VERSION "0.2"

NS_ :

BS_:

BU_: IFV_CWMP IFV_VFP External ExternalX
VAL_TABLE_ Status_Vision_Calib_Process_e 8 "DES_BAD_PARAMS_TARGET_HORIZON" 7 "DES_BAD_PARAMS_TARGET_YAW" 6 "DES_TOO_MANY_TARGETS_FOUND" 5 "DES_BAD_PARAMS" 4 "DES_BAD_PARAMS_SQUARE_SIDE_SIZE" 3 "DES_BAD_PARAMS_DISTANCE" 2 "DES_NO_TARGET_FOUND" 1 "DES_SUCCESS" 0 "DES_VISION_CALIB_UNKNOWN" ;
VAL_TABLE_ Vision_Align_State_T 4 "eVISION_APP_MODE" 3 "eWAIT_ALIGN_MSG" 2 "eWAIT_ALIGN_STATE" 1 "eVISION_UNALIGNED" 0 "eALIGNED_IDLE" ;
VAL_TABLE_ Mesp_Return_Status_T 5 "eDES_MESP_STATUS_ILLEGAL_CALL " 4 "eDES_STATUS_SERVICE_INVALID " 3 "eDES_STATUS_INVALID_PARAMETER" 2 "eDES_MESP_BUSY " 1 "eDES_MESP_GENERAL_ERR " 0 "eDES_MESP_STATUS_OK " ;
VAL_TABLE_ Mesp_MainState_T 134 "eMAIN_STATE_RUNNING_DIAGNOSTICS " 132 "eMAIN_STATE_PENDING_SPC " 130 "eMAIN_STATE_PENDING_TAC " 128 "eMAIN_STATE_PENDING_VISION " 34 "eRUNNING_SPC " 32 "eRUNNING_TAC " 3 "eBOOT " 2 "eRUNNING_VISON " 1 "ePENDING " 0 "eUKNOWN" ;

BO_ 3221225472 VECTOR__INDEPENDENT_SIG_MSG: 0 Vector__XXX
 SG_ Version_Info_MessageCounter : 0|2@1+ (1,0) [0|3] "" Vector__XXX
 SG_ CAN_Interface_Major_Version : 0|5@1+ (1,0) [0|255] "" Vector__XXX
 SG_ CAN_Interface_Minor_Version : 0|3@1+ (1,0) [0|255] "" Vector__XXX
 SG_ VIS_LANE_AMBIGUOUS_LANE_RIGHT : 0|1@1+ (1,0) [0|1] "" Vector__XXX
 SG_ VIS_LANE_AMBIGUOUS_LANE_LEFT : 0|1@1+ (1,0) [0|1] "" Vector__XXX
 SG_ VIS_LANE_LANE_CHANGE : 0|2@1+ (1,0) [0|3] "" Vector__XXX
 SG_ VIS_LANE_RIGHT_INDIVID_TJACONF : 0|2@1+ (1,0) [0|2] "" Vector__XXX
 SG_ VIS_LANE_RIGHT_INDIVID_LKACONF : 0|2@1+ (1,0) [0|2] "" Vector__XXX
 SG_ VIS_LANE_RIGHT_INDIVID_DIMONCONF : 0|1@1+ (1,0) [0|1] "" Vector__XXX
 SG_ VIS_LANE_RIGHT_PARALL_TJACONF : 0|2@1+ (1,0) [0|2] "" Vector__XXX
 SG_ VIS_LANE_RIGHT_PARALL_LKACONF : 0|2@1+ (1,0) [0|2] "" Vector__XXX
 SG_ VIS_LANE_RIGHT_PARALL_DIMONCONF : 0|1@1+ (1,0) [0|1] "" Vector__XXX
 SG_ VIS_LANE_LEFT_INDIVID_TJACONF : 0|2@1+ (1,0) [0|2] "" Vector__XXX
 SG_ VIS_LANE_LEFT_INDIVID_LKACONF : 0|2@1+ (1,0) [0|2] "" Vector__XXX
 SG_ VIS_LANE_LEFT_INDIVID_DIMONCONF : 0|1@1+ (1,0) [0|1] "" Vector__XXX
 SG_ VIS_LANE_LEFT_PARALL_TJACONF : 0|2@1+ (1,0) [0|2] "" Vector__XXX
 SG_ VIS_LANE_LEFT_PARALL_LKACONF : 0|2@1+ (1,0) [0|2] "" Vector__XXX
 SG_ VIS_LANE_LEFT_PARALL_DIMONCONF : 0|1@1+ (1,0) [0|1] "" Vector__XXX
 SG_ VIS_LANE_RIGHT_PARALL_TYPE : 0|4@1+ (1,0) [0|8] "" Vector__XXX
 SG_ VIS_LANE_RIGHT_INDIVID_TYPE : 0|4@1+ (1,0) [0|8] "" Vector__XXX
 SG_ VIS_LANE_LEFT_PARALL_TYPE : 0|4@1+ (1,0) [0|8] "" Vector__XXX
 SG_ VIS_LANE_LEFT_INDIVID_TYPE : 0|4@1+ (1,0) [0|8] "" Vector__XXX
 SG_ VIS_AHBC_CLOSEST_OBJECT_DISTANCE : 0|8@1+ (2,0) [0|510] "m" Vector__XXX
 SG_ VIS_AHBC_BOUND_NOGLARE_RIGHT_ST : 0|2@1+ (1,0) [0|3] "" Vector__XXX
 SG_ VIS_AHBC_BOUND_NOGLARE_RIGHT : 0|8@1+ (0.1,-20) [-20|20] "deg" Vector__XXX
 SG_ VIS_AHBC_BOUND_NOGLARE_LEFT_ST : 0|2@1+ (1,0) [0|3] "" Vector__XXX
 SG_ VIS_AHBC_BOUND_NOGLARE_LEFT : 0|12@1+ (0.1,-20) [-20|20] "deg" Vector__XXX
 SG_ VIS_AHBC_BOUND_NOGLARE_BTM_ST : 0|2@1+ (1,0) [0|3] "" Vector__XXX
 SG_ VIS_AHBC_BOUND_NOGLARE_BTM : 0|8@1+ (0.1,-10) [-10|10] "deg" Vector__XXX
 SG_ Latch_Fault_byte19_bit3 : 0|1@1+ (1,0) [0|1] "" Vector__XXX
 SG_ Latch_Fault_byte20_bit0 : 0|1@1+ (1,0) [0|1] "" Vector__XXX
 SG_ Latch_Fault_byte19_bit7 : 0|1@1+ (1,0) [0|0] "" Vector__XXX
 SG_ Latch_Fault_byte19_bit6 : 0|1@1+ (1,0) [0|1] "" Vector__XXX
 SG_ Latch_Fault_byte19_bit5 : 0|1@1+ (1,0) [0|1] "" Vector__XXX
 SG_ Latch_Fault_byte19_bit4 : 0|1@1+ (1,0) [0|1] "" Vector__XXX
 SG_ Latch_Fault_byte19_bit2 : 0|1@1+ (1,0) [0|0] "" Vector__XXX
 SG_ Latch_Fault_byte19_bit1 : 0|1@1+ (1,0) [0|0] "" Vector__XXX
 SG_ Latch_Fault_byte19_bit0 : 0|1@1+ (1,0) [0|0] "" Vector__XXX
 SG_ Latch_Fault_byte18_bit0 : 0|1@1+ (1,0) [0|1] "" Vector__XXX
 SG_ Latch_Fault_byte18_bit1 : 0|1@1+ (1,0) [0|1] "" Vector__XXX
 SG_ Latch_Fault_byte18_bit2 : 0|1@1+ (1,0) [0|1] "" Vector__XXX
 SG_ Latch_Fault_byte18_bit3 : 0|1@1+ (1,0) [0|1] "" Vector__XXX
 SG_ LaActlDeny_B_ActlQfError : 0|1@1+ (1,0) [0|1] "" Vector__XXX
 SG_ Latch_Fault_byte18_bit5 : 0|1@1+ (1,0) [0|1] "" Vector__XXX
 SG_ Latch_Fault_byte18_bit6 : 0|1@1+ (1,0) [0|1] "" Vector__XXX
 SG_ Latch_Fault_byte18_bit7 : 0|1@1+ (1,0) [0|1] "" Vector__XXX
 SG_ Latch_Fault_byte17_bit0 : 0|1@1+ (1,0) [0|1] "" Vector__XXX
 SG_ Latch_Fault_byte17_bit1 : 0|1@1+ (1,0) [0|1] "" Vector__XXX
 SG_ Latch_Fault_byte17_bit2 : 0|1@1+ (1,0) [0|1] "" Vector__XXX
 SG_ Latch_Fault_byte17_bit3 : 0|1@1+ (1,0) [0|1] "" Vector__XXX
 SG_ Latch_Fault_byte17_bit4 : 0|1@1+ (1,0) [0|1] "" Vector__XXX
 SG_ Latch_Fault_byte17_bit5 : 0|1@1+ (1,0) [0|1] "" Vector__XXX
 SG_ Latch_Fault_byte17_bit6 : 0|1@1+ (1,0) [0|1] "" Vector__XXX
 SG_ Latch_Fault_byte17_bit7 : 0|1@1+ (1,0) [0|1] "" Vector__XXX
 SG_ Latch_Fault_byte16_bit0 : 0|1@1+ (1,0) [0|1] "" Vector__XXX
 SG_ Latch_Fault_byte16_bit1 : 0|1@1+ (1,0) [0|1] "" Vector__XXX
 SG_ Latch_Fault_byte16_bit2 : 0|1@1+ (1,0) [0|1] "" Vector__XXX
 SG_ Latch_Fault_byte16_bit3 : 0|1@1+ (1,0) [0|1] "" Vector__XXX
 SG_ Latch_Fault_byte16_bit4 : 0|1@1+ (1,0) [0|1] "" Vector__XXX
 SG_ Latch_Fault_byte16_bit5 : 0|1@1+ (1,0) [0|1] "" Vector__XXX
 SG_ Latch_Fault_byte16_bit6 : 0|1@1+ (1,0) [0|1] "" Vector__XXX
 SG_ Latch_Fault_byte16_bit7 : 0|1@1+ (1,0) [0|1] "" Vector__XXX
 SG_ Latch_Fault_byte15_bit0 : 0|1@1+ (1,0) [0|1] "" Vector__XXX
 SG_ Latch_Fault_byte15_bit1 : 0|1@1+ (1,0) [0|1] "" Vector__XXX
 SG_ Latch_Fault_byte15_bit2 : 0|1@1+ (1,0) [0|1] "" Vector__XXX
 SG_ Latch_Fault_byte15_bit3 : 0|1@1+ (1,0) [0|1] "" Vector__XXX
 SG_ Latch_Fault_byte15_bit4 : 0|1@1+ (1,0) [0|1] "" Vector__XXX
 SG_ Latch_Fault_byte15_bit5 : 0|1@1+ (1,0) [0|1] "" Vector__XXX
 SG_ Latch_Fault_byte15_bit6 : 0|1@1+ (1,0) [0|1] "" Vector__XXX
 SG_ Latch_Fault_byte15_bit7 : 0|1@1+ (1,0) [0|1] "" Vector__XXX
 SG_ Latch_Fault_byte14_bit0 : 0|1@1+ (1,0) [0|1] "" Vector__XXX
 SG_ Latch_Fault_byte14_bit1 : 0|1@1+ (1,0) [0|1] "" Vector__XXX
 SG_ Latch_Fault_byte14_bit1 : 0|1@1+ (1,0) [0|1] "" Vector__XXX
 SG_ Latch_Fault_byte14_bit3 : 0|1@1+ (1,0) [0|1] "" Vector__XXX
 SG_ Latch_Fault_byte14_bit4 : 0|1@1+ (1,0) [0|1] "" Vector__XXX
 SG_ Latch_Fault_byte14_bit5 : 0|1@1+ (1,0) [0|1] "" Vector__XXX
 SG_ Latch_Fault_byte14_bit6 : 0|1@1+ (1,0) [0|1] "" Vector__XXX
 SG_ Latch_Fault_byte14_bit7 : 0|1@1+ (1,0) [0|1] "" Vector__XXX
 SG_ Active_Fault_byte20_bit0 : 0|1@1+ (1,0) [0|1] "" Vector__XXX
 SG_ Active_Fault_byte19_bit7 : 0|1@1+ (1,0) [0|0] "" Vector__XXX
 SG_ Active_Fault_byte19_bit6 : 0|1@1+ (1,0) [0|1] "" Vector__XXX
 SG_ Active_Fault_byte19_bit5 : 0|1@1+ (1,0) [0|1] "" Vector__XXX
 SG_ Active_Fault_byte19_bit4 : 0|1@1+ (1,0) [0|1] "" Vector__XXX
 SG_ Active_Fault_byte19_bit3 : 0|1@1+ (1,0) [0|1] "" Vector__XXX
 SG_ Active_Fault_byte19_bit2 : 0|1@1+ (1,0) [0|0] "" Vector__XXX
 SG_ Active_Fault_byte19_bit1 : 0|1@1+ (1,0) [0|0] "" Vector__XXX
 SG_ Active_Fault_byte19_bit0 : 0|1@1+ (1,0) [0|0] "" Vector__XXX
 SG_ Active_Fault_byte18_bit0 : 0|1@1+ (1,0) [0|1] "" Vector__XXX
 SG_ Active_Fault_byte18_bit1 : 0|1@1+ (1,0) [0|1] "" Vector__XXX
 SG_ Active_Fault_byte18_bit2 : 0|1@1+ (1,0) [0|1] "" Vector__XXX
 SG_ Active_Fault_byte18_bit3 : 0|1@1+ (1,0) [0|1] "" Vector__XXX
 SG_ Active_Fault_byte18_bit4 : 0|1@1+ (1,0) [0|1] "" Vector__XXX
 SG_ Active_Fault_byte18_bit5 : 0|1@1+ (1,0) [0|1] "" Vector__XXX
 SG_ Active_Fault_byte18_bit6 : 0|1@1+ (1,0) [0|1] "" Vector__XXX
 SG_ Active_Fault_byte18_bit7 : 0|1@1+ (1,0) [0|1] "" Vector__XXX
 SG_ Active_Fault_byte17_bit0 : 0|1@1+ (1,0) [0|1] "" Vector__XXX
 SG_ Active_Fault_byte17_bit1 : 0|1@1+ (1,0) [0|1] "" Vector__XXX
 SG_ Active_Fault_byte17_bit2 : 0|1@1+ (1,0) [0|1] "" Vector__XXX
 SG_ Active_Fault_byte17_bit3 : 0|1@1+ (1,0) [0|1] "" Vector__XXX
 SG_ Active_Fault_byte17_bit4 : 0|1@1+ (1,0) [0|1] "" Vector__XXX
 SG_ Active_Fault_byte17_bit5 : 0|1@1+ (1,0) [0|1] "" Vector__XXX
 SG_ Active_Fault_byte17_bit6 : 0|1@1+ (1,0) [0|1] "" Vector__XXX
 SG_ Active_Fault_byte17_bit7 : 0|1@1+ (1,0) [0|1] "" Vector__XXX
 SG_ Active_Fault_byte16_bit0 : 0|1@1+ (1,0) [0|1] "" Vector__XXX
 SG_ Active_Fault_byte16_bit1 : 0|1@1+ (1,0) [0|1] "" Vector__XXX
 SG_ Active_Fault_byte16_bit2 : 0|1@1+ (1,0) [0|1] "" Vector__XXX
 SG_ Active_Fault_byte16_bit3 : 0|1@1+ (1,0) [0|1] "" Vector__XXX
 SG_ Active_Fault_byte16_bit4 : 0|1@1+ (1,0) [0|1] "" Vector__XXX
 SG_ Active_Fault_byte16_bit5 : 0|1@1+ (1,0) [0|1] "" Vector__XXX
 SG_ Active_Fault_byte16_bit6 : 0|1@1+ (1,0) [0|1] "" Vector__XXX
 SG_ Active_Fault_byte16_bit7 : 0|1@1+ (1,0) [0|1] "" Vector__XXX
 SG_ Active_Fault_byte15_bit0 : 0|1@1+ (1,0) [0|1] "" Vector__XXX
 SG_ Active_Fault_byte15_bit1 : 0|1@1+ (1,0) [0|1] "" Vector__XXX
 SG_ Active_Fault_byte15_bit2 : 0|1@1+ (1,0) [0|1] "" Vector__XXX
 SG_ Active_Fault_byte15_bit3 : 0|1@1+ (1,0) [0|1] "" Vector__XXX
 SG_ Active_Fault_byte15_bit4 : 0|1@1+ (1,0) [0|1] "" Vector__XXX
 SG_ Active_Fault_byte15_bit5 : 0|1@1+ (1,0) [0|1] "" Vector__XXX
 SG_ Active_Fault_byte15_bit6 : 0|1@1+ (1,0) [0|1] "" Vector__XXX
 SG_ Active_Fault_byte15_bit7 : 0|1@1+ (1,0) [0|1] "" Vector__XXX
 SG_ Active_Fault_byte14_bit0 : 0|1@1+ (1,0) [0|1] "" Vector__XXX
 SG_ Active_Fault_byte14_bit1 : 0|1@1+ (1,0) [0|1] "" Vector__XXX
 SG_ Active_Fault_byte14_bit2 : 0|1@1+ (1,0) [0|1] "" Vector__XXX
 SG_ Active_Fault_byte14_bit3 : 0|1@1+ (1,0) [0|1] "" Vector__XXX
 SG_ Active_Fault_byte14_bit4 : 0|1@1+ (1,0) [0|1] "" Vector__XXX
 SG_ Active_Fault_byte14_bit5 : 0|1@1+ (1,0) [0|1] "" Vector__XXX
 SG_ Active_Fault_byte14_bit6 : 0|1@1+ (1,0) [0|1] "" Vector__XXX
 SG_ Active_Fault_byte14_bit7 : 0|1@1+ (1,0) [0|1] "" Vector__XXX
 SG_ LKA_Handcode_diag : 0|1@1- (1,0) [0|1] "" Vector__XXX
 SG_ VBattState_VR_HTR : 0|4@1+ (1,0) [0|15] "" Vector__XXX
 SG_ RawHeatrFltA2D : 0|12@1+ (1,0) [0|4095] "" Vector__XXX
 SG_ RawHeaterOutA2D : 0|12@1+ (1,0) [0|4095] "" Vector__XXX
 SG_ HtrDrv : 0|1@1+ (1,0) [0|1] "" Vector__XXX
 SG_ HeaterSTGOpenFailure_HP : 0|1@1+ (1,0) [0|1] "" Vector__XXX
 SG_ HeaterOutputShortCircuit_HP : 0|1@1+ (1,0) [0|1] "" Vector__XXX
 SG_ HeaterOutpurOpenCircuit_HP : 0|1@1+ (1,0) [0|1] "" Vector__XXX
 SG_ heavy_rain_failsafe : 0|1@1+ (1,0) [0|1] "" Vector__XXX
 SG_ heavy_rain_failsafe_A : 0|1@1+ (1,0) [0|1] "" Vector__XXX
 SG_ History_Fault_bD_0 : 0|1@1+ (1,0) [0|1] "" Vector__XXX
 SG_ Active_Fault_byteD_bit0 : 0|1@1+ (1,0) [0|1] "" Vector__XXX
 SG_ Active_Fault_A_b21_5 : 0|1@1+ (1,0) [0|1] "" Vector__XXX
 SG_ Active_Fault_A_b21_6 : 0|1@1+ (1,0) [0|1] "" Vector__XXX
 SG_ Active_Fault_A_b21_7 : 0|1@1+ (1,0) [0|1] "" Vector__XXX
 SG_ History_Fault_H_b21_5 : 0|1@1+ (1,0) [0|1] "" Vector__XXX
 SG_ History_Fault_H_b21_6 : 0|1@1+ (1,0) [0|1] "" Vector__XXX
 SG_ History_Fault_H_b21_7 : 0|1@1+ (1,0) [0|1] "" Vector__XXX
 SG_ History_Fault_b1E_7 : 0|1@1+ (1,0) [0|1] "" Vector__XXX
 SG_ History_Fault_b1D_3 : 0|1@1+ (1,0) [0|1] "" Vector__XXX
 SG_ History_Fault_b1D_4 : 0|1@1+ (1,0) [0|1] "" Vector__XXX
 SG_ History_Fault_b1D_5 : 0|1@1+ (1,0) [0|1] "" Vector__XXX
 SG_ History_Fault_b1D_6 : 0|1@1+ (1,0) [0|1] "" Vector__XXX
 SG_ History_Fault_b1D_7 : 0|1@1+ (1,0) [0|1] "" Vector__XXX
 SG_ History_Fault_b1C_7 : 0|1@1+ (1,0) [0|1] "" Vector__XXX
 SG_ History_Fault_b1A_3 : 0|1@1+ (1,0) [0|1] "" Vector__XXX
 SG_ History_Fault_H_b18_3 : 0|1@1+ (1,0) [0|1] "" Vector__XXX
 SG_ History_Fault_H_b16_2 : 0|1@1+ (1,0) [0|1] "" Vector__XXX
 SG_ History_Fault_H_b14_1 : 0|1@1+ (1,0) [0|1] "" Vector__XXX
 SG_ History_Fault_H_b14_2 : 0|1@1+ (1,0) [0|1] "" Vector__XXX
 SG_ History_Fault_H_b14_3 : 0|1@1+ (1,0) [0|1] "" Vector__XXX
 SG_ History_Fault_H_b10_0 : 0|1@1+ (1,0) [0|1] "" Vector__XXX
 SG_ History_Fault_H_b10_4 : 0|1@1+ (1,0) [0|1] "" Vector__XXX
 SG_ History_Fault_H_b10_6 : 0|1@1+ (1,0) [0|1] "" Vector__XXX
 SG_ History_Fault_H_b10_7 : 0|1@1+ (1,0) [0|1] "" Vector__XXX
 SG_ History_Fault_b6_2 : 0|1@1+ (1,0) [0|1] "" Vector__XXX
 SG_ History_Fault_b6_4 : 0|1@1+ (1,0) [0|1] "" Vector__XXX
 SG_ History_Fault_b1_7 : 0|1@1+ (1,0) [0|1] "" Vector__XXX
 SG_ History_Fault_b0_0 : 0|1@1+ (1,0) [0|1] "" Vector__XXX
 SG_ Active_Fault_b1E_7 : 0|1@1+ (1,0) [0|1] "" Vector__XXX
 SG_ Active_Fault_b1D_3 : 0|1@1+ (1,0) [0|1] "" Vector__XXX
 SG_ Active_Fault_b1D_4 : 0|1@1+ (1,0) [0|1] "" Vector__XXX
 SG_ Active_Fault_b1D_5 : 0|1@1+ (1,0) [0|1] "" Vector__XXX
 SG_ Active_Fault_b1D_6 : 0|1@1+ (1,0) [0|1] "" Vector__XXX
 SG_ Active_Fault_b1D_7 : 0|1@1+ (1,0) [0|1] "" Vector__XXX
 SG_ Active_Fault_b1C_7 : 0|1@1+ (1,0) [0|1] "" Vector__XXX
 SG_ Active_Fault_b1A_3 : 0|1@1+ (1,0) [0|1] "" Vector__XXX
 SG_ Active_Fault_A_b18_3 : 0|1@1+ (1,0) [0|1] "" Vector__XXX
 SG_ Active_Fault_A_b16_2 : 0|1@1+ (1,0) [0|1] "" Vector__XXX
 SG_ Active_Fault_A_b14_1 : 0|1@1+ (1,0) [0|1] "" Vector__XXX
 SG_ Active_Fault_A_b14_2 : 0|1@1+ (1,0) [0|1] "" Vector__XXX
 SG_ Active_Fault_A_b14_3 : 0|1@1+ (1,0) [0|1] "" Vector__XXX
 SG_ Active_Fault_A_b10_0 : 0|1@1+ (1,0) [0|1] "" Vector__XXX
 SG_ Active_Fault_A_b10_4 : 0|1@1+ (1,0) [0|1] "" Vector__XXX
 SG_ Active_Fault_A_b10_6 : 0|1@1+ (1,0) [0|1] "" Vector__XXX
 SG_ Active_Fault_A_b10_7 : 0|1@1+ (1,0) [0|1] "" Vector__XXX
 SG_ Active_Fault_b6_2 : 0|1@1+ (1,0) [0|1] "" Vector__XXX
 SG_ Active_Fault_b6_4 : 0|1@1+ (1,0) [0|1] "" Vector__XXX
 SG_ Active_Fault_byte1_bit7 : 0|1@1+ (1,0) [0|1] "" Vector__XXX
 SG_ Active_Fault_byte0_bit0 : 0|1@1+ (1,0) [0|1] "" Vector__XXX
 SG_ History_Fault_H_bF_4 : 0|1@1+ (1,0) [0|1] "" Vector__XXX
 SG_ History_Fault_H_bF_5 : 0|1@1+ (1,0) [0|1] "" Vector__XXX
 SG_ History_Fault_H_bF_6 : 0|1@1+ (1,0) [0|1] "" Vector__XXX
 SG_ History_Fault_H_bF_7 : 0|1@1+ (1,0) [0|1] "" Vector__XXX
 SG_ History_Fault_H_bE_7 : 0|1@1+ (1,0) [0|1] "" Vector__XXX
 SG_ History_Fault_bD_1 : 0|1@1+ (1,0) [0|1] "" Vector__XXX
 SG_ History_Fault_bD_2 : 0|1@1+ (1,0) [0|1] "" Vector__XXX
 SG_ History_Fault_bC_0 : 0|1@1+ (1,0) [0|1] "" Vector__XXX
 SG_ History_Fault_H_bC_1 : 0|1@1+ (1,0) [0|1] "" Vector__XXX
 SG_ History_Fault_bC_4 : 0|1@1+ (1,0) [0|1] "" Vector__XXX
 SG_ History_Fault_bC_7 : 0|1@1+ (1,0) [0|1] "" Vector__XXX
 SG_ History_Fault_bB_7 : 0|1@1+ (1,0) [0|1] "" Vector__XXX
 SG_ History_Fault_b9_4 : 0|1@1+ (1,0) [0|1] "" Vector__XXX
 SG_ History_Fault_b9_6 : 0|1@1+ (1,0) [0|1] "" Vector__XXX
 SG_ History_Fault_b8_0 : 0|1@1+ (1,0) [0|1] "" Vector__XXX
 SG_ History_Fault_b8_1 : 0|1@1+ (1,0) [0|1] "" Vector__XXX
 SG_ History_Fault_b8_2 : 0|1@1+ (1,0) [0|1] "" Vector__XXX
 SG_ Active_Fault_A_bF_4 : 0|1@1+ (1,0) [0|1] "" Vector__XXX
 SG_ Active_Fault_A_bF_5 : 0|1@1+ (1,0) [0|1] "" Vector__XXX
 SG_ Active_Fault_A_bF_6 : 0|1@1+ (1,0) [0|1] "" Vector__XXX
 SG_ Active_Fault_A_bF_7 : 0|1@1+ (1,0) [0|1] "" Vector__XXX
 SG_ Active_Fault_A_bE_7 : 0|1@1+ (1,0) [0|1] "" Vector__XXX
 SG_ Active_Fault_byteD_bit1 : 0|1@1+ (1,0) [0|1] "" Vector__XXX
 SG_ Active_Fault_byteD_bit2 : 0|1@1+ (1,0) [0|1] "" Vector__XXX
 SG_ Active_Fault_bC_0 : 0|1@1+ (1,0) [0|1] "" Vector__XXX
 SG_ Active_Fault_A_bC_1 : 0|1@1+ (1,0) [0|1] "" Vector__XXX
 SG_ Active_Fault_byteC_bit4 : 0|1@1+ (1,0) [0|1] "" Vector__XXX
 SG_ Active_Fault_byteC_bit7 : 0|1@1+ (1,0) [0|1] "" Vector__XXX
 SG_ Active_Fault_bB_7 : 0|1@1+ (1,0) [0|1] "" Vector__XXX
 SG_ Active_Fault_b9_4 : 0|1@1+ (1,0) [0|1] "" Vector__XXX
 SG_ Active_Fault_b9_6 : 0|1@1+ (1,0) [0|1] "" Vector__XXX
 SG_ Active_Fault_byte8_bit0 : 0|1@1+ (1,0) [0|1] "" Vector__XXX
 SG_ Active_Fault_byte8_bit1 : 0|1@1+ (1,0) [0|1] "" Vector__XXX
 SG_ Active_Fault_byte8_bit2 : 0|1@1+ (1,0) [0|1] "" Vector__XXX
 SG_ PB_185_VehStbMiss_H_b15_1 : 0|1@1+ (1,0) [0|1] "" Vector__XXX
 SG_ PB_185_VehStbMiss_A_b15_1 : 0|1@1+ (1,0) [0|1] "" Vector__XXX

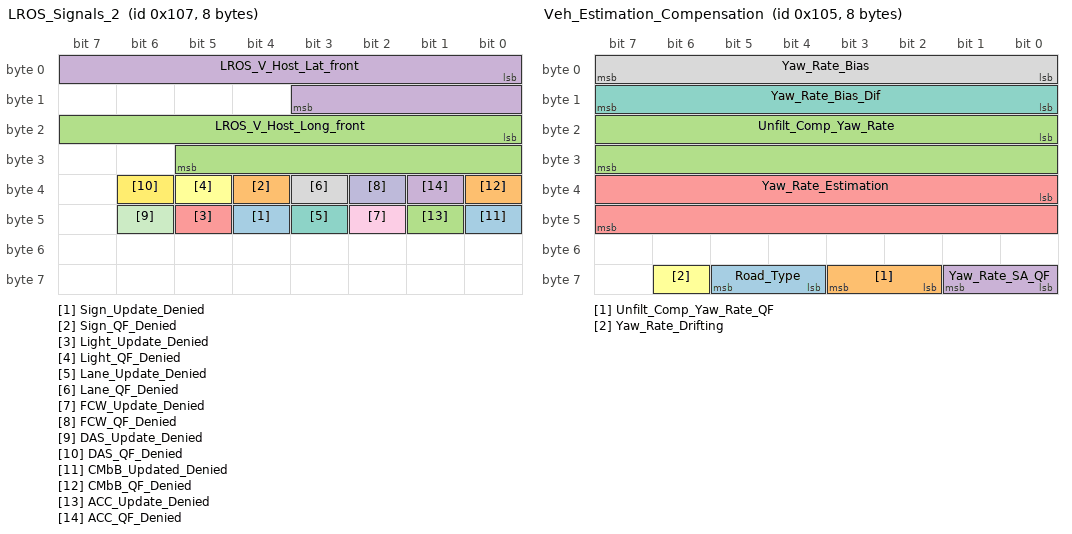
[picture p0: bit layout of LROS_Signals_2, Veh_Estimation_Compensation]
BO_ 263 LROS_Signals_2: 8 IFV_CWMP
 SG_ Sign_Update_Denied : 44|1@1+ (1,0) [0|1] ""  External
 SG_ Sign_QF_Denied : 36|1@1+ (1,0) [0|1] ""  External
 SG_ LROS_V_Host_Long_front : 16|14@1- (0.01,0) [-20|100] "m/s"  External
 SG_ LROS_V_Host_Lat_front : 0|12@1- (0.01,0) [-20|20] "m/s"  External
 SG_ Light_Update_Denied : 45|1@1+ (1,0) [0|1] ""  External
 SG_ Light_QF_Denied : 37|1@1+ (1,0) [0|1] ""  External
 SG_ Lane_Update_Denied : 43|1@1+ (1,0) [0|1] ""  External
 SG_ Lane_QF_Denied : 35|1@1+ (1,0) [0|1] ""  External
 SG_ FCW_Update_Denied : 42|1@1+ (1,0) [0|1] ""  External
 SG_ FCW_QF_Denied : 34|1@1+ (1,0) [0|1] ""  External
 SG_ DAS_Update_Denied : 46|1@1+ (1,0) [0|1] ""  External
 SG_ DAS_QF_Denied : 38|1@1+ (1,0) [0|1] ""  External
 SG_ CMbB_Updated_Denied : 40|1@1+ (1,0) [0|1] ""  External
 SG_ CMbB_QF_Denied : 32|1@1+ (1,0) [0|1] ""  External
 SG_ ACC_Update_Denied : 41|1@1+ (1,0) [0|1] ""  External
 SG_ ACC_QF_Denied : 33|1@1+ (1,0) [0|1] ""  External

BO_ 262 LROS_Signals_1: 8 IFV_CWMP
 SG_ LROSStatus_bit2 : 50|1@1+ (1,0) [0|1] ""  External
 SG_ LROSStatus_bit10 : 58|1@1+ (1,0) [0|1] ""  External
 SG_ VisionAlignmentOutOfRange : 52|1@1+ (1,0) [0|1] ""  External
 SG_ VisionSystemNotOperational : 49|1@1+ (1,0) [0|1] ""  External
 SG_ VisionExternalConditionsNotOK : 59|1@1+ (1,0) [0|1] ""  External
 SG_ VisionBlockageDetected : 54|1@1+ (1,0) [0|1] ""  External
 SG_ VisionAlignmentNotStarted : 63|1@1+ (1,0) [0|1] ""  External
 SG_ VisionAlignmentIncomplete : 62|1@1+ (1,0) [0|1] ""  External
 SG_ SensorDataUpdating : 55|1@1+ (1,0) [0|1] ""  External
 SG_ RadarExternalConditionsNotOK : 57|1@1+ (1,0) [0|1] ""  External
 SG_ RadarBlockageDetected : 53|1@1+ (1,0) [0|1] ""  External
 SG_ RadarAlignmentOutOfRange : 51|1@1+ (1,0) [0|1] ""  External
 SG_ RadarAlignmentNotStarted : 61|1@1+ (1,0) [0|1] ""  External
 SG_ RadarAlignmentIncomplete : 60|1@1+ (1,0) [0|1] ""  External
 SG_ CommunicationError : 56|1@1+ (1,0) [0|1] ""  External
 SG_ RadarSystemNotOperational : 48|1@1+ (1,0) [0|1] ""  External
 SG_ LROS_YawRate_Est : 32|15@1- (0.000174533,0) [-2|2] "rad/s"  External
 SG_ LROS_YawRate : 16|15@1- (0.000174533,0) [-2|2] "rad/s"  External
 SG_ LROS_FiltVehicleSpeedOverGround : 0|14@1+ (0.01,0) [0|100] "m/s"  External

BO_ 261 Veh_Estimation_Compensation: 8 IFV_CWMP
 SG_ Road_Type : 60|2@1+ (1,0) [0|3] ""  External
 SG_ Unfilt_Comp_Yaw_Rate_QF : 58|2@1+ (1,0) [0|3] ""  External
 SG_ Unfilt_Comp_Yaw_Rate : 16|16@1- (0.00306,0) [-100|100.26702] "deg/s"  External
 SG_ Yaw_Rate_SA_QF : 56|2@1+ (1,0) [0|3] ""  External
 SG_ Yaw_Rate_Estimation : 32|16@1- (0.00306,0) [-100.27008|100.26702] "deg/s"  External
 SG_ Yaw_Rate_Drifting : 62|1@1+ (1,0) [0|1] ""  External
 SG_ Yaw_Rate_Bias_Dif : 8|8@1- (0.015625,0) [-2|1.984375] "deg/s"  External
 SG_ Yaw_Rate_Bias : 0|8@1- (0.0273,0) [-3.4944|3.4671] "deg/s"  External

BO_ 1796 DASP_Counters: 8 IFV_VFP
 SG_ VfpSpiMsgRxBadSeqCtr : 40|8@1+ (1,0) [0|255] ""  External
 SG_ VfpSpiMsgRxBadHdrCtr : 32|8@1+ (1,0) [0|255] ""  External
 SG_ VfpSpiMsg11RxCtr : 16|16@1+ (1,0) [0|65535] ""  External
 SG_ VfpSpiMsg10RxCtr : 0|16@1+ (1,0) [0|65535] ""  External

BO_ 526 Host_CAN_Output_Timestamp: 8 IFV_CWMP
 SG_ CAN_LROS_TRIGGER_TIMESTAMP_LSB : 0|28@1+ (1,0) [0|268435455] ""  External
 SG_ CAN_LROS_T_TRACKER_INDEX_LSB : 40|12@1+ (1,0) [0|4095] ""  External
 SG_ CAN_LROS_T_LOOK_INDEX_LSB : 52|12@1+ (1,0) [0|4095] ""  External
 SG_ CAN_LROS_T_FRAME_INDEX_LSB : 28|12@1+ (1,0) [0|4095] ""  External

BO_ 525 Host_LROS_Trigger_Timestamp: 8 IFV_CWMP
 SG_ CAN_LROS_OUTPUT_TIMESTAMP_LSB : 0|28@1+ (1,0) [0|268435455] ""  External
 SG_ CAN_LROS_O_TRACKER_INDEX_LSB : 40|12@1+ (1,0) [0|4095] ""  External
 SG_ CAN_LROS_O_LOOK_INDEX_LSB : 52|12@1+ (1,0) [0|4095] ""  External
 SG_ CAN_LROS_O_FRAME_INDEX_LSB : 28|12@1+ (1,0) [0|4095] ""  External

BO_ 570 IPC_Vis_Function_Msg_Host_TS: 8 IFV_VFP
 SG_ CAN_IPC_TIMESTAMP_VIS_H : 32|32@1+ (1,0) [0|4294967295] "ms"  External
 SG_ CAN_IPC_REF_INDEX_VIS_H : 16|16@1+ (1,0) [0|65535] ""  External
 SG_ CAN_IPC_REF_INDEX_2_VIS_H : 0|16@1+ (1,0) [0|65535] ""  External

BO_ 568 IPC_Tsel_Msg_Host_TS: 8 IFV_VFP
 SG_ CAN_IPC_TIMESTAMP_TSEL_H : 32|32@1+ (1,0) [0|4294967295] "ms"  External
 SG_ CAN_IPC_REF_INDEX_TSEL_H : 16|16@1+ (1,0) [0|65535] ""  External
 SG_ CAN_IPC_REF_INDEX_2_TSEL_H : 0|16@1+ (1,0) [0|65535] ""  External

BO_ 567 IPC_TrafficSigns_Msg_Host_TS: 8 IFV_VFP
 SG_ CAN_IPC_TIMESTAMP_TRAFF_H : 32|32@1+ (1,0) [0|4294967295] "ms"  External
 SG_ CAN_IPC_REF_INDEX_TRAFF_H : 16|16@1+ (1,0) [0|65535] ""  External
 SG_ CAN_IPC_REF_INDEX_2_TRAFF_H : 0|16@1+ (1,0) [0|65535] ""  External

BO_ 566 IPC_RoadData_msg_Host_TS: 8 IFV_VFP
 SG_ CAN_IPC_TIMESTAMP_ROAD_H : 32|32@1+ (1,0) [0|4294967295] "ms"  External
 SG_ CAN_IPC_REF_INDEX_ROAD_H : 16|16@1+ (1,0) [0|65535] ""  External

BO_ 565 IPC_Objects_Msg_Host_TS: 8 IFV_VFP
 SG_ CAN_IPC_TIMESTAMP_OBJ_H : 32|32@1+ (1,0) [0|4294967295] "ms"  External
 SG_ CAN_IPC_REF_INDEX_OBJ_H : 16|16@1+ (1,0) [0|65535] ""  External

BO_ 564 IPC_LightSenData_Msg_Host_TS: 8 IFV_VFP
 SG_ CAN_IPC_TIMESTAMP_LIGHT_H : 32|32@1+ (1,0) [0|4294967295] "ms"  External
 SG_ CAN_IPC_REF_INDEX_LIGHT_H : 16|16@1+ (1,0) [0|65535] ""  External

BO_ 563 IPC_FusedPedObj_Msg_Host_TS: 8 IFV_VFP
 SG_ CAN_IPC_TIMESTAMP_FUS_H : 32|32@1+ (1,0) [0|4294967295] "ms"  External
 SG_ CAN_IPC_REF_INDEX_FUS_H : 16|16@1+ (1,0) [0|65535] ""  External
 SG_ CAN_IPC_REF_INDEX_2_FUS_H : 0|16@1+ (1,0) [0|65535] ""  External

BO_ 755 XCP_CWMP_SLAVE_DAQ: 8 IFV_CWMP
 SG_ xcp_cwmp_slave_daq_byte_7 : 63|8@0+ (1,0) [0|255] ""  External
 SG_ xcp_cwmp_slave_daq_byte_6 : 55|8@0+ (1,0) [0|255] ""  External
 SG_ xcp_cwmp_slave_daq_byte_5 : 47|8@0+ (1,0) [0|255] ""  External
 SG_ xcp_cwmp_slave_daq_byte_4 : 39|8@0+ (1,0) [0|255] ""  External
 SG_ xcp_cwmp_slave_daq_byte_3 : 31|8@0+ (1,0) [0|255] ""  External
 SG_ xcp_cwmp_slave_daq_byte_2 : 23|8@0+ (1,0) [0|255] ""  External
 SG_ xcp_cwmp_slave_daq_byte_1 : 15|8@0+ (1,0) [0|255] ""  External
 SG_ xcp_cwmp_slave_daq_byte_0 : 7|8@0+ (1,0) [0|255] ""  External

BO_ 256 SWP3_Version_Number: 8 IFV_CWMP
 SG_ SWP3_PART_NUMBER_SUFFIX : 0|40@1+ (1,0) [0|1099511627775] ""  External
 SG_ SWP3_CAL_MINOR_REVISION : 48|8@1+ (1,0) [0|255] ""  External
 SG_ SWP3_CAL_MAJOR_REVISION : 40|8@1+ (1,0) [0|255] ""  External
 SG_ SWP3_CAL_FIELD_REVISION : 56|8@1+ (1,0) [0|255] ""  External

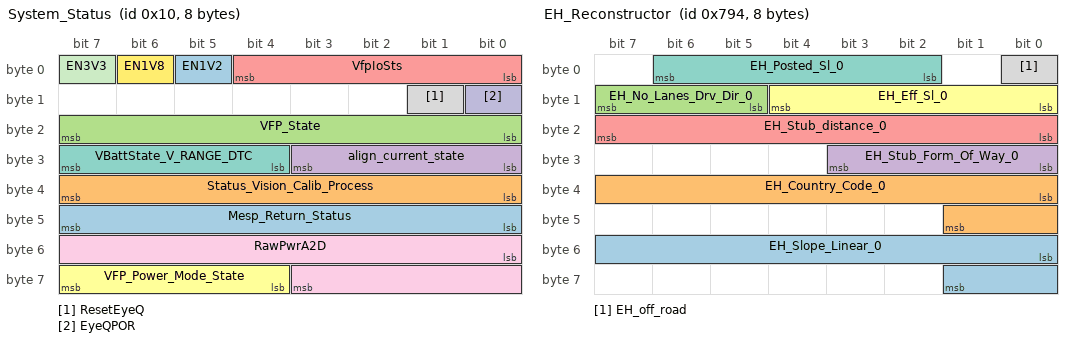
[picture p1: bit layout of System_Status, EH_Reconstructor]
BO_ 16 System_Status: 8 IFV_CWMP
 SG_ Mesp_Return_Status : 47|8@0+ (1,0) [0|0] "" Vector__XXX
 SG_ Status_Vision_Calib_Process : 39|8@0+ (1,0) [0|0] "" Vector__XXX
 SG_ VFP_State : 23|8@0+ (1,0) [0|0] "" Vector__XXX
 SG_ align_current_state : 27|4@0+ (1,0) [0|0] "" Vector__XXX
 SG_ VfpIoSts : 0|5@1+ (1,0) [0|31] ""  External
 SG_ VFP_Power_Mode_State : 60|4@1+ (1,0) [0|15] ""  External
 SG_ VBattState_V_RANGE_DTC : 28|4@1+ (1,0) [0|15] ""  External
 SG_ ResetEyeQ : 9|1@1+ (1,0) [0|1] ""  External
 SG_ RawPwrA2D : 48|12@1+ (1,0) [0|4095] ""  External
 SG_ EyeQPOR : 8|1@1+ (1,0) [0|1] ""  External
 SG_ EN3V3 : 7|1@1+ (1,0) [0|1] ""  External
 SG_ EN1V8 : 6|1@1+ (1,0) [0|1] ""  External
 SG_ EN1V2 : 5|1@1+ (1,0) [0|1] ""  External

BO_ 1031 Radar_VSYNC_CWMP_Timestamp: 8 IFV_VFP
 SG_ CAN_RADAR_LOOK_TIMESTAMP_CWMP : 32|32@1+ (1,0) [0|4294967295] "ms"  External
 SG_ CAN_RADAR_LOOK_INDEX_VSYNC_CWMP : 0|16@1+ (1,0) [0|65535] ""  External

BO_ 1030 Radar_VSYNC_Timestamp: 8 IFV_VFP
 SG_ CAN_RADAR_LOOK_TIMESTAMP_VFP : 32|32@1+ (1,0) [0|4294967295] "ms"  External
 SG_ CAN_RADAR_LOOK_INDEX_VSYNC : 0|16@1+ (1,0) [0|65535] ""  External

BO_ 264 VFP_Fault_Message_0: 8 IFV_VFP
 SG_ ETSEL_TRACK_OOR_0_A_b7_0 : 56|1@1+ (1,0) [0|1] ""  External
 SG_ ETSEL_TRACK_OOR_1_A_b7_1 : 57|1@1+ (1,0) [0|1] ""  External
 SG_ ETSEL_TRACK_OOR_2_A_b7_2 : 58|1@1+ (1,0) [0|1] ""  External
 SG_ ETSEL_TRACK_OOR_3_A_b7_3 : 59|1@1+ (1,0) [0|1] ""  External
 SG_ ETSEL_TRACK_OOR_4_A_b7_4 : 60|1@1+ (1,0) [0|1] ""  External
 SG_ ETSEL_TRACK_OOR_5_A_b7_5 : 61|1@1+ (1,0) [0|1] ""  External
 SG_ VISION_BRAKING_FLAG_OOR_0_A_b6_0 : 48|1@1+ (1,0) [0|1] ""  External
 SG_ VISION_BRAKING_FLAG_OOR_1_A_b6_1 : 49|1@1+ (1,0) [0|1] ""  External
 SG_ VISION_BRAKING_FLAG_OOR_2_A_b6_2 : 50|1@1+ (1,0) [0|1] ""  External
 SG_ VISION_BRAKING_FLAG_OOR_3_A_b6_3 : 51|1@1+ (1,0) [0|1] ""  External
 SG_ VISION_BRAKING_FLAG_OOR_4_A_b6_4 : 52|1@1+ (1,0) [0|1] ""  External
 SG_ SUBSYSTEMCOMMUNICATIONFAULT_A_b5 : 45|1@1+ (1,0) [0|1] ""  External
 SG_ PARAMETERSINVALID_A_b5_6 : 46|1@1+ (1,0) [0|1] ""  External
 SG_ BLURIMAGEFAILSAFE_A_b3_0 : 24|1@1+ (1,0) [0|1] ""  External
 SG_ FLRMISALIGNMENT_A_b3_1 : 25|1@1+ (1,0) [0|1] ""  External
 SG_ HEAVYRAINFAILSAFE_A_b : 26|1@1+ (1,0) [0|1] ""  External
 SG_ INVALIDSPDYAWDETECTED_A_b3_3 : 27|1@1+ (1,0) [0|1] ""  External
 SG_ VISION_PARTIAL_BLOCKAGE_A_b3_4 : 28|1@1+ (1,0) [0|1] ""  External
 SG_ RADARVISCORRELATIONFAILSAFE_A_b3 : 29|1@1+ (1,0) [0|1] ""  External
 SG_ ROLLANGLEFAILSAFE_A_b3_6 : 30|1@1+ (1,0) [0|1] ""  External
 SG_ IMMAGERPATTERN_A_b3_7 : 31|1@1+ (1,0) [0|1] ""  External
 SG_ SWP5_INVALID_A_b2_0 : 16|1@1+ (1,0) [0|1] ""  External
 SG_ SWP3_INVALID_A_b2_1 : 17|1@1+ (1,0) [0|1] ""  External
 SG_ INITGENERALFAILURE_A_b1_0 : 8|1@1+ (1,0) [0|1] ""  External
 SG_ INITVDIFAILURE_A_b1_1 : 9|1@1+ (1,0) [0|1] ""  External
 SG_ INITI2CFAILURE_A_b1_2 : 10|1@1+ (1,0) [0|1] ""  External
 SG_ GRABRELEASEFAILURE_A_b1_7 : 15|1@1+ (1,0) [0|1] ""  External
 SG_ PCAN_IF_INCOMPATIBILITY_A_b0_0 : 0|1@1+ (1,0) [0|1] ""  External
 SG_ PCAN_MISSING_MSG_A_b0_1 : 1|1@1+ (1,0) [0|1] ""  External
 SG_ PCAN_RANGE_CHECK_FAILURE_A_b0_2 : 2|1@1+ (1,0) [0|1] ""  External
 SG_ PCAN_INVALID_DATA_MSG_A_b0_3 : 3|1@1+ (1,0) [0|1] ""  External
 SG_ PCAN_DETECTION_INVALID_A_b0_4 : 4|1@1+ (1,0) [0|1] ""  External

BO_ 1940 EH_Reconstructor: 8 IFV_CWMP
 SG_ EH_Slope_Linear_0 : 48|10@1+ (1,0) [0|1023] ""  External
 SG_ EH_Country_Code_0 : 32|10@1+ (1,0) [0|1023] ""  External
 SG_ EH_No_Lanes_Drv_Dir_0 : 13|3@1+ (1,0) [0|7] ""  External
 SG_ EH_Stub_Form_Of_Way_0 : 24|4@1+ (1,0) [0|14] ""  External
 SG_ EH_Stub_distance_0 : 16|8@1+ (1,0) [0|255] "m"  External
 SG_ EH_Eff_Sl_0 : 8|5@1+ (1,0) [0|31] ""  External
 SG_ EH_Posted_Sl_0 : 2|5@1+ (1,0) [0|31] ""  External
 SG_ EH_off_road : 0|1@1+ (1,0) [0|1] ""  External

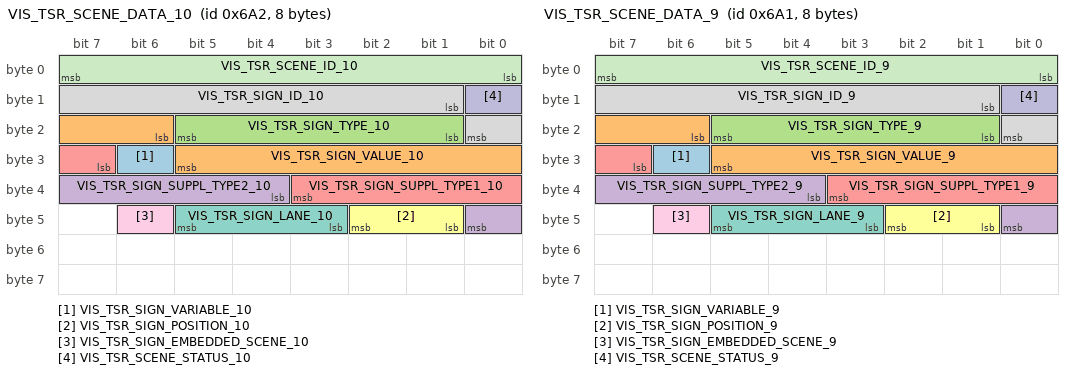
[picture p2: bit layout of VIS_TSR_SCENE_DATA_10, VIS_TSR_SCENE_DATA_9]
BO_ 1698 VIS_TSR_SCENE_DATA_10: 8 IFV_CWMP
 SG_ VIS_TSR_SIGN_VARIABLE_10 : 30|1@1+ (1,0) [0|1] ""  External
 SG_ VIS_TSR_SIGN_VALUE_10 : 22|8@1+ (1,0) [0|255] ""  External
 SG_ VIS_TSR_SIGN_TYPE_10 : 17|5@1+ (1,0) [0|27] ""  External
 SG_ VIS_TSR_SIGN_SUPPL_TYPE2_10 : 36|5@1+ (1,0) [0|24] ""  External
 SG_ VIS_TSR_SIGN_SUPPL_TYPE1_10 : 31|5@1+ (1,0) [0|24] ""  External
 SG_ VIS_TSR_SIGN_POSITION_10 : 41|2@1+ (1,0) [0|2] ""  External
 SG_ VIS_TSR_SIGN_LANE_10 : 43|3@1+ (1,0) [0|6] ""  External
 SG_ VIS_TSR_SIGN_ID_10 : 9|8@1+ (1,0) [0|255] ""  External
 SG_ VIS_TSR_SIGN_EMBEDDED_SCENE_10 : 46|1@1+ (1,0) [0|1] ""  External
 SG_ VIS_TSR_SCENE_STATUS_10 : 8|1@1+ (1,0) [0|1] ""  External
 SG_ VIS_TSR_SCENE_ID_10 : 0|8@1+ (1,0) [0|255] ""  External

BO_ 1697 VIS_TSR_SCENE_DATA_9: 8 IFV_CWMP
 SG_ VIS_TSR_SIGN_VARIABLE_9 : 30|1@1+ (1,0) [0|1] ""  External
 SG_ VIS_TSR_SIGN_VALUE_9 : 22|8@1+ (1,0) [0|255] ""  External
 SG_ VIS_TSR_SIGN_TYPE_9 : 17|5@1+ (1,0) [0|27] ""  External
 SG_ VIS_TSR_SIGN_SUPPL_TYPE2_9 : 36|5@1+ (1,0) [0|24] ""  External
 SG_ VIS_TSR_SIGN_SUPPL_TYPE1_9 : 31|5@1+ (1,0) [0|24] ""  External
 SG_ VIS_TSR_SIGN_POSITION_9 : 41|2@1+ (1,0) [0|2] ""  External
 SG_ VIS_TSR_SIGN_LANE_9 : 43|3@1+ (1,0) [0|6] ""  External
 SG_ VIS_TSR_SIGN_ID_9 : 9|8@1+ (1,0) [0|255] ""  External
 SG_ VIS_TSR_SIGN_EMBEDDED_SCENE_9 : 46|1@1+ (1,0) [0|1] ""  External
 SG_ VIS_TSR_SCENE_STATUS_9 : 8|1@1+ (1,0) [0|1] ""  External
 SG_ VIS_TSR_SCENE_ID_9 : 0|8@1+ (1,0) [0|255] ""  External

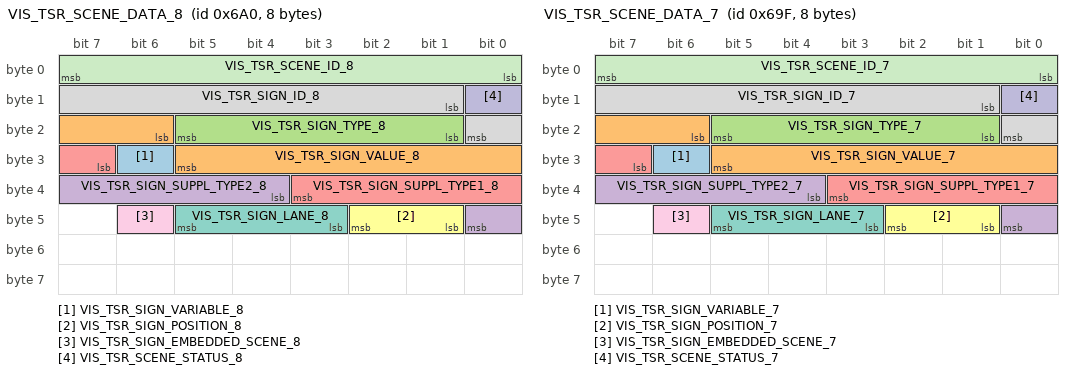
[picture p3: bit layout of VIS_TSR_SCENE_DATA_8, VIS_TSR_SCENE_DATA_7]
BO_ 1696 VIS_TSR_SCENE_DATA_8: 8 IFV_CWMP
 SG_ VIS_TSR_SIGN_VARIABLE_8 : 30|1@1+ (1,0) [0|1] ""  External
 SG_ VIS_TSR_SIGN_VALUE_8 : 22|8@1+ (1,0) [0|255] ""  External
 SG_ VIS_TSR_SIGN_TYPE_8 : 17|5@1+ (1,0) [0|27] ""  External
 SG_ VIS_TSR_SIGN_SUPPL_TYPE2_8 : 36|5@1+ (1,0) [0|24] ""  External
 SG_ VIS_TSR_SIGN_SUPPL_TYPE1_8 : 31|5@1+ (1,0) [0|24] ""  External
 SG_ VIS_TSR_SIGN_POSITION_8 : 41|2@1+ (1,0) [0|2] ""  External
 SG_ VIS_TSR_SIGN_LANE_8 : 43|3@1+ (1,0) [0|6] ""  External
 SG_ VIS_TSR_SIGN_ID_8 : 9|8@1+ (1,0) [0|255] ""  External
 SG_ VIS_TSR_SIGN_EMBEDDED_SCENE_8 : 46|1@1+ (1,0) [0|1] ""  External
 SG_ VIS_TSR_SCENE_STATUS_8 : 8|1@1+ (1,0) [0|1] ""  External
 SG_ VIS_TSR_SCENE_ID_8 : 0|8@1+ (1,0) [0|255] ""  External

BO_ 1695 VIS_TSR_SCENE_DATA_7: 8 IFV_CWMP
 SG_ VIS_TSR_SIGN_VARIABLE_7 : 30|1@1+ (1,0) [0|1] ""  External
 SG_ VIS_TSR_SIGN_VALUE_7 : 22|8@1+ (1,0) [0|255] ""  External
 SG_ VIS_TSR_SIGN_TYPE_7 : 17|5@1+ (1,0) [0|27] ""  External
 SG_ VIS_TSR_SIGN_SUPPL_TYPE2_7 : 36|5@1+ (1,0) [0|24] ""  External
 SG_ VIS_TSR_SIGN_SUPPL_TYPE1_7 : 31|5@1+ (1,0) [0|24] ""  External
 SG_ VIS_TSR_SIGN_POSITION_7 : 41|2@1+ (1,0) [0|2] ""  External
 SG_ VIS_TSR_SIGN_LANE_7 : 43|3@1+ (1,0) [0|6] ""  External
 SG_ VIS_TSR_SIGN_ID_7 : 9|8@1+ (1,0) [0|255] ""  External
 SG_ VIS_TSR_SIGN_EMBEDDED_SCENE_7 : 46|1@1+ (1,0) [0|1] ""  External
 SG_ VIS_TSR_SCENE_STATUS_7 : 8|1@1+ (1,0) [0|1] ""  External
 SG_ VIS_TSR_SCENE_ID_7 : 0|8@1+ (1,0) [0|255] ""  External

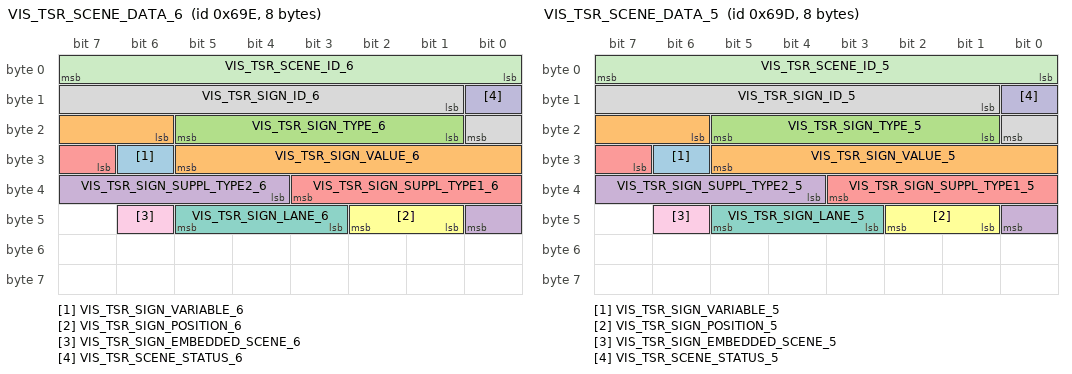
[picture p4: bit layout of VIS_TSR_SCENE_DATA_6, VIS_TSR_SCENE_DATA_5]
BO_ 1694 VIS_TSR_SCENE_DATA_6: 8 IFV_CWMP
 SG_ VIS_TSR_SIGN_VARIABLE_6 : 30|1@1+ (1,0) [0|1] ""  External
 SG_ VIS_TSR_SIGN_VALUE_6 : 22|8@1+ (1,0) [0|255] ""  External
 SG_ VIS_TSR_SIGN_TYPE_6 : 17|5@1+ (1,0) [0|27] ""  External
 SG_ VIS_TSR_SIGN_SUPPL_TYPE2_6 : 36|5@1+ (1,0) [0|24] ""  External
 SG_ VIS_TSR_SIGN_SUPPL_TYPE1_6 : 31|5@1+ (1,0) [0|24] ""  External
 SG_ VIS_TSR_SIGN_POSITION_6 : 41|2@1+ (1,0) [0|2] ""  External
 SG_ VIS_TSR_SIGN_LANE_6 : 43|3@1+ (1,0) [0|6] ""  External
 SG_ VIS_TSR_SIGN_ID_6 : 9|8@1+ (1,0) [0|255] ""  External
 SG_ VIS_TSR_SIGN_EMBEDDED_SCENE_6 : 46|1@1+ (1,0) [0|1] ""  External
 SG_ VIS_TSR_SCENE_STATUS_6 : 8|1@1+ (1,0) [0|1] ""  External
 SG_ VIS_TSR_SCENE_ID_6 : 0|8@1+ (1,0) [0|255] ""  External

BO_ 1693 VIS_TSR_SCENE_DATA_5: 8 IFV_CWMP
 SG_ VIS_TSR_SIGN_VARIABLE_5 : 30|1@1+ (1,0) [0|1] ""  External
 SG_ VIS_TSR_SIGN_VALUE_5 : 22|8@1+ (1,0) [0|255] ""  External
 SG_ VIS_TSR_SIGN_TYPE_5 : 17|5@1+ (1,0) [0|27] ""  External
 SG_ VIS_TSR_SIGN_SUPPL_TYPE2_5 : 36|5@1+ (1,0) [0|24] ""  External
 SG_ VIS_TSR_SIGN_SUPPL_TYPE1_5 : 31|5@1+ (1,0) [0|24] ""  External
 SG_ VIS_TSR_SIGN_POSITION_5 : 41|2@1+ (1,0) [0|2] ""  External
 SG_ VIS_TSR_SIGN_LANE_5 : 43|3@1+ (1,0) [0|6] ""  External
 SG_ VIS_TSR_SIGN_ID_5 : 9|8@1+ (1,0) [0|255] ""  External
 SG_ VIS_TSR_SIGN_EMBEDDED_SCENE_5 : 46|1@1+ (1,0) [0|1] ""  External
 SG_ VIS_TSR_SCENE_STATUS_5 : 8|1@1+ (1,0) [0|1] ""  External
 SG_ VIS_TSR_SCENE_ID_5 : 0|8@1+ (1,0) [0|255] ""  External

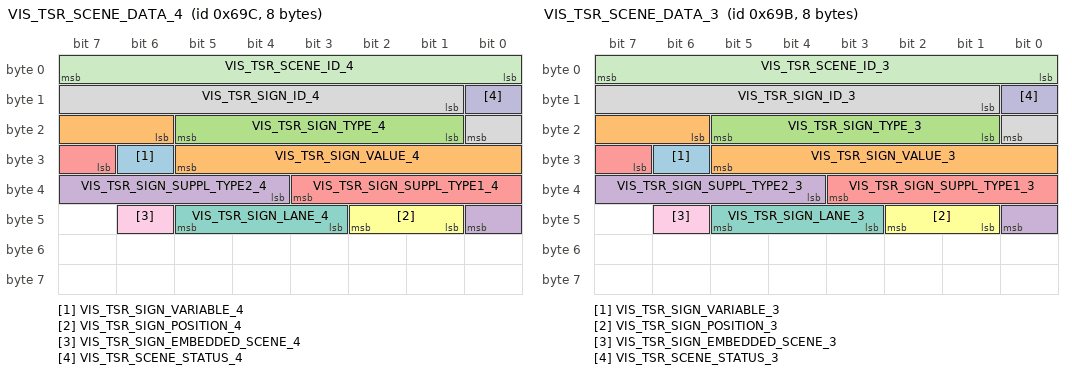
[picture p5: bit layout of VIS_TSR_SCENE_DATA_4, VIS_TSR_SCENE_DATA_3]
BO_ 1692 VIS_TSR_SCENE_DATA_4: 8 IFV_CWMP
 SG_ VIS_TSR_SIGN_VARIABLE_4 : 30|1@1+ (1,0) [0|1] ""  External
 SG_ VIS_TSR_SIGN_VALUE_4 : 22|8@1+ (1,0) [0|255] ""  External
 SG_ VIS_TSR_SIGN_TYPE_4 : 17|5@1+ (1,0) [0|27] ""  External
 SG_ VIS_TSR_SIGN_SUPPL_TYPE2_4 : 36|5@1+ (1,0) [0|24] ""  External
 SG_ VIS_TSR_SIGN_SUPPL_TYPE1_4 : 31|5@1+ (1,0) [0|24] ""  External
 SG_ VIS_TSR_SIGN_POSITION_4 : 41|2@1+ (1,0) [0|2] ""  External
 SG_ VIS_TSR_SIGN_LANE_4 : 43|3@1+ (1,0) [0|6] ""  External
 SG_ VIS_TSR_SIGN_ID_4 : 9|8@1+ (1,0) [0|255] ""  External
 SG_ VIS_TSR_SIGN_EMBEDDED_SCENE_4 : 46|1@1+ (1,0) [0|1] ""  External
 SG_ VIS_TSR_SCENE_STATUS_4 : 8|1@1+ (1,0) [0|1] ""  External
 SG_ VIS_TSR_SCENE_ID_4 : 0|8@1+ (1,0) [0|255] ""  External

BO_ 1691 VIS_TSR_SCENE_DATA_3: 8 IFV_CWMP
 SG_ VIS_TSR_SIGN_VARIABLE_3 : 30|1@1+ (1,0) [0|1] ""  External
 SG_ VIS_TSR_SIGN_VALUE_3 : 22|8@1+ (1,0) [0|255] ""  External
 SG_ VIS_TSR_SIGN_TYPE_3 : 17|5@1+ (1,0) [0|27] ""  External
 SG_ VIS_TSR_SIGN_SUPPL_TYPE2_3 : 36|5@1+ (1,0) [0|24] ""  External
 SG_ VIS_TSR_SIGN_SUPPL_TYPE1_3 : 31|5@1+ (1,0) [0|24] ""  External
 SG_ VIS_TSR_SIGN_POSITION_3 : 41|2@1+ (1,0) [0|2] ""  External
 SG_ VIS_TSR_SIGN_LANE_3 : 43|3@1+ (1,0) [0|6] ""  External
 SG_ VIS_TSR_SIGN_ID_3 : 9|8@1+ (1,0) [0|255] ""  External
 SG_ VIS_TSR_SIGN_EMBEDDED_SCENE_3 : 46|1@1+ (1,0) [0|1] ""  External
 SG_ VIS_TSR_SCENE_STATUS_3 : 8|1@1+ (1,0) [0|1] ""  External
 SG_ VIS_TSR_SCENE_ID_3 : 0|8@1+ (1,0) [0|255] ""  External

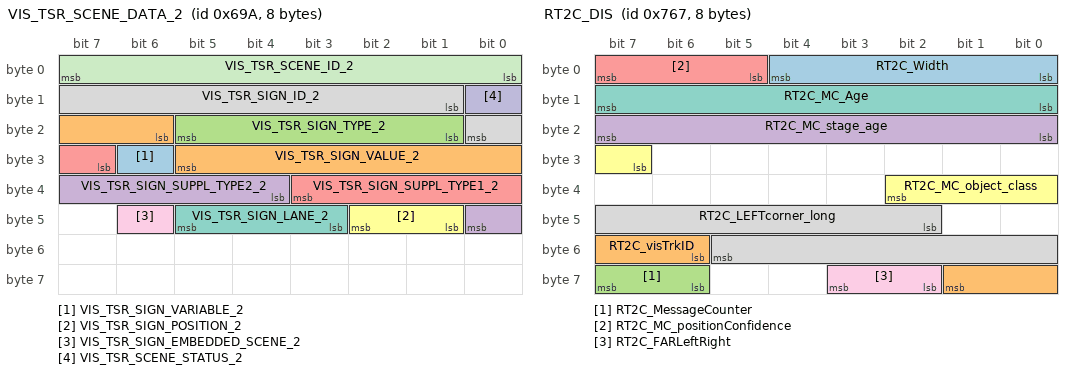
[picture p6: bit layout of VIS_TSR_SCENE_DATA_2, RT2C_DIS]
BO_ 1690 VIS_TSR_SCENE_DATA_2: 8 IFV_CWMP
 SG_ VIS_TSR_SIGN_VARIABLE_2 : 30|1@1+ (1,0) [0|1] ""  External
 SG_ VIS_TSR_SIGN_VALUE_2 : 22|8@1+ (1,0) [0|255] ""  External
 SG_ VIS_TSR_SIGN_TYPE_2 : 17|5@1+ (1,0) [0|27] ""  External
 SG_ VIS_TSR_SIGN_SUPPL_TYPE2_2 : 36|5@1+ (1,0) [0|24] ""  External
 SG_ VIS_TSR_SIGN_SUPPL_TYPE1_2 : 31|5@1+ (1,0) [0|24] ""  External
 SG_ VIS_TSR_SIGN_POSITION_2 : 41|2@1+ (1,0) [0|2] ""  External
 SG_ VIS_TSR_SIGN_LANE_2 : 43|3@1+ (1,0) [0|6] ""  External
 SG_ VIS_TSR_SIGN_ID_2 : 9|8@1+ (1,0) [0|255] ""  External
 SG_ VIS_TSR_SIGN_EMBEDDED_SCENE_2 : 46|1@1+ (1,0) [0|1] ""  External
 SG_ VIS_TSR_SCENE_STATUS_2 : 8|1@1+ (1,0) [0|1] ""  External
 SG_ VIS_TSR_SCENE_ID_2 : 0|8@1+ (1,0) [0|255] ""  External

BO_ 1895 RT2C_DIS: 8 IFV_CWMP
 SG_ RT2C_Width : 0|5@1+ (0.1,0) [0|3] "m"  External
 SG_ RT2C_visTrkID : 54|4@1+ (1,0) [0|15] ""  External
 SG_ RT2C_MessageCounter : 62|2@1+ (1,0) [0|3] ""  External
 SG_ RT2C_MC_stage_age : 16|8@1+ (1,0) [0|255] ""  External
 SG_ RT2C_MC_positionConfidence : 5|3@1+ (1,0) [0|2] ""  External
 SG_ RT2C_MC_object_class : 31|4@1+ (1,0) [0|10] ""  External
 SG_ RT2C_MC_Age : 8|8@1+ (1,0) [0|255] ""  External
 SG_ RT2C_LEFTcorner_long : 42|12@1+ (0.1,-50) [-50|160] "m"  External
 SG_ RT2C_FARLeftRight : 58|2@1+ (1,0) [0|2] ""  External

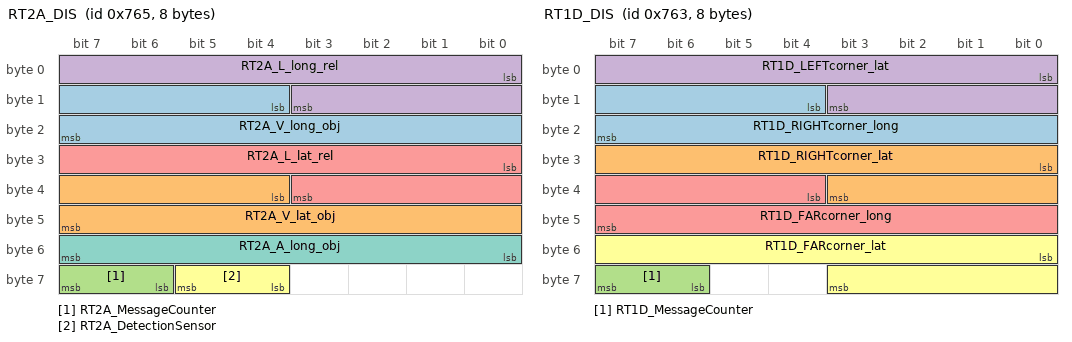
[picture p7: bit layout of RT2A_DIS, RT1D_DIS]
BO_ 1893 RT2A_DIS: 8 IFV_CWMP
 SG_ RT2A_V_long_obj : 12|12@1+ (0.05,-100) [-100|100] "m/s"  External
 SG_ RT2A_V_lat_obj : 36|12@1+ (0.025,-20) [-20|20] "m/s"  External
 SG_ RT2A_MessageCounter : 62|2@1+ (1,0) [0|3] ""  External
 SG_ RT2A_L_long_rel : 0|12@1+ (0.1,0) [0|180] "m"  External
 SG_ RT2A_L_lat_rel : 24|12@1+ (0.1,-50) [-50|50] "m"  External
 SG_ RT2A_DetectionSensor : 60|2@1+ (1,0) [0|3] ""  External
 SG_ RT2A_A_long_obj : 48|8@1+ (0.1,-12.5) [-12.5|12.5] "m/s^2"  External

BO_ 1891 RT1D_DIS: 8 IFV_CWMP
 SG_ RT1D_RIGHTcorner_long : 12|12@1+ (0.1,-50) [-50|160] "m"  External
 SG_ RT1D_RIGHTcorner_lat : 24|12@1+ (0.1,-50) [-50|50] "m"  External
 SG_ RT1D_MessageCounter : 62|2@1+ (1,0) [0|3] ""  External
 SG_ RT1D_LEFTcorner_lat : 0|12@1+ (0.1,-50) [-50|50] "m"  External
 SG_ RT1D_FARcorner_long : 36|12@1+ (0.1,-50) [-50|160] "m"  External
 SG_ RT1D_FARcorner_lat : 48|12@1+ (0.1,-50) [-50|50] "m"  External

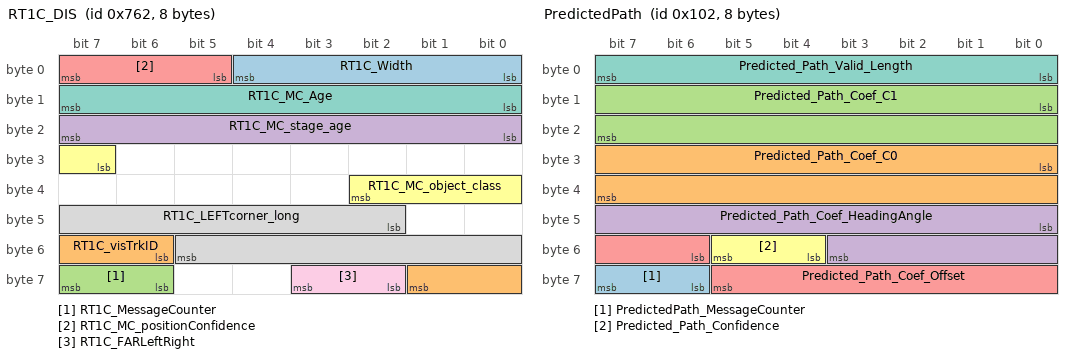
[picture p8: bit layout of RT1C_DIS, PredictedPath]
BO_ 1890 RT1C_DIS: 8 IFV_CWMP
 SG_ RT1C_Width : 0|5@1+ (0.1,0) [0|3] "m"  External
 SG_ RT1C_visTrkID : 54|4@1+ (1,0) [0|15] ""  External
 SG_ RT1C_MessageCounter : 62|2@1+ (1,0) [0|3] ""  External
 SG_ RT1C_MC_stage_age : 16|8@1+ (1,0) [0|255] ""  External
 SG_ RT1C_MC_positionConfidence : 5|3@1+ (1,0) [0|2] ""  External
 SG_ RT1C_MC_object_class : 31|4@1+ (1,0) [0|10] ""  External
 SG_ RT1C_MC_Age : 8|8@1+ (1,0) [0|255] ""  External
 SG_ RT1C_LEFTcorner_long : 42|12@1+ (0.1,-50) [-50|160] "m"  External
 SG_ RT1C_FARLeftRight : 58|2@1+ (1,0) [0|2] ""  External

BO_ 1027 Pedestrian_1C: 8 IFV_CWMP
 SG_ P1C_visTrkID : 20|4@1+ (1,0) [0|15] ""  External
 SG_ P1C_Stage_age : 1|8@1+ (1,0) [0|255] ""  External
 SG_ P1C_Object_class : 16|4@1+ (1,0) [0|10] ""  External

BO_ 1025 Pedestrian_1A: 8 IFV_CWMP
 SG_ P1A_V_long_obj : 20|12@1+ (0.05,-100) [-100|100] "m/s"  External
 SG_ P1A_TrackID : 1|7@1+ (1,0) [0|64] ""  External
 SG_ P1A_L_long_rel : 8|12@1+ (0.05,0) [0|180] "m"  External
 SG_ P1A_L_lat_rel : 44|14@1+ (0.01,-50) [-50|50] "m"  External
 SG_ P1A_A_long_obj : 32|12@1+ (0.01,-20) [-20|20] "m/s^2"  External

BO_ 258 PredictedPath: 8 IFV_CWMP
 SG_ PredictedPath_MessageCounter : 62|2@1+ (1,0) [0|3] ""  External
 SG_ Predicted_Path_Coef_C0 : 24|16@1+ (1E-005,-0.2) [-0.2|0.2] ""  External
 SG_ Predicted_Path_Coef_C1 : 8|16@1+ (1E-006,-0.002) [-0.002|0.002] ""  External
 SG_ Predicted_Path_Coef_HeadingAngle : 40|12@1+ (0.0005,-1.004) [-1.004|1.004] ""  External
 SG_ Predicted_Path_Coef_Offset : 54|8@1+ (0.025,-3) [-3|3.375] "m"  External
 SG_ Predicted_Path_Confidence : 52|2@1+ (1,0) [0|3] ""  External
 SG_ Predicted_Path_Valid_Length : 0|8@1+ (1,0) [0|200] "m"  External

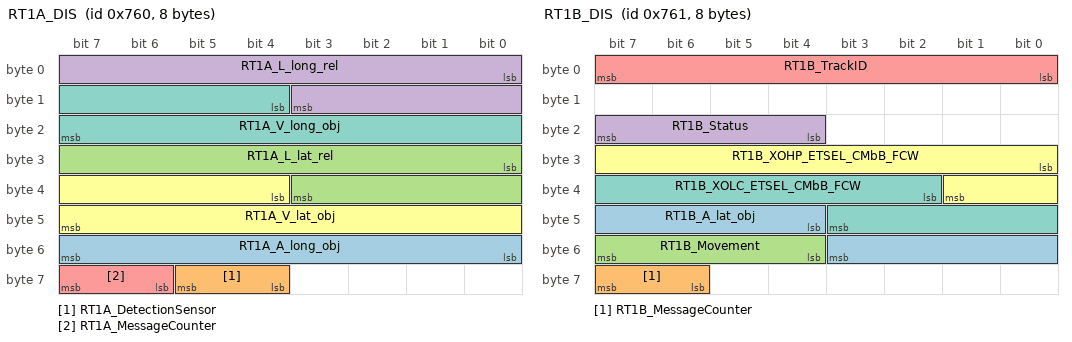
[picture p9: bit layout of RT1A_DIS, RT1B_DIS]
BO_ 1888 RT1A_DIS: 8 IFV_CWMP
 SG_ RT1A_A_long_obj : 48|8@1+ (0.1,-12.5) [-12.5|12.5] "m/s^2"  External
 SG_ RT1A_DetectionSensor : 60|2@1+ (1,0) [0|3] ""  External
 SG_ RT1A_L_lat_rel : 24|12@1+ (0.1,-50) [-50|50] "m"  External
 SG_ RT1A_L_long_rel : 0|12@1+ (0.1,0) [0|180] "m"  External
 SG_ RT1A_MessageCounter : 62|2@1+ (1,0) [0|3] ""  External
 SG_ RT1A_V_lat_obj : 36|12@1+ (0.025,-20) [-20|20] "m/s"  External
 SG_ RT1A_V_long_obj : 12|12@1+ (0.05,-100) [-100|100] "m/s"  External

BO_ 1889 RT1B_DIS: 8 IFV_CWMP
 SG_ RT1B_A_lat_obj : 44|8@1+ (0.1,-10) [-10|10] "m/s^2"  External
 SG_ RT1B_MessageCounter : 62|2@1+ (1,0) [0|3] ""  External
 SG_ RT1B_Movement : 52|4@1+ (1,0) [0|15] ""  External
 SG_ RT1B_Status : 20|4@1+ (1,0) [0|7] ""  External
 SG_ RT1B_TrackID : 0|8@1+ (1,0) [0|64] ""  External
 SG_ RT1B_XOHP_ETSEL_CMbB_FCW : 24|10@1+ (0.1,-50) [-50|50] "m"  External
 SG_ RT1B_XOLC_ETSEL_CMbB_FCW : 34|10@1+ (0.1,-50) [-50|50] "m"  External

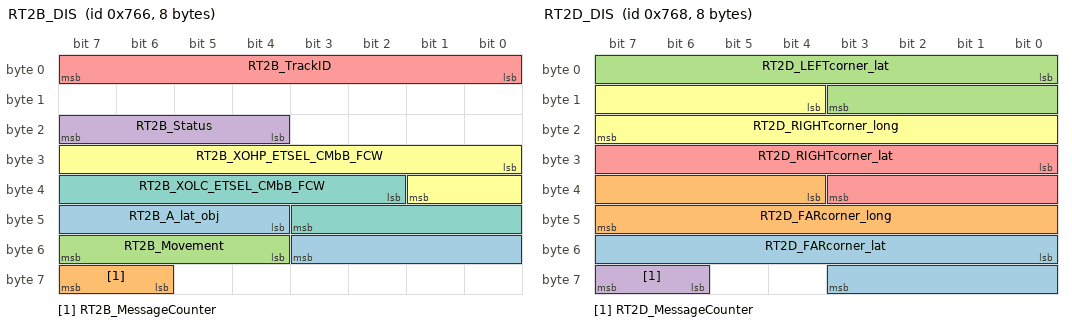
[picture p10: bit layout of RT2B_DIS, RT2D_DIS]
BO_ 1894 RT2B_DIS: 8 IFV_CWMP
 SG_ RT2B_A_lat_obj : 44|8@1+ (0.1,-10) [-10|10] "m/s^2"  External
 SG_ RT2B_MessageCounter : 62|2@1+ (1,0) [0|3] ""  External
 SG_ RT2B_Movement : 52|4@1+ (1,0) [0|15] ""  External
 SG_ RT2B_Status : 20|4@1+ (1,0) [0|7] ""  External
 SG_ RT2B_TrackID : 0|8@1+ (1,0) [0|64] ""  External
 SG_ RT2B_XOHP_ETSEL_CMbB_FCW : 24|10@1+ (0.1,-50) [-50|50] "m"  External
 SG_ RT2B_XOLC_ETSEL_CMbB_FCW : 34|10@1+ (0.1,-50) [-50|50] "m"  External

BO_ 1896 RT2D_DIS: 8 IFV_CWMP
 SG_ RT2D_FARcorner_lat : 48|12@1+ (0.1,-50) [-50|50] "m"  External
 SG_ RT2D_FARcorner_long : 36|12@1+ (0.1,-50) [-50|160] "m"  External
 SG_ RT2D_LEFTcorner_lat : 0|12@1+ (0.1,-50) [-50|50] "m"  External
 SG_ RT2D_MessageCounter : 62|2@1+ (1,0) [0|3] ""  External
 SG_ RT2D_RIGHTcorner_lat : 24|12@1+ (0.1,-50) [-50|50] "m"  External
 SG_ RT2D_RIGHTcorner_long : 12|12@1+ (0.1,-50) [-50|160] "m"  External

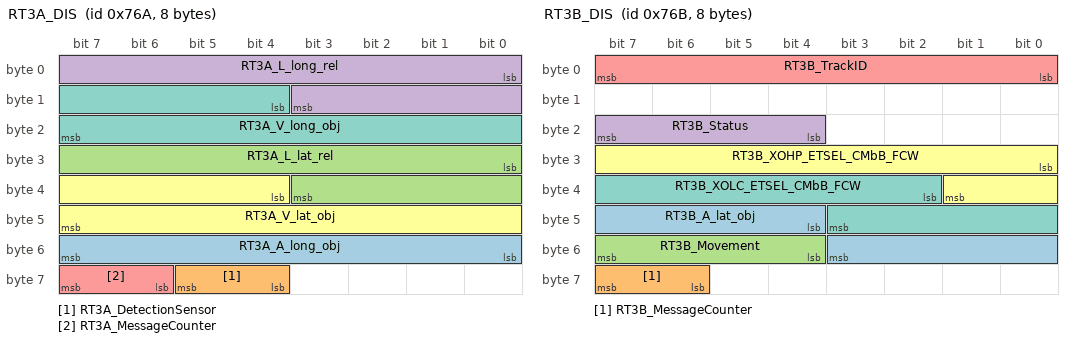
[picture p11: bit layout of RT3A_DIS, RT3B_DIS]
BO_ 1898 RT3A_DIS: 8 IFV_CWMP
 SG_ RT3A_A_long_obj : 48|8@1+ (0.1,-12.5) [-12.5|12.5] "m/s^2"  External
 SG_ RT3A_DetectionSensor : 60|2@1+ (1,0) [0|3] ""  External
 SG_ RT3A_L_lat_rel : 24|12@1+ (0.1,-50) [-50|50] "m"  External
 SG_ RT3A_L_long_rel : 0|12@1+ (0.1,0) [0|180] "m"  External
 SG_ RT3A_MessageCounter : 62|2@1+ (1,0) [0|3] ""  External
 SG_ RT3A_V_lat_obj : 36|12@1+ (0.025,-20) [-20|20] "m/s"  External
 SG_ RT3A_V_long_obj : 12|12@1+ (0.05,-100) [-100|100] "m/s"  External

BO_ 1899 RT3B_DIS: 8 IFV_CWMP
 SG_ RT3B_A_lat_obj : 44|8@1+ (0.1,-10) [-10|10] "m/s^2"  External
 SG_ RT3B_MessageCounter : 62|2@1+ (1,0) [0|3] ""  External
 SG_ RT3B_Movement : 52|4@1+ (1,0) [0|15] ""  External
 SG_ RT3B_Status : 20|4@1+ (1,0) [0|7] ""  External
 SG_ RT3B_TrackID : 0|8@1+ (1,0) [0|64] ""  External
 SG_ RT3B_XOHP_ETSEL_CMbB_FCW : 24|10@1+ (0.1,-50) [-50|50] "m"  External
 SG_ RT3B_XOLC_ETSEL_CMbB_FCW : 34|10@1+ (0.1,-50) [-50|50] "m"  External

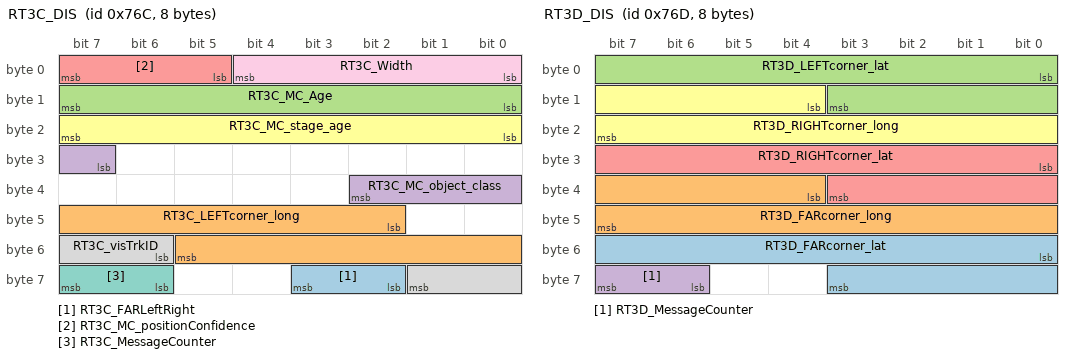
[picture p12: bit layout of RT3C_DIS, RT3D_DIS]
BO_ 1900 RT3C_DIS: 8 IFV_CWMP
 SG_ RT3C_FARLeftRight : 58|2@1+ (1,0) [0|2] ""  External
 SG_ RT3C_LEFTcorner_long : 42|12@1+ (0.1,-50) [-50|160] "m"  External
 SG_ RT3C_MC_Age : 8|8@1+ (1,0) [0|255] ""  External
 SG_ RT3C_MC_object_class : 31|4@1+ (1,0) [0|10] ""  External
 SG_ RT3C_MC_positionConfidence : 5|3@1+ (1,0) [0|2] ""  External
 SG_ RT3C_MC_stage_age : 16|8@1+ (1,0) [0|255] ""  External
 SG_ RT3C_MessageCounter : 62|2@1+ (1,0) [0|3] ""  External
 SG_ RT3C_visTrkID : 54|4@1+ (1,0) [0|15] ""  External
 SG_ RT3C_Width : 0|5@1+ (0.1,0) [0|3] "m"  External

BO_ 1901 RT3D_DIS: 8 IFV_CWMP
 SG_ RT3D_FARcorner_lat : 48|12@1+ (0.1,-50) [-50|50] "m"  External
 SG_ RT3D_FARcorner_long : 36|12@1+ (0.1,-50) [-50|160] "m"  External
 SG_ RT3D_LEFTcorner_lat : 0|12@1+ (0.1,-50) [-50|50] "m"  External
 SG_ RT3D_MessageCounter : 62|2@1+ (1,0) [0|3] ""  External
 SG_ RT3D_RIGHTcorner_lat : 24|12@1+ (0.1,-50) [-50|50] "m"  External
 SG_ RT3D_RIGHTcorner_long : 12|12@1+ (0.1,-50) [-50|160] "m"  External

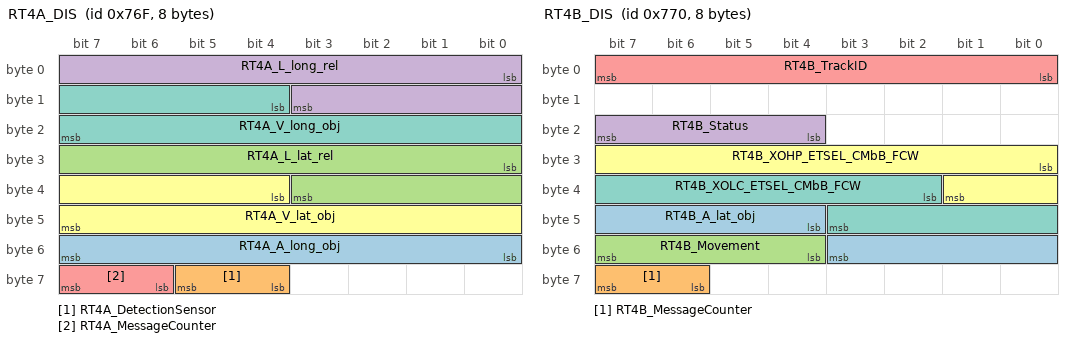
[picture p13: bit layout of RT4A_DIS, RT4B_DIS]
BO_ 1903 RT4A_DIS: 8 IFV_CWMP
 SG_ RT4A_A_long_obj : 48|8@1+ (0.1,-12.5) [-12.5|12.5] "m/s^2"  External
 SG_ RT4A_DetectionSensor : 60|2@1+ (1,0) [0|3] ""  External
 SG_ RT4A_L_lat_rel : 24|12@1+ (0.1,-50) [-50|50] "m"  External
 SG_ RT4A_L_long_rel : 0|12@1+ (0.1,0) [0|180] "m"  External
 SG_ RT4A_MessageCounter : 62|2@1+ (1,0) [0|3] ""  External
 SG_ RT4A_V_lat_obj : 36|12@1+ (0.025,-20) [-20|20] "m/s"  External
 SG_ RT4A_V_long_obj : 12|12@1+ (0.05,-100) [-100|100] "m/s"  External

BO_ 1904 RT4B_DIS: 8 IFV_CWMP
 SG_ RT4B_A_lat_obj : 44|8@1+ (0.1,-10) [-10|10] "m/s^2"  External
 SG_ RT4B_MessageCounter : 62|2@1+ (1,0) [0|3] ""  External
 SG_ RT4B_Movement : 52|4@1+ (1,0) [0|15] ""  External
 SG_ RT4B_Status : 20|4@1+ (1,0) [0|7] ""  External
 SG_ RT4B_TrackID : 0|8@1+ (1,0) [0|64] ""  External
 SG_ RT4B_XOHP_ETSEL_CMbB_FCW : 24|10@1+ (0.1,-50) [-50|50] "m"  External
 SG_ RT4B_XOLC_ETSEL_CMbB_FCW : 34|10@1+ (0.1,-50) [-50|50] "m"  External

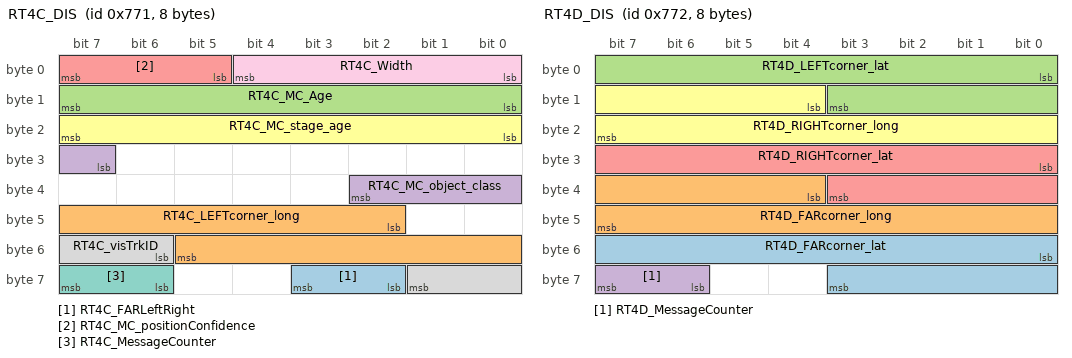
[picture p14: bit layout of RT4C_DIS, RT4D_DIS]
BO_ 1905 RT4C_DIS: 8 IFV_CWMP
 SG_ RT4C_FARLeftRight : 58|2@1+ (1,0) [0|2] ""  External
 SG_ RT4C_LEFTcorner_long : 42|12@1+ (0.1,-50) [-50|160] "m"  External
 SG_ RT4C_MC_Age : 8|8@1+ (1,0) [0|255] ""  External
 SG_ RT4C_MC_object_class : 31|4@1+ (1,0) [0|10] ""  External
 SG_ RT4C_MC_positionConfidence : 5|3@1+ (1,0) [0|2] ""  External
 SG_ RT4C_MC_stage_age : 16|8@1+ (1,0) [0|255] ""  External
 SG_ RT4C_MessageCounter : 62|2@1+ (1,0) [0|3] ""  External
 SG_ RT4C_visTrkID : 54|4@1+ (1,0) [0|15] ""  External
 SG_ RT4C_Width : 0|5@1+ (0.1,0) [0|3] "m"  External

BO_ 1906 RT4D_DIS: 8 IFV_CWMP
 SG_ RT4D_FARcorner_lat : 48|12@1+ (0.1,-50) [-50|50] "m"  External
 SG_ RT4D_FARcorner_long : 36|12@1+ (0.1,-50) [-50|160] "m"  External
 SG_ RT4D_LEFTcorner_lat : 0|12@1+ (0.1,-50) [-50|50] "m"  External
 SG_ RT4D_MessageCounter : 62|2@1+ (1,0) [0|3] ""  External
 SG_ RT4D_RIGHTcorner_lat : 24|12@1+ (0.1,-50) [-50|50] "m"  External
 SG_ RT4D_RIGHTcorner_long : 12|12@1+ (0.1,-50) [-50|160] "m"  External

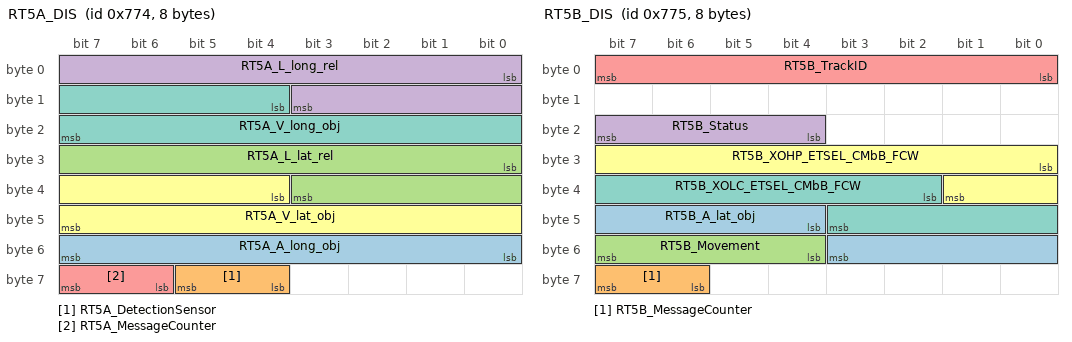
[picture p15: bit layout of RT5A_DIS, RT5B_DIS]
BO_ 1908 RT5A_DIS: 8 IFV_CWMP
 SG_ RT5A_A_long_obj : 48|8@1+ (0.1,-12.5) [-12.5|12.5] "m/s^2"  External
 SG_ RT5A_DetectionSensor : 60|2@1+ (1,0) [0|3] ""  External
 SG_ RT5A_L_lat_rel : 24|12@1+ (0.1,-50) [-50|50] "m"  External
 SG_ RT5A_L_long_rel : 0|12@1+ (0.1,0) [0|180] "m"  External
 SG_ RT5A_MessageCounter : 62|2@1+ (1,0) [0|3] ""  External
 SG_ RT5A_V_lat_obj : 36|12@1+ (0.025,-20) [-20|20] "m/s"  External
 SG_ RT5A_V_long_obj : 12|12@1+ (0.05,-100) [-100|100] "m/s"  External

BO_ 1909 RT5B_DIS: 8 IFV_CWMP
 SG_ RT5B_A_lat_obj : 44|8@1+ (0.1,-10) [-10|10] "m/s^2"  External
 SG_ RT5B_MessageCounter : 62|2@1+ (1,0) [0|3] ""  External
 SG_ RT5B_Movement : 52|4@1+ (1,0) [0|15] ""  External
 SG_ RT5B_Status : 20|4@1+ (1,0) [0|7] ""  External
 SG_ RT5B_TrackID : 0|8@1+ (1,0) [0|64] ""  External
 SG_ RT5B_XOHP_ETSEL_CMbB_FCW : 24|10@1+ (0.1,-50) [-50|50] "m"  External
 SG_ RT5B_XOLC_ETSEL_CMbB_FCW : 34|10@1+ (0.1,-50) [-50|50] "m"  External

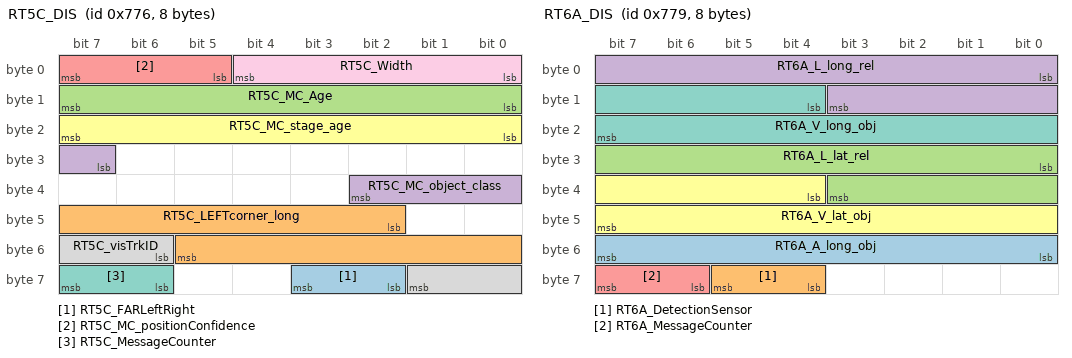
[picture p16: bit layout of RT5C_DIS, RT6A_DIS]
BO_ 1910 RT5C_DIS: 8 IFV_CWMP
 SG_ RT5C_FARLeftRight : 58|2@1+ (1,0) [0|2] ""  External
 SG_ RT5C_LEFTcorner_long : 42|12@1+ (0.1,-50) [-50|160] "m"  External
 SG_ RT5C_MC_Age : 8|8@1+ (1,0) [0|255] ""  External
 SG_ RT5C_MC_object_class : 31|4@1+ (1,0) [0|10] ""  External
 SG_ RT5C_MC_positionConfidence : 5|3@1+ (1,0) [0|2] ""  External
 SG_ RT5C_MC_stage_age : 16|8@1+ (1,0) [0|255] ""  External
 SG_ RT5C_MessageCounter : 62|2@1+ (1,0) [0|3] ""  External
 SG_ RT5C_visTrkID : 54|4@1+ (1,0) [0|15] ""  External
 SG_ RT5C_Width : 0|5@1+ (0.1,0) [0|3] "m"  External

BO_ 1911 RT5D_DIS: 8 IFV_CWMP
 SG_ RT5D_FARcorner_lat : 48|12@1+ (0.1,-50) [-50|50] "m"  External
 SG_ RT5D_FARcorner_long : 36|12@1+ (0.1,-50) [-50|160] "m"  External
 SG_ RT5D_LEFTcorner_lat : 0|12@1+ (0.1,-50) [-50|50] "m"  External
 SG_ RT5D_MessageCounter : 62|2@1+ (1,0) [0|3] ""  External
 SG_ RT5D_RIGHTcorner_lat : 24|12@1+ (0.1,-50) [-50|50] "m"  External
 SG_ RT5D_RIGHTcorner_long : 12|12@1+ (0.1,-50) [-50|160] "m"  External

BO_ 1913 RT6A_DIS: 8 IFV_CWMP
 SG_ RT6A_A_long_obj : 48|8@1+ (0.1,-12.5) [-12.5|12.5] "m/s^2"  External
 SG_ RT6A_DetectionSensor : 60|2@1+ (1,0) [0|3] ""  External
 SG_ RT6A_L_lat_rel : 24|12@1+ (0.1,-50) [-50|50] "m"  External
 SG_ RT6A_L_long_rel : 0|12@1+ (0.1,0) [0|180] "m"  External
 SG_ RT6A_MessageCounter : 62|2@1+ (1,0) [0|3] ""  External
 SG_ RT6A_V_lat_obj : 36|12@1+ (0.025,-20) [-20|20] "m/s"  External
 SG_ RT6A_V_long_obj : 12|12@1+ (0.05,-100) [-100|100] "m/s"  External

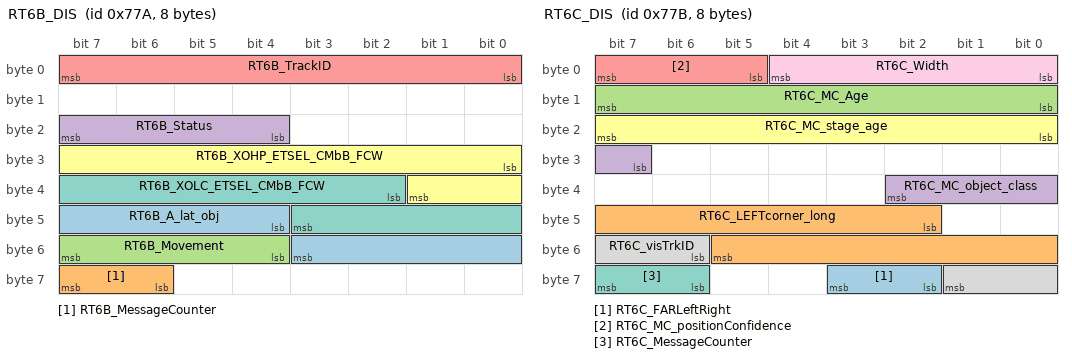
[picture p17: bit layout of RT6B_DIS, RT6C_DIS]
BO_ 1914 RT6B_DIS: 8 IFV_CWMP
 SG_ RT6B_A_lat_obj : 44|8@1+ (0.1,-10) [-10|10] "m/s^2"  External
 SG_ RT6B_MessageCounter : 62|2@1+ (1,0) [0|3] ""  External
 SG_ RT6B_Movement : 52|4@1+ (1,0) [0|15] ""  External
 SG_ RT6B_Status : 20|4@1+ (1,0) [0|7] ""  External
 SG_ RT6B_TrackID : 0|8@1+ (1,0) [0|64] ""  External
 SG_ RT6B_XOHP_ETSEL_CMbB_FCW : 24|10@1+ (0.1,-50) [-50|50] "m"  External
 SG_ RT6B_XOLC_ETSEL_CMbB_FCW : 34|10@1+ (0.1,-50) [-50|50] "m"  External

BO_ 1915 RT6C_DIS: 8 IFV_CWMP
 SG_ RT6C_FARLeftRight : 58|2@1+ (1,0) [0|2] ""  External
 SG_ RT6C_LEFTcorner_long : 42|12@1+ (0.1,-50) [-50|160] "m"  External
 SG_ RT6C_MC_Age : 8|8@1+ (1,0) [0|255] ""  External
 SG_ RT6C_MC_object_class : 31|4@1+ (1,0) [0|10] ""  External
 SG_ RT6C_MC_positionConfidence : 5|3@1+ (1,0) [0|2] ""  External
 SG_ RT6C_MC_stage_age : 16|8@1+ (1,0) [0|255] ""  External
 SG_ RT6C_MessageCounter : 62|2@1+ (1,0) [0|3] ""  External
 SG_ RT6C_visTrkID : 54|4@1+ (1,0) [0|15] ""  External
 SG_ RT6C_Width : 0|5@1+ (0.1,0) [0|3] "m"  External

BO_ 1916 RT6D_DIS: 8 IFV_CWMP
 SG_ RT6D_FARcorner_lat : 48|12@1+ (0.1,-50) [-50|50] "m"  External
 SG_ RT6D_FARcorner_long : 36|12@1+ (0.1,-50) [-50|160] "m"  External
 SG_ RT6D_LEFTcorner_lat : 0|12@1+ (0.1,-50) [-50|50] "m"  External
 SG_ RT6D_MessageCounter : 62|2@1+ (1,0) [0|3] ""  External
 SG_ RT6D_RIGHTcorner_lat : 24|12@1+ (0.1,-50) [-50|50] "m"  External
 SG_ RT6D_RIGHTcorner_long : 12|12@1+ (0.1,-50) [-50|160] "m"  External

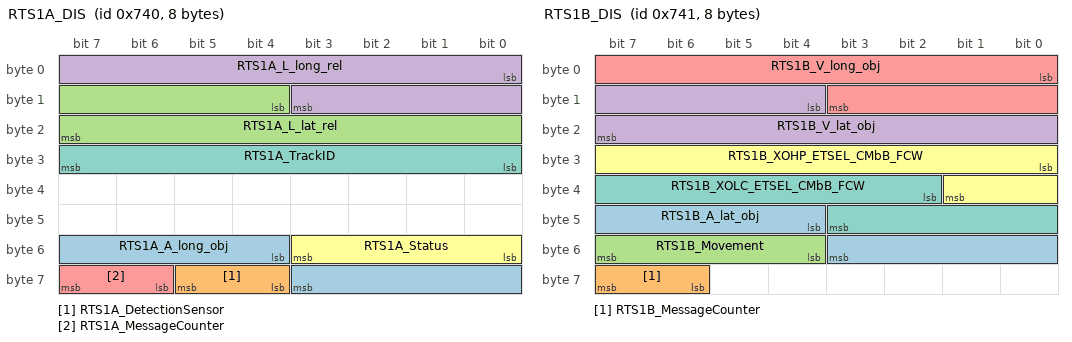
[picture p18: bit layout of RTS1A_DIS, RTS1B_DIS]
BO_ 1856 RTS1A_DIS: 8 IFV_CWMP
 SG_ RTS1A_A_long_obj : 52|8@1+ (0.1,-12.5) [-12.5|12.5] "m/s^2"  External
 SG_ RTS1A_DetectionSensor : 60|2@1+ (1,0) [0|3] ""  External
 SG_ RTS1A_L_lat_rel : 12|12@1+ (0.1,-50) [-50|50] "m"  External
 SG_ RTS1A_L_long_rel : 0|12@1+ (0.1,0) [0|180] "m"  External
 SG_ RTS1A_MessageCounter : 62|2@1+ (1,0) [0|3] ""  External
 SG_ RTS1A_Status : 48|4@1+ (1,0) [0|7] ""  External
 SG_ RTS1A_TrackID : 24|8@1+ (1,0) [0|64] ""  External

BO_ 1857 RTS1B_DIS: 8 IFV_CWMP
 SG_ RTS1B_A_lat_obj : 44|8@1+ (0.1,-10) [-10|10] "m/s^2"  External
 SG_ RTS1B_MessageCounter : 62|2@1+ (1,0) [0|3] ""  External
 SG_ RTS1B_Movement : 52|4@1+ (1,0) [0|15] ""  External
 SG_ RTS1B_V_lat_obj : 12|12@1+ (0.025,-20) [-20|20] "m/s"  External
 SG_ RTS1B_V_long_obj : 0|12@1+ (0.05,-100) [-100|100] "m/s"  External
 SG_ RTS1B_XOHP_ETSEL_CMbB_FCW : 24|10@1+ (0.1,-50) [-50|50] "m"  External
 SG_ RTS1B_XOLC_ETSEL_CMbB_FCW : 34|10@1+ (0.1,-50) [-50|50] "m"  External

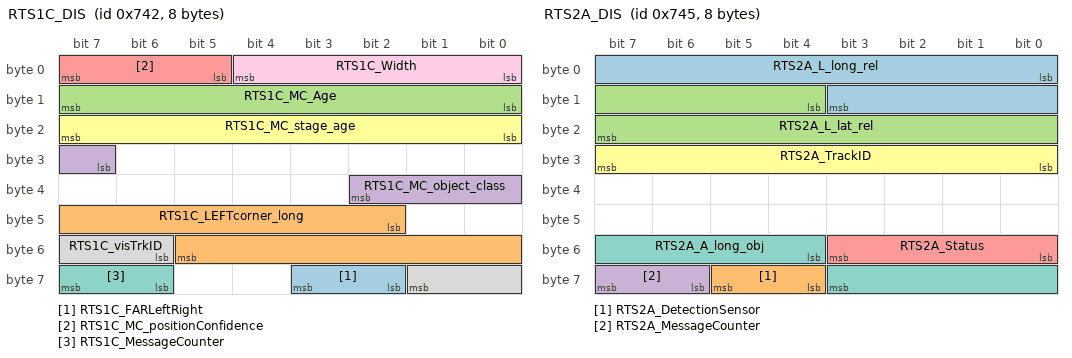
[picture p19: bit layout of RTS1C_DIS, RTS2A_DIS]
BO_ 1858 RTS1C_DIS: 8 IFV_CWMP
 SG_ RTS1C_FARLeftRight : 58|2@1+ (1,0) [0|2] ""  External
 SG_ RTS1C_LEFTcorner_long : 42|12@1+ (0.1,-50) [-50|160] "m"  External
 SG_ RTS1C_MC_Age : 8|8@1+ (1,0) [0|255] ""  External
 SG_ RTS1C_MC_object_class : 31|4@1+ (1,0) [0|10] ""  External
 SG_ RTS1C_MC_positionConfidence : 5|3@1+ (1,0) [0|2] ""  External
 SG_ RTS1C_MC_stage_age : 16|8@1+ (1,0) [0|255] ""  External
 SG_ RTS1C_MessageCounter : 62|2@1+ (1,0) [0|3] ""  External
 SG_ RTS1C_visTrkID : 54|4@1+ (1,0) [0|15] ""  External
 SG_ RTS1C_Width : 0|5@1+ (0.1,0) [0|3] "m"  External

BO_ 1859 RTS1D_DIS: 8 IFV_CWMP
 SG_ RTS1D_FARcorner_lat : 48|12@1+ (0.1,-50) [-50|50] "m"  External
 SG_ RTS1D_FARcorner_long : 36|12@1+ (0.1,-50) [-50|160] "m"  External
 SG_ RTS1D_LEFTcorner_lat : 0|12@1+ (0.1,-50) [-50|50] "m"  External
 SG_ RTS1D_MessageCounter : 62|2@1+ (1,0) [0|3] ""  External
 SG_ RTS1D_RIGHTcorner_lat : 24|12@1+ (0.1,-50) [-50|50] "m"  External
 SG_ RTS1D_RIGHTcorner_long : 12|12@1+ (0.1,-50) [-50|160] "m"  External

BO_ 1861 RTS2A_DIS: 8 IFV_CWMP
 SG_ RTS2A_L_long_rel : 0|12@1+ (0.1,0) [0|180] "m"  External
 SG_ RTS2A_DetectionSensor : 60|2@1+ (1,0) [0|3] ""  External
 SG_ RTS2A_L_lat_rel : 12|12@1+ (0.1,-50) [-50|50] "m"  External
 SG_ RTS2A_MessageCounter : 62|2@1+ (1,0) [0|3] ""  External
 SG_ RTS2A_Status : 48|4@1+ (1,0) [0|7] ""  External
 SG_ RTS2A_TrackID : 24|8@1+ (1,0) [0|64] ""  External
 SG_ RTS2A_A_long_obj : 52|8@1+ (0.1,-12.5) [-12.5|12.5] "m/s^2"  External

CM_ BO_ 3221225472 "This is a message for not used signals, created by Vector CANdb++ DBC OLE DB Provider.";
BA_DEF_  "GenDescription" STRING ;
BA_DEF_  "GenCompany" STRING ;
BA_DEF_  "GenAuthor" STRING ;
BA_DEF_  "GenRevisionDate" STRING ;
BA_DEF_  "GenRevision" STRING ;
BA_DEF_  "GenNetworkName" STRING ;
BA_DEF_  "GenNetworkBaudrate" STRING ;
BA_DEF_ SG_  "GenSigVtName" STRING ;
BA_DEF_ SG_  "GenSigVtIndex" STRING ;
BA_DEF_ SG_  "GenSigVtEn" STRING ;
BA_DEF_ SG_  "GenSigCmt" STRING ;
BA_DEF_ SG_  "GenSigStartValue" INT 0 1000000000;
BA_DEF_ SG_  "UsedOnPgmDBC" ENUM  "No","Yes";
BA_DEF_ SG_  "GenSigMissingSourceValue" INT 0 1000000000;
BA_DEF_ SG_  "GenSigInactiveValue" INT 0 100000;
BA_DEF_ SG_  "GenSigSendType" ENUM  "Cyclic","OnWrite","vector_leerstring","OnChange","vector_leerstring","IfActive","vector_leerstring","NoSigSendType";
BA_DEF_ BO_  "FrameGatewayMS1" HEX 0 1407;
BA_DEF_ BO_  "NetworkInitialization" ENUM  "No","Yes";
BA_DEF_ BO_  "EventRateOfChange" INT 10 10000;
BA_DEF_ BO_  "GenMsgStartDelayTime" INT 0 10000;
BA_DEF_ BO_  "GenMsgNrOfRepetition" INT 0 100;
BA_DEF_ BO_  "GenMsgDelayTime" INT 0 1000;
BA_DEF_ BO_  "GenMsgCycleTimeFast" INT 0 100000;
BA_DEF_ BO_  "GenMsgCycleTime" INT 0 100000;
BA_DEF_ BO_  "GenMsgSendType" ENUM  "FixedPeriodic","Event","EnabledPeriodic","NotUsed","NotUsed","EventPeriodic","NotUsed","NotUsed","NoMsgSendType";
BA_DEF_ BO_  "GenMsgILSupport" ENUM  "No","Yes";
BA_DEF_ BU_  "NodeWakeUpTime" INT 0 10000;
BA_DEF_ BU_  "NodeStartUpTime" INT 0 10000;
BA_DEF_ BU_  "NmAsrNodeIdentifier" HEX 128 255;
BA_DEF_ BU_  "PowerType" ENUM  "Switched","Latched","Sleep","vector_leerstring","vector_leerstring";
BA_DEF_ BU_  "DiagNode" ENUM  "GGDS","GDS","NONE";
BA_DEF_ BU_  "EOL_SB_Flash" ENUM  "GGDS","GDS","NONE","vector_leerstring";
BA_DEF_ BU_  "NmStationAddress" INT 0 255;
BA_DEF_ BU_  "ILUsed" ENUM  "No","Yes";
BA_DEF_ BU_  "NosPackage" ENUM  "None","I3_1","I3_2","1.0.1","RP","EuCD","Volcano";
BA_DEF_ BU_  "PackageID" STRING ;
BA_DEF_  "VersionNumber_B" STRING ;
BA_DEF_  "StarNetworkGwType" ENUM  "0=NotDefined","1=HS1","2=HS2","3=HS3","4=HS4","5=HS5","6=MS1";
BA_DEF_  "CMDB_Version" STRING ;
BA_DEF_  "NmType" STRING ;
BA_DEF_  "NetworkSpeed" ENUM  "500kBits/s","125kBit/s";
BA_DEF_  "NmAsrMessageCount" INT 128 128;
BA_DEF_  "NmAsrBaseAddress" HEX 1408 1408;
BA_DEF_  "DBName" STRING ;
BA_DEF_  "VersionDay" INT 1 31;
BA_DEF_  "Manufacturer" STRING ;
BA_DEF_  "VersionMonth" INT 1 12;
BA_DEF_  "VersionYear" INT 2000 3000;
BA_DEF_  "NmBaseAddress" HEX 1280 1280;
BA_DEF_  "NmMessageCount" INT 0 128;
BA_DEF_  "BusType" STRING ;
BA_DEF_ SG_  "SystemSignalLongSymbol" STRING ;
BA_DEF_DEF_  "GenDescription" "";
BA_DEF_DEF_  "GenCompany" "";
BA_DEF_DEF_  "GenAuthor" "";
BA_DEF_DEF_  "GenRevisionDate" "";
BA_DEF_DEF_  "GenRevision" "";
BA_DEF_DEF_  "GenNetworkName" "";
BA_DEF_DEF_  "GenNetworkBaudrate" "";
BA_DEF_DEF_  "GenSigVtName" "";
BA_DEF_DEF_  "GenSigVtIndex" "";
BA_DEF_DEF_  "GenSigVtEn" "";
BA_DEF_DEF_  "GenSigCmt" "";
BA_DEF_DEF_  "GenSigStartValue" 0;
BA_DEF_DEF_  "UsedOnPgmDBC" "Yes";
BA_DEF_DEF_  "GenSigMissingSourceValue" 0;
BA_DEF_DEF_  "GenSigInactiveValue" 0;
BA_DEF_DEF_  "GenSigSendType" "NoSigSendType";
BA_DEF_DEF_  "FrameGatewayMS1" 0;
BA_DEF_DEF_  "NetworkInitialization" "Yes";
BA_DEF_DEF_  "EventRateOfChange" 10000;
BA_DEF_DEF_  "GenMsgStartDelayTime" 0;
BA_DEF_DEF_  "GenMsgNrOfRepetition" 0;
BA_DEF_DEF_  "GenMsgDelayTime" 0;
BA_DEF_DEF_  "GenMsgCycleTimeFast" 0;
BA_DEF_DEF_  "GenMsgCycleTime" 0;
BA_DEF_DEF_  "GenMsgSendType" "NoMsgSendType";
BA_DEF_DEF_  "GenMsgILSupport" "Yes";
BA_DEF_DEF_  "NodeWakeUpTime" 10;
BA_DEF_DEF_  "NodeStartUpTime" 250;
BA_DEF_DEF_  "NmAsrNodeIdentifier" 128;
BA_DEF_DEF_  "PowerType" "Switched";
BA_DEF_DEF_  "DiagNode" "GGDS";
BA_DEF_DEF_  "EOL_SB_Flash" "GGDS";
BA_DEF_DEF_  "NmStationAddress" 0;
BA_DEF_DEF_  "ILUsed" "Yes";
BA_DEF_DEF_  "NosPackage" "I3_1";
BA_DEF_DEF_  "PackageID" "08.05.00.00.71.xx.xx.rr.00.00";
BA_DEF_DEF_  "VersionNumber_B" "B_1";
BA_DEF_DEF_  "StarNetworkGwType" "0=NotDefined";
BA_DEF_DEF_  "CMDB_Version" "v11.01";
BA_DEF_DEF_  "NmType" "Ford-OSEK";
BA_DEF_DEF_  "NetworkSpeed" "500kBits/s";
BA_DEF_DEF_  "NmAsrMessageCount" 128;
BA_DEF_DEF_  "NmAsrBaseAddress" 1408;
BA_DEF_DEF_  "DBName" "";
BA_DEF_DEF_  "VersionDay" 1;
BA_DEF_DEF_  "Manufacturer" "Ford";
BA_DEF_DEF_  "VersionMonth" 1;
BA_DEF_DEF_  "VersionYear" 2011;
BA_DEF_DEF_  "NmBaseAddress" 1280;
BA_DEF_DEF_  "NmMessageCount" 128;
BA_DEF_DEF_  "BusType" "CAN";
BA_DEF_DEF_  "SystemSignalLongSymbol" "";
BA_ "GenDescription" "Instrumented CAN";
BA_ "GenRevision" "v04.05d";
BA_ "GenRevisionDate" "May 04, 2016";
BA_ "GenAuthor" "W.Sean";
BA_ "GenCompany" "Delphi";
BA_ "GenNetworkName" "IFV INSTCAN";
BA_ "GenNetworkBaudrate" "500000";
BA_ "VersionNumber_B" "";
BA_ "CMDB_Version" "v04.00";
BA_ "VersionYear" 2015;
BA_ "Manufacturer" "SGM";
BA_ "NmType" "SGM-GMLAN";
BA_ "DBName" "INSTCAN";
BA_ "NmStationAddress" BU_ IFV_VFP 2;
BA_ "NmStationAddress" BU_ External 1;
BA_ "GenMsgCycleTime" BO_ 263 25;
BA_ "GenMsgSendType" BO_ 263 0;
BA_ "GenMsgCycleTime" BO_ 262 25;
BA_ "GenMsgSendType" BO_ 262 0;
BA_ "GenMsgSendType" BO_ 261 1;
BA_ "GenMsgSendType" BO_ 1796 1;
BA_ "GenMsgSendType" BO_ 526 1;
BA_ "GenMsgSendType" BO_ 525 1;
BA_ "GenMsgSendType" BO_ 570 1;
BA_ "GenMsgSendType" BO_ 568 1;
BA_ "GenMsgSendType" BO_ 567 1;
BA_ "GenMsgSendType" BO_ 566 1;
BA_ "GenMsgSendType" BO_ 565 1;
BA_ "GenMsgSendType" BO_ 564 1;
BA_ "GenMsgSendType" BO_ 563 1;
BA_ "GenMsgSendType" BO_ 755 1;
BA_ "GenMsgSendType" BO_ 256 0;
BA_ "GenMsgCycleTime" BO_ 256 1000;
BA_ "GenMsgCycleTime" BO_ 16 5;
BA_ "GenMsgSendType" BO_ 16 0;
BA_ "NetworkInitialization" BO_ 1031 0;
BA_ "GenMsgSendType" BO_ 1031 1;
BA_ "NetworkInitialization" BO_ 1030 0;
BA_ "GenMsgSendType" BO_ 1030 1;
BA_ "GenMsgCycleTime" BO_ 264 25;
BA_ "GenMsgSendType" BO_ 264 0;
BA_ "NetworkInitialization" BO_ 1940 0;
BA_ "GenMsgSendType" BO_ 1940 1;
BA_ "NetworkInitialization" BO_ 1698 0;
BA_ "GenMsgSendType" BO_ 1698 1;
BA_ "NetworkInitialization" BO_ 1697 0;
BA_ "GenMsgSendType" BO_ 1697 1;
BA_ "NetworkInitialization" BO_ 1696 0;
BA_ "GenMsgSendType" BO_ 1696 1;
BA_ "NetworkInitialization" BO_ 1695 0;
BA_ "GenMsgSendType" BO_ 1695 1;
BA_ "NetworkInitialization" BO_ 1694 0;
BA_ "GenMsgSendType" BO_ 1694 1;
BA_ "NetworkInitialization" BO_ 1693 0;
BA_ "GenMsgSendType" BO_ 1693 1;
BA_ "NetworkInitialization" BO_ 1692 0;
BA_ "GenMsgSendType" BO_ 1692 1;
BA_ "NetworkInitialization" BO_ 1691 0;
BA_ "GenMsgSendType" BO_ 1691 1;
BA_ "NetworkInitialization" BO_ 1690 0;
BA_ "GenMsgSendType" BO_ 1690 1;
BA_ "NetworkInitialization" BO_ 1895 0;
BA_ "GenMsgSendType" BO_ 1895 1;
BA_ "NetworkInitialization" BO_ 1893 0;
BA_ "GenMsgSendType" BO_ 1893 1;
BA_ "NetworkInitialization" BO_ 1891 0;
BA_ "GenMsgSendType" BO_ 1891 1;
BA_ "NetworkInitialization" BO_ 1890 0;
BA_ "GenMsgSendType" BO_ 1890 1;
BA_ "NetworkInitialization" BO_ 1027 0;
BA_ "GenMsgSendType" BO_ 1027 1;
BA_ "NetworkInitialization" BO_ 1025 0;
BA_ "GenMsgSendType" BO_ 1025 1;
BA_ "NetworkInitialization" BO_ 258 0;
BA_ "GenMsgSendType" BO_ 258 1;
BA_ "NetworkInitialization" BO_ 1888 0;
BA_ "GenMsgSendType" BO_ 1888 1;
BA_ "NetworkInitialization" BO_ 1889 0;
BA_ "GenMsgSendType" BO_ 1889 1;
BA_ "NetworkInitialization" BO_ 1894 0;
BA_ "GenMsgSendType" BO_ 1894 1;
BA_ "NetworkInitialization" BO_ 1896 0;
BA_ "GenMsgSendType" BO_ 1896 1;
BA_ "NetworkInitialization" BO_ 1898 0;
BA_ "GenMsgSendType" BO_ 1898 1;
BA_ "NetworkInitialization" BO_ 1899 0;
BA_ "GenMsgSendType" BO_ 1899 1;
BA_ "NetworkInitialization" BO_ 1900 0;
BA_ "GenMsgSendType" BO_ 1900 1;
BA_ "NetworkInitialization" BO_ 1901 0;
BA_ "GenMsgSendType" BO_ 1901 1;
BA_ "NetworkInitialization" BO_ 1903 0;
BA_ "GenMsgSendType" BO_ 1903 1;
BA_ "NetworkInitialization" BO_ 1904 0;
BA_ "GenMsgSendType" BO_ 1904 1;
BA_ "NetworkInitialization" BO_ 1905 0;
BA_ "GenMsgSendType" BO_ 1905 1;
BA_ "NetworkInitialization" BO_ 1906 0;
BA_ "GenMsgSendType" BO_ 1906 1;
BA_ "NetworkInitialization" BO_ 1908 0;
BA_ "GenMsgSendType" BO_ 1908 1;
BA_ "NetworkInitialization" BO_ 1909 0;
BA_ "GenMsgSendType" BO_ 1909 1;
BA_ "NetworkInitialization" BO_ 1910 0;
BA_ "GenMsgSendType" BO_ 1910 1;
BA_ "NetworkInitialization" BO_ 1911 0;
BA_ "GenMsgSendType" BO_ 1911 1;
BA_ "NetworkInitialization" BO_ 1913 0;
BA_ "GenMsgSendType" BO_ 1913 1;
BA_ "NetworkInitialization" BO_ 1914 0;
BA_ "GenMsgSendType" BO_ 1914 1;
BA_ "NetworkInitialization" BO_ 1915 0;
BA_ "GenMsgSendType" BO_ 1915 1;
BA_ "NetworkInitialization" BO_ 1916 0;
BA_ "GenMsgSendType" BO_ 1916 1;
BA_ "NetworkInitialization" BO_ 1856 0;
BA_ "GenMsgSendType" BO_ 1856 1;
BA_ "NetworkInitialization" BO_ 1857 0;
BA_ "GenMsgSendType" BO_ 1857 1;
BA_ "NetworkInitialization" BO_ 1858 0;
BA_ "GenMsgSendType" BO_ 1858 1;
BA_ "NetworkInitialization" BO_ 1859 0;
BA_ "GenMsgSendType" BO_ 1859 1;
BA_ "NetworkInitialization" BO_ 1861 0;
BA_ "GenMsgSendType" BO_ 1861 1;
BA_ "GenSigSendType" SG_ 3221225472 Version_Info_MessageCounter 1;
BA_ "GenSigSendType" SG_ 3221225472 CAN_Interface_Major_Version 1;
BA_ "GenSigSendType" SG_ 3221225472 CAN_Interface_Minor_Version 1;
BA_ "GenSigVtEn" SG_ 3221225472 VIS_LANE_AMBIGUOUS_LANE_RIGHT "TRUE";
BA_ "GenSigVtName" SG_ 3221225472 VIS_LANE_AMBIGUOUS_LANE_RIGHT "VtSig_VIS_LANE_AMBIGUOS_LANE_RIGHT";
BA_ "GenSigSendType" SG_ 3221225472 VIS_LANE_AMBIGUOUS_LANE_RIGHT 1;
BA_ "GenSigVtEn" SG_ 3221225472 VIS_LANE_AMBIGUOUS_LANE_LEFT "TRUE";
BA_ "GenSigVtName" SG_ 3221225472 VIS_LANE_AMBIGUOUS_LANE_LEFT "VtSig_VIS_LANE_AMBIGUOS_LANE_LEFT";
BA_ "GenSigSendType" SG_ 3221225472 VIS_LANE_AMBIGUOUS_LANE_LEFT 1;
BA_ "GenSigVtEn" SG_ 3221225472 VIS_LANE_LANE_CHANGE "TRUE";
BA_ "GenSigVtName" SG_ 3221225472 VIS_LANE_LANE_CHANGE "VtSig_VIS_LANE_CHANGE";
BA_ "GenSigSendType" SG_ 3221225472 VIS_LANE_LANE_CHANGE 1;
BA_ "GenSigSendType" SG_ 3221225472 VIS_LANE_RIGHT_INDIVID_TJACONF 1;
BA_ "GenSigVtEn" SG_ 3221225472 VIS_LANE_RIGHT_INDIVID_LKACONF "TRUE";
BA_ "GenSigVtName" SG_ 3221225472 VIS_LANE_RIGHT_INDIVID_LKACONF "VtSig_VIS_LANE_RIGHT_INDIVID_LKACONF";
BA_ "GenSigSendType" SG_ 3221225472 VIS_LANE_RIGHT_INDIVID_LKACONF 1;
BA_ "GenSigSendType" SG_ 3221225472 VIS_LANE_RIGHT_INDIVID_DIMONCONF 1;
BA_ "GenSigSendType" SG_ 3221225472 VIS_LANE_RIGHT_PARALL_TJACONF 1;
BA_ "GenSigVtEn" SG_ 3221225472 VIS_LANE_RIGHT_PARALL_LKACONF "TRUE";
BA_ "GenSigVtName" SG_ 3221225472 VIS_LANE_RIGHT_PARALL_LKACONF "VtSig_VIS_LANE_RIGHT_PARALL_LKACONF";
BA_ "GenSigSendType" SG_ 3221225472 VIS_LANE_RIGHT_PARALL_LKACONF 1;
BA_ "GenSigSendType" SG_ 3221225472 VIS_LANE_RIGHT_PARALL_DIMONCONF 1;
BA_ "GenSigSendType" SG_ 3221225472 VIS_LANE_LEFT_INDIVID_TJACONF 1;
BA_ "GenSigVtEn" SG_ 3221225472 VIS_LANE_LEFT_INDIVID_LKACONF "TRUE";
BA_ "GenSigVtName" SG_ 3221225472 VIS_LANE_LEFT_INDIVID_LKACONF "VtSig_VIS_LANE_LEFT_INDIVID_LKACONF";
BA_ "GenSigSendType" SG_ 3221225472 VIS_LANE_LEFT_INDIVID_LKACONF 1;
BA_ "GenSigSendType" SG_ 3221225472 VIS_LANE_LEFT_INDIVID_DIMONCONF 1;
BA_ "GenSigSendType" SG_ 3221225472 VIS_LANE_LEFT_PARALL_TJACONF 1;
BA_ "GenSigVtEn" SG_ 3221225472 VIS_LANE_LEFT_PARALL_LKACONF "TRUE";
BA_ "GenSigVtName" SG_ 3221225472 VIS_LANE_LEFT_PARALL_LKACONF "VtSig_VIS_LANE_LEFT_PARALL_LKACONF";
BA_ "GenSigSendType" SG_ 3221225472 VIS_LANE_LEFT_PARALL_LKACONF 1;
BA_ "GenSigSendType" SG_ 3221225472 VIS_LANE_LEFT_PARALL_DIMONCONF 1;
BA_ "GenSigVtEn" SG_ 3221225472 VIS_LANE_RIGHT_PARALL_TYPE "TRUE";
BA_ "GenSigVtName" SG_ 3221225472 VIS_LANE_RIGHT_PARALL_TYPE "VtSig_VIS_LANE_RIGHT_PARALL_TYPE";
BA_ "GenSigSendType" SG_ 3221225472 VIS_LANE_RIGHT_PARALL_TYPE 1;
BA_ "GenSigVtEn" SG_ 3221225472 VIS_LANE_RIGHT_INDIVID_TYPE "TRUE";
BA_ "GenSigVtName" SG_ 3221225472 VIS_LANE_RIGHT_INDIVID_TYPE "VtSig_VIS_LANE_RIGHT_INDIVID_TYPE";
BA_ "GenSigSendType" SG_ 3221225472 VIS_LANE_RIGHT_INDIVID_TYPE 1;
BA_ "GenSigVtEn" SG_ 3221225472 VIS_LANE_LEFT_PARALL_TYPE "TRUE";
BA_ "GenSigVtName" SG_ 3221225472 VIS_LANE_LEFT_PARALL_TYPE "VtSig_VIS_LANE_LEFT_PARALL_TYPE";
BA_ "GenSigSendType" SG_ 3221225472 VIS_LANE_LEFT_PARALL_TYPE 1;
BA_ "GenSigVtEn" SG_ 3221225472 VIS_LANE_LEFT_INDIVID_TYPE "TRUE";
BA_ "GenSigVtName" SG_ 3221225472 VIS_LANE_LEFT_INDIVID_TYPE "VtSig_VIS_LANE_LEFT_INDIVID_TYPE";
BA_ "GenSigSendType" SG_ 3221225472 VIS_LANE_LEFT_INDIVID_TYPE 1;
BA_ "GenSigSendType" SG_ 3221225472 VIS_AHBC_CLOSEST_OBJECT_DISTANCE 1;
BA_ "GenSigSendType" SG_ 3221225472 VIS_AHBC_BOUND_NOGLARE_RIGHT_ST 1;
BA_ "GenSigSendType" SG_ 3221225472 VIS_AHBC_BOUND_NOGLARE_RIGHT 1;
BA_ "GenSigSendType" SG_ 3221225472 VIS_AHBC_BOUND_NOGLARE_LEFT_ST 1;
BA_ "GenSigSendType" SG_ 3221225472 VIS_AHBC_BOUND_NOGLARE_LEFT 1;
BA_ "GenSigSendType" SG_ 3221225472 VIS_AHBC_BOUND_NOGLARE_BTM_ST 1;
BA_ "GenSigSendType" SG_ 3221225472 VIS_AHBC_BOUND_NOGLARE_BTM 1;
BA_ "GenSigVtEn" SG_ 3221225472 Latch_Fault_byte19_bit3 "TRUE";
BA_ "GenSigVtName" SG_ 3221225472 Latch_Fault_byte19_bit3 "VtSig_Latch_Fault_byte19_bit3";
BA_ "GenSigCmt" SG_ 3221225472 Latch_Fault_byte19_bit3 "ABS_8 Missing Msg (SteWhlCompAnEst_D_Qf)";
BA_ "GenSigVtEn" SG_ 3221225472 Latch_Fault_byte20_bit0 "TRUE";
BA_ "GenSigVtName" SG_ 3221225472 Latch_Fault_byte20_bit0 "VtSig_Latch_Fault_byte20_bit0";
BA_ "GenSigVtEn" SG_ 3221225472 Latch_Fault_byte19_bit7 "TRUE";
BA_ "GenSigVtName" SG_ 3221225472 Latch_Fault_byte19_bit7 "VtSig_Latch_Fault_byte19_bit7";
BA_ "GenSigVtEn" SG_ 3221225472 Latch_Fault_byte19_bit6 "TRUE";
BA_ "GenSigVtName" SG_ 3221225472 Latch_Fault_byte19_bit6 "VtSig_Latch_Fault_byte19_bit6";
BA_ "GenSigVtEn" SG_ 3221225472 Latch_Fault_byte19_bit5 "TRUE";
BA_ "GenSigVtName" SG_ 3221225472 Latch_Fault_byte19_bit5 "VtSig_Latch_Fault_byte19_bit5";
BA_ "GenSigVtEn" SG_ 3221225472 Latch_Fault_byte19_bit4 "TRUE";
BA_ "GenSigVtName" SG_ 3221225472 Latch_Fault_byte19_bit4 "VtSig_Latch_Fault_byte19_bit4";
BA_ "GenSigVtEn" SG_ 3221225472 Latch_Fault_byte19_bit2 "TRUE";
BA_ "GenSigVtName" SG_ 3221225472 Latch_Fault_byte19_bit2 "VtSig_Latch_Fault_byte19_bit2";
BA_ "GenSigCmt" SG_ 3221225472 Latch_Fault_byte19_bit2 "Latch_Fault_byte19_bit2";
BA_ "GenSigVtEn" SG_ 3221225472 Latch_Fault_byte19_bit1 "TRUE";
BA_ "GenSigVtName" SG_ 3221225472 Latch_Fault_byte19_bit1 "VtSig_Latch_Fault_byte19_bit1";
BA_ "GenSigCmt" SG_ 3221225472 Latch_Fault_byte19_bit1 "Latch_Fault_byte19_bit1";
BA_ "GenSigVtEn" SG_ 3221225472 Latch_Fault_byte19_bit0 "TRUE";
BA_ "GenSigVtName" SG_ 3221225472 Latch_Fault_byte19_bit0 "VtSig_Latch_Fault_byte19_bit0";
BA_ "GenSigCmt" SG_ 3221225472 Latch_Fault_byte19_bit0 "Latch_Fault_byte19_bit0";
BA_ "GenSigVtEn" SG_ 3221225472 Latch_Fault_byte18_bit0 "TRUE";
BA_ "GenSigVtName" SG_ 3221225472 Latch_Fault_byte18_bit0 "VtSig_Latch_Fault_byte18_bit0";
BA_ "GenSigCmt" SG_ 3221225472 Latch_Fault_byte18_bit0 "CCM_PCAN_Invalid_Data";
BA_ "GenSigVtEn" SG_ 3221225472 Latch_Fault_byte18_bit1 "TRUE";
BA_ "GenSigVtName" SG_ 3221225472 Latch_Fault_byte18_bit1 "VtSig_Latch_Fault_byte18_bit1";
BA_ "GenSigCmt" SG_ 3221225472 Latch_Fault_byte18_bit1 "Reserved";
BA_ "GenSigVtEn" SG_ 3221225472 Latch_Fault_byte18_bit2 "TRUE";
BA_ "GenSigVtName" SG_ 3221225472 Latch_Fault_byte18_bit2 "VtSig_Latch_Fault_byte18_bit2";
BA_ "GenSigCmt" SG_ 3221225472 Latch_Fault_byte18_bit2 "Reserved";
BA_ "GenSigVtEn" SG_ 3221225472 Latch_Fault_byte18_bit3 "TRUE";
BA_ "GenSigVtName" SG_ 3221225472 Latch_Fault_byte18_bit3 "VtSig_Latch_Fault_byte18_bit3";
BA_ "GenSigCmt" SG_ 3221225472 Latch_Fault_byte18_bit3 "Reserved";
BA_ "GenSigVtEn" SG_ 3221225472 LaActlDeny_B_ActlQfError "TRUE";
BA_ "GenSigVtName" SG_ 3221225472 LaActlDeny_B_ActlQfError "VtSig_LaActlDeny_B_ActlQfError";
BA_ "GenSigCmt" SG_ 3221225472 LaActlDeny_B_ActlQfError "LaActDeny_B_Actl QF Error (RCM)";
BA_ "GenSigVtEn" SG_ 3221225472 Latch_Fault_byte18_bit5 "TRUE";
BA_ "GenSigVtName" SG_ 3221225472 Latch_Fault_byte18_bit5 "VtSig_Latch_Fault_byte18_bit5";
BA_ "GenSigCmt" SG_ 3221225472 Latch_Fault_byte18_bit5 "Latch_Fault_byte18_bit5";
BA_ "GenSigVtEn" SG_ 3221225472 Latch_Fault_byte18_bit6 "TRUE";
BA_ "GenSigVtName" SG_ 3221225472 Latch_Fault_byte18_bit6 "VtSig_Latch_Fault_byte18_bit6";
BA_ "GenSigCmt" SG_ 3221225472 Latch_Fault_byte18_bit6 "Reserved";
BA_ "GenSigVtEn" SG_ 3221225472 Latch_Fault_byte18_bit7 "TRUE";
BA_ "GenSigVtName" SG_ 3221225472 Latch_Fault_byte18_bit7 "VtSig_Latch_Fault_byte18_bit7";
BA_ "GenSigCmt" SG_ 3221225472 Latch_Fault_byte18_bit7 "LaSwtchPos_D_Stat QF Error Direct";
BA_ "GenSigVtEn" SG_ 3221225472 Latch_Fault_byte17_bit0 "TRUE";
BA_ "GenSigVtName" SG_ 3221225472 Latch_Fault_byte17_bit0 "VtSig_Latch_Fault_byte17_bit0";
BA_ "GenSigCmt" SG_ 3221225472 Latch_Fault_byte17_bit0 "Latch_Fault_byte17_bit0";
BA_ "GenSigVtEn" SG_ 3221225472 Latch_Fault_byte17_bit1 "TRUE";
BA_ "GenSigVtName" SG_ 3221225472 Latch_Fault_byte17_bit1 "VtSig_CarCfgImplausibleError_Param_23";
BA_ "GenSigCmt" SG_ 3221225472 Latch_Fault_byte17_bit1 "CarCfgImplausibleError_Param_23";
BA_ "GenSigVtEn" SG_ 3221225472 Latch_Fault_byte17_bit2 "TRUE";
BA_ "GenSigVtName" SG_ 3221225472 Latch_Fault_byte17_bit2 "VtSig_CarCfgImplausibleError_Param_96";
BA_ "GenSigCmt" SG_ 3221225472 Latch_Fault_byte17_bit2 "CarCfgImplausibleError_Param_96";
BA_ "GenSigVtEn" SG_ 3221225472 Latch_Fault_byte17_bit3 "TRUE";
BA_ "GenSigVtName" SG_ 3221225472 Latch_Fault_byte17_bit3 "VtSig_Latch_Fault_byte17_bit3";
BA_ "GenSigCmt" SG_ 3221225472 Latch_Fault_byte17_bit3 "Latch_Fault_byte17_bit3";
BA_ "GenSigVtEn" SG_ 3221225472 Latch_Fault_byte17_bit4 "TRUE";
BA_ "GenSigVtName" SG_ 3221225472 Latch_Fault_byte17_bit4 "VtSig_Latch_Fault_byte17_bit4";
BA_ "GenSigCmt" SG_ 3221225472 Latch_Fault_byte17_bit4 "Latch_Fault_byte17_bit4";
BA_ "GenSigCmt" SG_ 3221225472 Latch_Fault_byte17_bit5 "Reserved";
BA_ "GenSigVtEn" SG_ 3221225472 Latch_Fault_byte17_bit6 "TRUE";
BA_ "GenSigVtName" SG_ 3221225472 Latch_Fault_byte17_bit6 "VtSig_CCM_PCAN_Missing_Msg";
BA_ "GenSigCmt" SG_ 3221225472 Latch_Fault_byte17_bit6 "CCM_PCAN_Missing_Msg";
BA_ "GenSigVtEn" SG_ 3221225472 Latch_Fault_byte17_bit7 "TRUE";
BA_ "GenSigVtName" SG_ 3221225472 Latch_Fault_byte17_bit7 "VtSig_CCM_PCAN_RangeCheck";
BA_ "GenSigCmt" SG_ 3221225472 Latch_Fault_byte17_bit7 "CCM_PCAN_RangeCheck";
BA_ "GenSigVtEn" SG_ 3221225472 Latch_Fault_byte16_bit0 "TRUE";
BA_ "GenSigVtName" SG_ 3221225472 Latch_Fault_byte16_bit0 "VtSig_Latch_Fault_byte16_bit0";
BA_ "GenSigCmt" SG_ 3221225472 Latch_Fault_byte16_bit0 "Latch_Fault_byte16_bit0 (ABS)";
BA_ "GenSigVtEn" SG_ 3221225472 Latch_Fault_byte16_bit1 "TRUE";
BA_ "GenSigVtName" SG_ 3221225472 Latch_Fault_byte16_bit1 "VtSig_SetDTCAccCancelFailure";
BA_ "GenSigCmt" SG_ 3221225472 Latch_Fault_byte16_bit1 "Latch_Fault_byte16_bit1 (ECM)";
BA_ "GenSigVtEn" SG_ 3221225472 Latch_Fault_byte16_bit2 "TRUE";
BA_ "GenSigVtName" SG_ 3221225472 Latch_Fault_byte16_bit2 "VtSig_SetDTC_ACCDeniedByBCM";
BA_ "GenSigCmt" SG_ 3221225472 Latch_Fault_byte16_bit2 "SetDTC_ACCDeniedByBCM (ABS)";
BA_ "GenSigVtEn" SG_ 3221225472 Latch_Fault_byte16_bit3 "TRUE";
BA_ "GenSigVtName" SG_ 3221225472 Latch_Fault_byte16_bit3 "VtSig_Latch_Fault_byte16_bit3";
BA_ "GenSigCmt" SG_ 3221225472 Latch_Fault_byte16_bit3 "Latch_Fault_byte16_bit3 (IPC)";
BA_ "GenSigVtEn" SG_ 3221225472 Latch_Fault_byte16_bit4 "TRUE";
BA_ "GenSigVtName" SG_ 3221225472 Latch_Fault_byte16_bit4 "VtSig_Latch_Fault_byte16_bit4";
BA_ "GenSigCmt" SG_ 3221225472 Latch_Fault_byte16_bit4 "Latch_Fault_byte16_bit4";
BA_ "GenSigCmt" SG_ 3221225472 Latch_Fault_byte16_bit5 "Reserved";
BA_ "GenSigCmt" SG_ 3221225472 Latch_Fault_byte16_bit6 "Reserved";
BA_ "GenSigCmt" SG_ 3221225472 Latch_Fault_byte16_bit7 "Reserved";
BA_ "GenSigVtEn" SG_ 3221225472 Latch_Fault_byte15_bit0 "TRUE";
BA_ "GenSigVtName" SG_ 3221225472 Latch_Fault_byte15_bit0 "VtSig_Latch_Fault_byte15_bit0";
BA_ "GenSigCmt" SG_ 3221225472 Latch_Fault_byte15_bit0 "Latch_Fault_byte15_bit0 (ABS)";
BA_ "GenSigVtEn" SG_ 3221225472 Latch_Fault_byte15_bit1 "TRUE";
BA_ "GenSigVtName" SG_ 3221225472 Latch_Fault_byte15_bit1 "VtSig_DTCCMbBDeniedByECM";
BA_ "GenSigCmt" SG_ 3221225472 Latch_Fault_byte15_bit1 "DTCCMbBDeniedByECM (ECM)";
BA_ "GenSigVtEn" SG_ 3221225472 Latch_Fault_byte15_bit2 "TRUE";
BA_ "GenSigVtName" SG_ 3221225472 Latch_Fault_byte15_bit2 "VtSig_DTCImplausCMbBByBCM";
BA_ "GenSigCmt" SG_ 3221225472 Latch_Fault_byte15_bit2 "DTCImplausCMbBByBCM (ABS)";
BA_ "GenSigVtEn" SG_ 3221225472 Latch_Fault_byte15_bit3 "TRUE";
BA_ "GenSigVtName" SG_ 3221225472 Latch_Fault_byte15_bit3 "VtSig_DTCImplausCMbBByECM";
BA_ "GenSigCmt" SG_ 3221225472 Latch_Fault_byte15_bit3 "DTCImplausCMbBByECM (ECM)";
BA_ "GenSigVtEn" SG_ 3221225472 Latch_Fault_byte15_bit4 "TRUE";
BA_ "GenSigVtName" SG_ 3221225472 Latch_Fault_byte15_bit4 "VtSig_DTCImplausCMbBByFSM";
BA_ "GenSigCmt" SG_ 3221225472 Latch_Fault_byte15_bit4 "DTCImplausCMbBByFSM (CCM)";
BA_ "GenSigCmt" SG_ 3221225472 Latch_Fault_byte15_bit5 "Reserved";
BA_ "GenSigVtEn" SG_ 3221225472 Latch_Fault_byte15_bit6 "TRUE";
BA_ "GenSigVtName" SG_ 3221225472 Latch_Fault_byte15_bit6 "VtSig_Latch_Fault_byte15_bit6";
BA_ "GenSigCmt" SG_ 3221225472 Latch_Fault_byte15_bit6 "Latch_Fault_byte15_bit6 (ABS)";
BA_ "GenSigVtEn" SG_ 3221225472 Latch_Fault_byte15_bit7 "TRUE";
BA_ "GenSigVtName" SG_ 3221225472 Latch_Fault_byte15_bit7 "VtSig_Latch_Fault_byte15_bit7";
BA_ "GenSigCmt" SG_ 3221225472 Latch_Fault_byte15_bit7 "Latch_Fault_byte15_bit7 (ECM)";
BA_ "GenSigVtEn" SG_ 3221225472 Latch_Fault_byte14_bit0 "TRUE";
BA_ "GenSigVtName" SG_ 3221225472 Latch_Fault_byte14_bit0 "VtSig_Latch_Fault_byte14_bit0";
BA_ "GenSigCmt" SG_ 3221225472 Latch_Fault_byte14_bit0 "VehLong2_A_Actl QF Error (RCM)";
BA_ "GenSigVtEn" SG_ 3221225472 Latch_Fault_byte14_bit1 "TRUE";
BA_ "GenSigVtName" SG_ 3221225472 Latch_Fault_byte14_bit1 "VtSig_AccDeny_B_RqIpc_UB_QF_Er";
BA_ "GenSigCmt" SG_ 3221225472 Latch_Fault_byte14_bit1 "AccDeny_B_RqIpc_UB QF Error  (IPC)";
BA_ "GenSigVtEn" SG_ 3221225472 Latch_Fault_byte14_bit3 "TRUE";
BA_ "GenSigVtName" SG_ 3221225472 Latch_Fault_byte14_bit3 "VtSig_Latch_Fault_byte14_bit3";
BA_ "GenSigCmt" SG_ 3221225472 Latch_Fault_byte14_bit3 "LaActDeny_B_Actl QF Error (SCCM)";
BA_ "GenSigVtEn" SG_ 3221225472 Latch_Fault_byte14_bit4 "TRUE";
BA_ "GenSigVtName" SG_ 3221225472 Latch_Fault_byte14_bit4 "VtSig_DrQltyDrv_D_StatGsm_QF_Er";
BA_ "GenSigCmt" SG_ 3221225472 Latch_Fault_byte14_bit4 "DrQltyDrv_D_StatGsm QF Error (GSM)";
BA_ "GenSigVtEn" SG_ 3221225472 Latch_Fault_byte14_bit5 "TRUE";
BA_ "GenSigVtName" SG_ 3221225472 Latch_Fault_byte14_bit5 "VtSig_LROS_LKASwitchStatus_QF_E";
BA_ "GenSigCmt" SG_ 3221225472 Latch_Fault_byte14_bit5 "LROS_LKASwitchStatus QF Error (LKASwitch)";
BA_ "GenSigVtEn" SG_ 3221225472 Latch_Fault_byte14_bit6 "TRUE";
BA_ "GenSigVtName" SG_ 3221225472 Latch_Fault_byte14_bit6 "VtSig_Latch_Fault_byte14_bit6";
BA_ "GenSigCmt" SG_ 3221225472 Latch_Fault_byte14_bit6 "MatchConf_Validity Error (IPMA)";
BA_ "GenSigCmt" SG_ 3221225472 Latch_Fault_byte14_bit7 "Reserved";
BA_ "GenSigVtEn" SG_ 3221225472 Active_Fault_byte20_bit0 "TRUE";
BA_ "GenSigVtName" SG_ 3221225472 Active_Fault_byte20_bit0 "VtSig_Active_Fault_byte20_bit0";
BA_ "GenSigVtEn" SG_ 3221225472 Active_Fault_byte19_bit7 "TRUE";
BA_ "GenSigVtName" SG_ 3221225472 Active_Fault_byte19_bit7 "VtSig_Active_Fault_byte19_bit7";
BA_ "GenSigVtEn" SG_ 3221225472 Active_Fault_byte19_bit6 "TRUE";
BA_ "GenSigVtName" SG_ 3221225472 Active_Fault_byte19_bit6 "VtSig_Active_Fault_byte19_bit6";
BA_ "GenSigVtEn" SG_ 3221225472 Active_Fault_byte19_bit5 "TRUE";
BA_ "GenSigVtName" SG_ 3221225472 Active_Fault_byte19_bit5 "VtSig_Active_Fault_byte19_bit5";
BA_ "GenSigVtEn" SG_ 3221225472 Active_Fault_byte19_bit4 "TRUE";
BA_ "GenSigVtName" SG_ 3221225472 Active_Fault_byte19_bit4 "VtSig_Active_Fault_byte19_bit4";
BA_ "GenSigVtEn" SG_ 3221225472 Active_Fault_byte19_bit3 "TRUE";
BA_ "GenSigVtName" SG_ 3221225472 Active_Fault_byte19_bit3 "VtSig_Active_Fault_byte19_bit3";
BA_ "GenSigCmt" SG_ 3221225472 Active_Fault_byte19_bit3 "ABS_8 Missing Msg (SteWhlCompAnEst_D_Qf)";
BA_ "GenSigVtEn" SG_ 3221225472 Active_Fault_byte19_bit2 "TRUE";
BA_ "GenSigVtName" SG_ 3221225472 Active_Fault_byte19_bit2 "VtSig_Active_Fault_byte19_bit2";
BA_ "GenSigCmt" SG_ 3221225472 Active_Fault_byte19_bit2 "Latch_Fault_byte19_bit2";
BA_ "GenSigVtEn" SG_ 3221225472 Active_Fault_byte19_bit1 "TRUE";
BA_ "GenSigVtName" SG_ 3221225472 Active_Fault_byte19_bit1 "VtSig_Active_Fault_byte19_bit1";
BA_ "GenSigCmt" SG_ 3221225472 Active_Fault_byte19_bit1 "Latch_Fault_byte19_bit1";
BA_ "GenSigVtEn" SG_ 3221225472 Active_Fault_byte19_bit0 "TRUE";
BA_ "GenSigVtName" SG_ 3221225472 Active_Fault_byte19_bit0 "VtSig_Active_Fault_byte19_bit0";
BA_ "GenSigCmt" SG_ 3221225472 Active_Fault_byte19_bit0 "Latch_Fault_byte19_bit0";
BA_ "GenSigVtEn" SG_ 3221225472 Active_Fault_byte18_bit0 "TRUE";
BA_ "GenSigVtName" SG_ 3221225472 Active_Fault_byte18_bit0 "VtSig_CCM_PCAN_Invalid_Data_A";
BA_ "GenSigCmt" SG_ 3221225472 Active_Fault_byte18_bit0 "Latch_Fault_byte18_bit0";
BA_ "GenSigVtEn" SG_ 3221225472 Active_Fault_byte18_bit1 "TRUE";
BA_ "GenSigVtName" SG_ 3221225472 Active_Fault_byte18_bit1 "VtSig_Active_Fault_byte18_bit1";
BA_ "GenSigCmt" SG_ 3221225472 Active_Fault_byte18_bit1 "Latch_Fault_byte18_bit1";
BA_ "GenSigVtEn" SG_ 3221225472 Active_Fault_byte18_bit2 "TRUE";
BA_ "GenSigVtName" SG_ 3221225472 Active_Fault_byte18_bit2 "VtSig_Active_Fault_byte18_bit2";
BA_ "GenSigCmt" SG_ 3221225472 Active_Fault_byte18_bit2 "Latch_Fault_byte18_bit2";
BA_ "GenSigVtEn" SG_ 3221225472 Active_Fault_byte18_bit3 "TRUE";
BA_ "GenSigVtName" SG_ 3221225472 Active_Fault_byte18_bit3 "VtSig_Active_Fault_byte18_bit3";
BA_ "GenSigCmt" SG_ 3221225472 Active_Fault_byte18_bit3 "Latch_Fault_byte18_bit3";
BA_ "GenSigVtEn" SG_ 3221225472 Active_Fault_byte18_bit4 "TRUE";
BA_ "GenSigVtName" SG_ 3221225472 Active_Fault_byte18_bit4 "VtSig_Active_Fault_byte18_bit4";
BA_ "GenSigCmt" SG_ 3221225472 Active_Fault_byte18_bit4 "LaActDeny_B_Actl QF Error (RCM)";
BA_ "GenSigVtEn" SG_ 3221225472 Active_Fault_byte18_bit5 "TRUE";
BA_ "GenSigVtName" SG_ 3221225472 Active_Fault_byte18_bit5 "VtSig_Active_Fault_byte18_bit5";
BA_ "GenSigCmt" SG_ 3221225472 Active_Fault_byte18_bit5 "Active_Fault_byte18_bit5";
BA_ "GenSigVtEn" SG_ 3221225472 Active_Fault_byte18_bit6 "TRUE";
BA_ "GenSigVtName" SG_ 3221225472 Active_Fault_byte18_bit6 "VtSig_Active_Fault_byte18_bit6";
BA_ "GenSigCmt" SG_ 3221225472 Active_Fault_byte18_bit6 "Reserved";
BA_ "GenSigVtEn" SG_ 3221225472 Active_Fault_byte18_bit7 "TRUE";
BA_ "GenSigVtName" SG_ 3221225472 Active_Fault_byte18_bit7 "VtSig_Active_Fault_byte18_bit7";
BA_ "GenSigCmt" SG_ 3221225472 Active_Fault_byte18_bit7 "LaSwtchPos_D_Stat QF Error Direct";
BA_ "GenSigVtEn" SG_ 3221225472 Active_Fault_byte17_bit0 "TRUE";
BA_ "GenSigVtName" SG_ 3221225472 Active_Fault_byte17_bit0 "VtSig_Active_Fault_byte17_bit0";
BA_ "GenSigCmt" SG_ 3221225472 Active_Fault_byte17_bit0 "Latch_Fault_byte17_bit0";
BA_ "GenSigVtEn" SG_ 3221225472 Active_Fault_byte17_bit1 "TRUE";
BA_ "GenSigVtName" SG_ 3221225472 Active_Fault_byte17_bit1 "VtSig_Active_Fault_byte17_bit1";
BA_ "GenSigCmt" SG_ 3221225472 Active_Fault_byte17_bit1 "CarCfgImplausibleError_Param_23";
BA_ "GenSigVtEn" SG_ 3221225472 Active_Fault_byte17_bit2 "TRUE";
BA_ "GenSigVtName" SG_ 3221225472 Active_Fault_byte17_bit2 "VtSig_Active_Fault_byte17_bit2";
BA_ "GenSigCmt" SG_ 3221225472 Active_Fault_byte17_bit2 "CarCfgImplausibleError_Param_96";
BA_ "GenSigVtEn" SG_ 3221225472 Active_Fault_byte17_bit3 "TRUE";
BA_ "GenSigVtName" SG_ 3221225472 Active_Fault_byte17_bit3 "VtSig_Active_Fault_byte17_bit3";
BA_ "GenSigCmt" SG_ 3221225472 Active_Fault_byte17_bit3 "Latch_Fault_byte17_bit3";
BA_ "GenSigVtEn" SG_ 3221225472 Active_Fault_byte17_bit4 "TRUE";
BA_ "GenSigVtName" SG_ 3221225472 Active_Fault_byte17_bit4 "VtSig_Active_Fault_byte17_bit4";
BA_ "GenSigCmt" SG_ 3221225472 Active_Fault_byte17_bit4 "Latch_Fault_byte17_bit4";
BA_ "GenSigCmt" SG_ 3221225472 Active_Fault_byte17_bit5 "Reserved";
BA_ "GenSigVtEn" SG_ 3221225472 Active_Fault_byte17_bit6 "TRUE";
BA_ "GenSigVtName" SG_ 3221225472 Active_Fault_byte17_bit6 "VtSig_CCM_PCAN_Missing_Msg_A";
BA_ "GenSigCmt" SG_ 3221225472 Active_Fault_byte17_bit6 "CCM_PCAN_Missing_Msg";
BA_ "GenSigVtEn" SG_ 3221225472 Active_Fault_byte17_bit7 "TRUE";
BA_ "GenSigVtName" SG_ 3221225472 Active_Fault_byte17_bit7 "VtSig_CCM_PCAN_RangeCheck_A";
BA_ "GenSigCmt" SG_ 3221225472 Active_Fault_byte17_bit7 "CCM_PCAN_RangeCheck";
BA_ "GenSigVtEn" SG_ 3221225472 Active_Fault_byte16_bit0 "TRUE";
BA_ "GenSigVtName" SG_ 3221225472 Active_Fault_byte16_bit0 "VtSig_SetDTCImplausibleBrakeAc_A";
BA_ "GenSigCmt" SG_ 3221225472 Active_Fault_byte16_bit0 "Latch_Fault_byte16_bit0 (ABS)";
BA_ "GenSigVtEn" SG_ 3221225472 Active_Fault_byte16_bit1 "TRUE";
BA_ "GenSigVtName" SG_ 3221225472 Active_Fault_byte16_bit1 "VtSig_Active_Fault_byte16_bit1";
BA_ "GenSigCmt" SG_ 3221225472 Active_Fault_byte16_bit1 "Latch_Fault_byte16_bit1 (ECM)";
BA_ "GenSigVtEn" SG_ 3221225472 Active_Fault_byte16_bit2 "TRUE";
BA_ "GenSigVtName" SG_ 3221225472 Active_Fault_byte16_bit2 "VtSig_Active_Fault_byte16_bit2";
BA_ "GenSigCmt" SG_ 3221225472 Active_Fault_byte16_bit2 "SetDTC_ACCDeniedByBCM (ABS)";
BA_ "GenSigVtEn" SG_ 3221225472 Active_Fault_byte16_bit3 "TRUE";
BA_ "GenSigVtName" SG_ 3221225472 Active_Fault_byte16_bit3 "VtSig_Active_Fault_byte16_bit3";
BA_ "GenSigCmt" SG_ 3221225472 Active_Fault_byte16_bit3 "Latch_Fault_byte16_bit3 (IPC)";
BA_ "GenSigVtEn" SG_ 3221225472 Active_Fault_byte16_bit4 "TRUE";
BA_ "GenSigVtName" SG_ 3221225472 Active_Fault_byte16_bit4 "VtSig_Active_Fault_byte16_bit4";
BA_ "GenSigCmt" SG_ 3221225472 Active_Fault_byte16_bit4 "Latch_Fault_byte16_bit4";
BA_ "GenSigCmt" SG_ 3221225472 Active_Fault_byte16_bit5 "Reserved";
BA_ "GenSigCmt" SG_ 3221225472 Active_Fault_byte16_bit6 "Reserved";
BA_ "GenSigCmt" SG_ 3221225472 Active_Fault_byte16_bit7 "Reserved";
BA_ "GenSigVtEn" SG_ 3221225472 Active_Fault_byte15_bit0 "TRUE";
BA_ "GenSigVtName" SG_ 3221225472 Active_Fault_byte15_bit0 "VtSig_Active_Fault_byte15_bit0";
BA_ "GenSigCmt" SG_ 3221225472 Active_Fault_byte15_bit0 "Latch_Fault_byte15_bit0 (ABS)";
BA_ "GenSigVtEn" SG_ 3221225472 Active_Fault_byte15_bit1 "TRUE";
BA_ "GenSigVtName" SG_ 3221225472 Active_Fault_byte15_bit1 "VtSig_Active_Fault_byte15_bit1";
BA_ "GenSigCmt" SG_ 3221225472 Active_Fault_byte15_bit1 "DTCCMbBDeniedByECM (ECM)";
BA_ "GenSigVtEn" SG_ 3221225472 Active_Fault_byte15_bit2 "TRUE";
BA_ "GenSigVtName" SG_ 3221225472 Active_Fault_byte15_bit2 "VtSig_DTCImplausCMbBByBCM_A";
BA_ "GenSigCmt" SG_ 3221225472 Active_Fault_byte15_bit2 "DTCImplausCMbBByBCM (ABS)";
BA_ "GenSigVtEn" SG_ 3221225472 Active_Fault_byte15_bit3 "TRUE";
BA_ "GenSigVtName" SG_ 3221225472 Active_Fault_byte15_bit3 "VtSig_DTCImplausCMbBByECM_A";
BA_ "GenSigCmt" SG_ 3221225472 Active_Fault_byte15_bit3 "DTCImplausCMbBByECM (ECM)";
BA_ "GenSigVtEn" SG_ 3221225472 Active_Fault_byte15_bit4 "TRUE";
BA_ "GenSigVtName" SG_ 3221225472 Active_Fault_byte15_bit4 "VtSig_DTCImplausCMbBByFSM_A";
BA_ "GenSigCmt" SG_ 3221225472 Active_Fault_byte15_bit4 "DTCImplausCMbBByFSM (CCM)";
BA_ "GenSigCmt" SG_ 3221225472 Active_Fault_byte15_bit5 "Reserved";
BA_ "GenSigVtEn" SG_ 3221225472 Active_Fault_byte15_bit6 "TRUE";
BA_ "GenSigVtName" SG_ 3221225472 Active_Fault_byte15_bit6 "VtSig_SetDTCImplausibleActB_A";
BA_ "GenSigCmt" SG_ 3221225472 Active_Fault_byte15_bit6 "Latch_Fault_byte15_bit6 (ABS)";
BA_ "GenSigVtEn" SG_ 3221225472 Active_Fault_byte15_bit7 "TRUE";
BA_ "GenSigVtName" SG_ 3221225472 Active_Fault_byte15_bit7 "VtSig_SetDTCImplausibleActECM_A";
BA_ "GenSigCmt" SG_ 3221225472 Active_Fault_byte15_bit7 "Latch_Fault_byte15_bit7 (ECM)";
BA_ "GenSigVtEn" SG_ 3221225472 Active_Fault_byte14_bit0 "TRUE";
BA_ "GenSigVtName" SG_ 3221225472 Active_Fault_byte14_bit0 "VtSig_VehLong2_A_Actl_QF_ErA";
BA_ "GenSigCmt" SG_ 3221225472 Active_Fault_byte14_bit0 "VehLong2_A_Actl QF Error (RCM)";
BA_ "GenSigVtEn" SG_ 3221225472 Active_Fault_byte14_bit1 "TRUE";
BA_ "GenSigVtName" SG_ 3221225472 Active_Fault_byte14_bit1 "VtSig_VehLat2_A_Actl_QF_ErA";
BA_ "GenSigCmt" SG_ 3221225472 Active_Fault_byte14_bit1 "VehLat2_A_Actl QF Error (RCM)";
BA_ "GenSigVtEn" SG_ 3221225472 Active_Fault_byte14_bit2 "TRUE";
BA_ "GenSigVtName" SG_ 3221225472 Active_Fault_byte14_bit2 "VtSig_AccDeny_B_RqIpc_UB_QF_Er";
BA_ "GenSigCmt" SG_ 3221225472 Active_Fault_byte14_bit2 "AccDeny_B_RqIpc_UB QF Error  (IPC)";
BA_ "GenSigVtEn" SG_ 3221225472 Active_Fault_byte14_bit3 "TRUE";
BA_ "GenSigVtName" SG_ 3221225472 Active_Fault_byte14_bit3 "VtSig_LaActDeny_B_Actl_QF_ErA";
BA_ "GenSigCmt" SG_ 3221225472 Active_Fault_byte14_bit3 "LaActDeny_B_Actl QF Error (PSCM)";
BA_ "GenSigVtEn" SG_ 3221225472 Active_Fault_byte14_bit4 "TRUE";
BA_ "GenSigVtName" SG_ 3221225472 Active_Fault_byte14_bit4 "VtSig_DrQltyDrv_D_StatGsm_QF_Er";
BA_ "GenSigCmt" SG_ 3221225472 Active_Fault_byte14_bit4 "DrQltyDrv_D_StatGsm QF Error (GSM)";
BA_ "GenSigVtEn" SG_ 3221225472 Active_Fault_byte14_bit5 "TRUE";
BA_ "GenSigVtName" SG_ 3221225472 Active_Fault_byte14_bit5 "VtSig_LROS_LKASwitchStatus_QFEA";
BA_ "GenSigCmt" SG_ 3221225472 Active_Fault_byte14_bit5 "LROS_LKASwitchStatus QF Error (LKASwitch)";
BA_ "GenSigVtEn" SG_ 3221225472 Active_Fault_byte14_bit6 "TRUE";
BA_ "GenSigVtName" SG_ 3221225472 Active_Fault_byte14_bit6 "VtSig_MatchConf_Validity_ErA";
BA_ "GenSigCmt" SG_ 3221225472 Active_Fault_byte14_bit6 "MatchConf_Validity Error (IPMA)";
BA_ "GenSigVtEn" SG_ 3221225472 Active_Fault_byte14_bit7 "TRUE";
BA_ "GenSigVtName" SG_ 3221225472 Active_Fault_byte14_bit7 "VtSig_Active_Fault_byte14_bit7";
BA_ "GenSigCmt" SG_ 3221225472 Active_Fault_byte14_bit7 "Latch_Fault_byte14_bit7 (ABS)";
BA_ "GenSigCmt" SG_ 3221225472 VBattState_VR_HTR "VR_HTR battery state";
BA_ "GenSigCmt" SG_ 3221225472 RawHeatrFltA2D "Raw heater filtered A2D counts";
BA_ "GenSigCmt" SG_ 3221225472 RawHeaterOutA2D "raw heater output A2D counts";
BA_ "GenSigCmt" SG_ 3221225472 HtrDrv "Heater driver enable";
BA_ "GenSigCmt" SG_ 3221225472 HeaterSTGOpenFailure_HP "Control internal module electronic failure";
BA_ "GenSigCmt" SG_ 3221225472 HeaterOutputShortCircuit_HP "Heater output short circuit fault";
BA_ "GenSigCmt" SG_ 3221225472 HeaterOutpurOpenCircuit_HP "Heater open circuit fault";
BA_ "GenSigVtEn" SG_ 3221225472 heavy_rain_failsafe "TRUE";
BA_ "GenSigVtName" SG_ 3221225472 heavy_rain_failsafe "VtSig_heavy_rain_failsafe";
BA_ "GenSigCmt" SG_ 3221225472 heavy_rain_failsafe "heavy_rain_failsafe";
BA_ "GenSigVtEn" SG_ 3221225472 heavy_rain_failsafe_A "TRUE";
BA_ "GenSigVtName" SG_ 3221225472 heavy_rain_failsafe_A "VtSig_heavy_rain_failsafe_A";
BA_ "GenSigCmt" SG_ 3221225472 heavy_rain_failsafe_A "heavy_rain_failsafe";
BA_ "GenSigCmt" SG_ 3221225472 History_Fault_bD_0 "Reserved";
BA_ "GenSigCmt" SG_ 3221225472 Active_Fault_byteD_bit0 "Reserved";
BA_ "GenSigVtEn" SG_ 3221225472 History_Fault_H_b10_0 "TRUE";
BA_ "GenSigVtName" SG_ 3221225472 History_Fault_H_b10_0 "VtSig_PCAN_330_IMUSecAval_H_b10_0";
BA_ "GenSigCmt" SG_ 3221225472 History_Fault_H_b10_0 "ABS_7 Missing Msg (VehYawComp_W_Actl)";
BA_ "GenSigVtEn" SG_ 3221225472 History_Fault_H_b10_4 "TRUE";
BA_ "GenSigVtName" SG_ 3221225472 History_Fault_H_b10_4 "VtSig_PB_1C3_PPEIEngTorqMiss_H_b10_4";
BA_ "GenSigCmt" SG_ 3221225472 History_Fault_H_b10_4 "BCM Missing Message (Ignition_Status)";
BA_ "GenSigVtEn" SG_ 3221225472 History_Fault_H_b10_6 "TRUE";
BA_ "GenSigVtName" SG_ 3221225472 History_Fault_H_b10_6 "VtSig_PB_1C5_PPEIDrvTorqMiss_H_b10_6";
BA_ "GenSigCmt" SG_ 3221225472 History_Fault_H_b10_6 "BCM_3 Missing Msg (HeadLghtSwtch_D_Stat)";
BA_ "GenSigVtEn" SG_ 3221225472 History_Fault_H_b10_7 "TRUE";
BA_ "GenSigVtName" SG_ 3221225472 History_Fault_H_b10_7 "VtSig_PB_1F5_PPEITransGenMiss_H_b10_7";
BA_ "GenSigCmt" SG_ 3221225472 History_Fault_H_b10_7 "IPC Missing Msg (AccDeny_B_RqIpc)";
BA_ "GenSigVtEn" SG_ 3221225472 History_Fault_b6_2 "TRUE";
BA_ "GenSigVtName" SG_ 3221225472 History_Fault_b6_2 "VtSig_History_Fault_b6_2";
BA_ "GenSigCmt" SG_ 3221225472 History_Fault_b6_2 "Bus off VCAN";
BA_ "GenSigVtEn" SG_ 3221225472 History_Fault_b6_4 "TRUE";
BA_ "GenSigVtName" SG_ 3221225472 History_Fault_b6_4 "VtSig_History_Fault_b6_4";
BA_ "GenSigCmt" SG_ 3221225472 History_Fault_b6_4 "Ethernet Hardware Fault";
BA_ "GenSigCmt" SG_ 3221225472 History_Fault_b1_7 "Reserved";
BA_ "GenSigVtEn" SG_ 3221225472 History_Fault_b0_0 "TRUE";
BA_ "GenSigVtName" SG_ 3221225472 History_Fault_b0_0 "VtSig_HeaterDriverShortToGround";
BA_ "GenSigCmt" SG_ 3221225472 History_Fault_b0_0 "HeaterDriverShortToGround";
BA_ "GenSigVtEn" SG_ 3221225472 Active_Fault_A_b10_0 "TRUE";
BA_ "GenSigCmt" SG_ 3221225472 Active_Fault_A_b10_0 "ABS_7 Missing Msg (VehYawComp_W_Actl)";
BA_ "GenSigVtName" SG_ 3221225472 Active_Fault_A_b10_0 "VtSig_LKAStchSTBorOPN_A";
BA_ "GenSigVtEn" SG_ 3221225472 Active_Fault_A_b10_4 "TRUE";
BA_ "GenSigCmt" SG_ 3221225472 Active_Fault_A_b10_4 "BCM Missing Message (Ignition_Status)";
BA_ "GenSigVtName" SG_ 3221225472 Active_Fault_A_b10_4 "VtSig_PB_1C3_PPEIEngTorqMiss_A_b10_4";
BA_ "GenSigVtEn" SG_ 3221225472 Active_Fault_A_b10_6 "TRUE";
BA_ "GenSigCmt" SG_ 3221225472 Active_Fault_A_b10_6 "BCM_3 Missing Msg (HeadLghtSwtch_D_Stat)";
BA_ "GenSigVtName" SG_ 3221225472 Active_Fault_A_b10_6 "VtSig_PB_1C5_PPEIDrvTorqMiss_A_b10_6";
BA_ "GenSigVtEn" SG_ 3221225472 Active_Fault_A_b10_7 "TRUE";
BA_ "GenSigCmt" SG_ 3221225472 Active_Fault_A_b10_7 "IPC Missing Msg (AccDeny_B_RqIpc)";
BA_ "GenSigVtName" SG_ 3221225472 Active_Fault_A_b10_7 "VtSig_PB_1F5_PPEITransGenMiss_A_b10_7";
BA_ "GenSigVtEn" SG_ 3221225472 Active_Fault_b6_2 "TRUE";
BA_ "GenSigVtName" SG_ 3221225472 Active_Fault_b6_2 "VtSig_Active_Fault_b6_2";
BA_ "GenSigCmt" SG_ 3221225472 Active_Fault_b6_2 "Bus off VCAN";
BA_ "GenSigVtEn" SG_ 3221225472 Active_Fault_b6_4 "TRUE";
BA_ "GenSigVtName" SG_ 3221225472 Active_Fault_b6_4 "VtSig_Active_Fault_b6_4";
BA_ "GenSigCmt" SG_ 3221225472 Active_Fault_b6_4 "Ethernet Hardware Fault";
BA_ "GenSigCmt" SG_ 3221225472 Active_Fault_byte1_bit7 "Reserved";
BA_ "GenSigVtEn" SG_ 3221225472 Active_Fault_byte0_bit0 "TRUE";
BA_ "GenSigVtName" SG_ 3221225472 Active_Fault_byte0_bit0 "VtSig_HeaterDriverShortToGroundA";
BA_ "GenSigCmt" SG_ 3221225472 Active_Fault_byte0_bit0 "HeaterDriverShortToGround";
BA_ "GenSigVtEn" SG_ 3221225472 History_Fault_H_bF_4 "TRUE";
BA_ "GenSigVtName" SG_ 3221225472 History_Fault_H_bF_4 "VtSig_PCAN_330_IMURCPri_H_bF_4";
BA_ "GenSigCmt" SG_ 3221225472 History_Fault_H_bF_4 "ABS_3 Missing Msg (VehLongOvrGnd_A_Est)";
BA_ "GenSigVtEn" SG_ 3221225472 History_Fault_H_bF_5 "TRUE";
BA_ "GenSigVtName" SG_ 3221225472 History_Fault_H_bF_5 "VtSig_PCAN_330_IMUChkSumPri_H_bF_5";
BA_ "GenSigCmt" SG_ 3221225472 History_Fault_H_bF_5 "ABS_4 Missing Msg (AccBrkDeny_B_Actl)";
BA_ "GenSigVtEn" SG_ 3221225472 History_Fault_H_bF_6 "TRUE";
BA_ "GenSigVtName" SG_ 3221225472 History_Fault_H_bF_6 "VtSig_PB_214_BrkPdDrvAppPrsAlRC_H_bF_6";
BA_ "GenSigCmt" SG_ 3221225472 History_Fault_H_bF_6 "ABS_5 Missing Msg (AccBrkTotTqMn_B_Actl)";
BA_ "GenSigVtEn" SG_ 3221225472 History_Fault_H_bF_7 "TRUE";
BA_ "GenSigVtName" SG_ 3221225472 History_Fault_H_bF_7 "VtSig_PB_214_BrkPdDrvAPrsStaPVal_H_bF_7";
BA_ "GenSigCmt" SG_ 3221225472 History_Fault_H_bF_7 "ABS_6 Missing Msg (CmbbDeny_B_ActlBrk)";
BA_ "GenSigVtEn" SG_ 3221225472 History_Fault_H_bE_7 "TRUE";
BA_ "GenSigVtName" SG_ 3221225472 History_Fault_H_bE_7 "VtSig_IncorrectSASInstall_H_bE_6";
BA_ "GenSigCmt" SG_ 3221225472 History_Fault_H_bE_7 "ECM_7 Missing Msg (CcStat_D_Actl)";
BA_ "GenSigCmt" SG_ 3221225472 History_Fault_bD_1 "Reserved";
BA_ "GenSigCmt" SG_ 3221225472 History_Fault_bD_2 "Reserved";
BA_ "GenSigVtEn" SG_ 3221225472 History_Fault_bC_0 "TRUE";
BA_ "GenSigVtName" SG_ 3221225472 History_Fault_bC_0 "VtSig_rcc_misalignment_fault";
BA_ "GenSigCmt" SG_ 3221225472 History_Fault_bC_0 "rcc_misalignment_fault";
BA_ "GenSigVtEn" SG_ 3221225472 History_Fault_bC_4 "TRUE";
BA_ "GenSigVtName" SG_ 3221225472 History_Fault_bC_4 "VtSig_HeaterFETDriver_Failure";
BA_ "GenSigCmt" SG_ 3221225472 History_Fault_bC_4 "Heater FET Driver Failure";
BA_ "GenSigCmt" SG_ 3221225472 History_Fault_bC_7 "Reserved";
BA_ "GenSigVtEn" SG_ 3221225472 History_Fault_bB_7 "TRUE";
BA_ "GenSigVtName" SG_ 3221225472 History_Fault_bB_7 "VtSig_sensor_alignment_plaus";
BA_ "GenSigCmt" SG_ 3221225472 History_Fault_bB_7 "sensor_alignment_plausiibility";
BA_ "GenSigVtEn" SG_ 3221225472 History_Fault_b9_4 "TRUE";
BA_ "GenSigVtName" SG_ 3221225472 History_Fault_b9_4 "VtSig_VfpCamPattFlt";
BA_ "GenSigCmt" SG_ 3221225472 History_Fault_b9_4 "VfpCamPattFlt";
BA_ "GenSigVtEn" SG_ 3221225472 History_Fault_b9_6 "TRUE";
BA_ "GenSigVtName" SG_ 3221225472 History_Fault_b9_6 "VtSig_roll_angle_failsafe";
BA_ "GenSigCmt" SG_ 3221225472 History_Fault_b9_6 "Roll angle failsafe";
BA_ "GenSigCmt" SG_ 3221225472 History_Fault_b8_0 "Heater for windshield mounted sensor, STG";
BA_ "GenSigVtName" SG_ 3221225472 History_Fault_b8_0 "VtSig_History_Fault_b8_0";
BA_ "GenSigVtEn" SG_ 3221225472 History_Fault_b8_0 "TRUE";
BA_ "GenSigCmt" SG_ 3221225472 History_Fault_b8_1 "Heater for windshiled mounter sensor, open";
BA_ "GenSigVtEn" SG_ 3221225472 History_Fault_b8_1 "TRUE";
BA_ "GenSigVtName" SG_ 3221225472 History_Fault_b8_1 "VtSig_History_Fault_b8_1";
BA_ "GenSigCmt" SG_ 3221225472 History_Fault_b8_2 "Control module internal electronic failure";
BA_ "GenSigVtEn" SG_ 3221225472 History_Fault_b8_2 "TRUE";
BA_ "GenSigVtName" SG_ 3221225472 History_Fault_b8_2 "VtSig_History_Fault_b8_2";
BA_ "GenSigVtEn" SG_ 3221225472 Active_Fault_A_bF_4 "TRUE";
BA_ "GenSigVtName" SG_ 3221225472 Active_Fault_A_bF_4 "VtSig_PCAN_330_IMURCPri_A_bF_4";
BA_ "GenSigCmt" SG_ 3221225472 Active_Fault_A_bF_4 "ABS_3 Missing Msg (VehLongOvrGnd_A_Est)";
BA_ "GenSigVtEn" SG_ 3221225472 Active_Fault_A_bF_5 "TRUE";
BA_ "GenSigVtName" SG_ 3221225472 Active_Fault_A_bF_5 "VtSig_PCAN_330_IMUChkSumPri_A_bF_5";
BA_ "GenSigCmt" SG_ 3221225472 Active_Fault_A_bF_5 "ABS_4 Missing Msg (AccBrkDeny_B_Actl)";
BA_ "GenSigVtEn" SG_ 3221225472 Active_Fault_A_bF_6 "TRUE";
BA_ "GenSigVtName" SG_ 3221225472 Active_Fault_A_bF_6 "VtSig_PB_214_BrkPdDrvAppPrsAlRC_A_bF_6";
BA_ "GenSigCmt" SG_ 3221225472 Active_Fault_A_bF_6 "ABS_5 Missing Msg (AccBrkTotTqMn_B_Actl)";
BA_ "GenSigVtEn" SG_ 3221225472 Active_Fault_A_bF_7 "TRUE";
BA_ "GenSigVtName" SG_ 3221225472 Active_Fault_A_bF_7 "VtSig_PB_214_BrkPdDrvAPrsStaPVal_A_bF_7";
BA_ "GenSigCmt" SG_ 3221225472 Active_Fault_A_bF_7 "ABS_6 Missing Msg (CmbbDeny_B_ActlBrk)";
BA_ "GenSigVtEn" SG_ 3221225472 Active_Fault_A_bE_7 "TRUE";
BA_ "GenSigVtName" SG_ 3221225472 Active_Fault_A_bE_7 "VtSig_IncorrectSASInstall_A_bE_6";
BA_ "GenSigCmt" SG_ 3221225472 Active_Fault_A_bE_7 "ECM_7 Missing Msg (CcStat_D_Actl)";
BA_ "GenSigCmt" SG_ 3221225472 Active_Fault_byteD_bit1 "Reserved";
BA_ "GenSigCmt" SG_ 3221225472 Active_Fault_byteD_bit2 "Reserved";
BA_ "GenSigVtEn" SG_ 3221225472 Active_Fault_bC_0 "TRUE";
BA_ "GenSigVtName" SG_ 3221225472 Active_Fault_bC_0 "VtSig_Active_Fault_bC_0";
BA_ "GenSigCmt" SG_ 3221225472 Active_Fault_bC_0 "rcc_misalignment_fault";
BA_ "GenSigVtEn" SG_ 3221225472 Active_Fault_byteC_bit4 "TRUE";
BA_ "GenSigVtName" SG_ 3221225472 Active_Fault_byteC_bit4 "VtSig_HeaterFETDriver_Failure_A";
BA_ "GenSigCmt" SG_ 3221225472 Active_Fault_byteC_bit4 "Heater FET Driver Failure";
BA_ "GenSigCmt" SG_ 3221225472 Active_Fault_byteC_bit7 "Reserved";
BA_ "GenSigVtEn" SG_ 3221225472 Active_Fault_bB_7 "TRUE";
BA_ "GenSigVtName" SG_ 3221225472 Active_Fault_bB_7 "VtSig_Active_Fault";
BA_ "GenSigCmt" SG_ 3221225472 Active_Fault_bB_7 "sensor_alignment_plausiibility";
BA_ "GenSigVtEn" SG_ 3221225472 Active_Fault_b9_4 "TRUE";
BA_ "GenSigVtName" SG_ 3221225472 Active_Fault_b9_4 "VtSig_Active_Fault";
BA_ "GenSigCmt" SG_ 3221225472 Active_Fault_b9_4 "VfpCamPattFlt";
BA_ "GenSigVtEn" SG_ 3221225472 Active_Fault_b9_6 "TRUE";
BA_ "GenSigVtName" SG_ 3221225472 Active_Fault_b9_6 "VtSig_Active_Fault";
BA_ "GenSigCmt" SG_ 3221225472 Active_Fault_b9_6 "Roll angle failsafe";
BA_ "GenSigCmt" SG_ 3221225472 Active_Fault_byte8_bit0 "Heater for winshield mounted sensor, STG";
BA_ "GenSigVtEn" SG_ 3221225472 Active_Fault_byte8_bit0 "TRUE";
BA_ "GenSigVtName" SG_ 3221225472 Active_Fault_byte8_bit0 "VtSig_History_Fault_b8_0_A";
BA_ "GenSigCmt" SG_ 3221225472 Active_Fault_byte8_bit1 "Heater for windshield mounter sensor, open";
BA_ "GenSigVtEn" SG_ 3221225472 Active_Fault_byte8_bit1 "TRUE";
BA_ "GenSigVtName" SG_ 3221225472 Active_Fault_byte8_bit1 "VtSig_History_Fault_b8_1_A";
BA_ "GenSigCmt" SG_ 3221225472 Active_Fault_byte8_bit2 "Control module internal electronic failure";
BA_ "GenSigVtEn" SG_ 3221225472 Active_Fault_byte8_bit2 "TRUE";
BA_ "GenSigVtName" SG_ 3221225472 Active_Fault_byte8_bit2 "VtSig_Active_Fault_byte8_bit2";
BA_ "GenSigCmt" SG_ 263 Sign_Update_Denied "Sign Updated";
BA_ "GenSigCmt" SG_ 263 Sign_QF_Denied "Sign QF";
BA_ "GenSigCmt" SG_ 263 LROS_V_Host_Long_front "Host longitudinal velocity";
BA_ "GenSigCmt" SG_ 263 LROS_V_Host_Lat_front "Host lateral velocity";
BA_ "GenSigCmt" SG_ 263 Light_Update_Denied "Light Updated";
BA_ "GenSigCmt" SG_ 263 Light_QF_Denied "Light QF";
BA_ "GenSigCmt" SG_ 263 Lane_Update_Denied "Lane Updated";
BA_ "GenSigCmt" SG_ 263 Lane_QF_Denied "Lane QF";
BA_ "GenSigCmt" SG_ 263 FCW_Update_Denied "FCW Updated";
BA_ "GenSigCmt" SG_ 263 FCW_QF_Denied "FCW QF";
BA_ "GenSigCmt" SG_ 263 DAS_Update_Denied "DAS Updated";
BA_ "GenSigCmt" SG_ 263 DAS_QF_Denied "DAS QF";
BA_ "GenSigCmt" SG_ 263 CMbB_Updated_Denied "CMbB Updated";
BA_ "GenSigCmt" SG_ 263 CMbB_QF_Denied "CMbB QF";
BA_ "GenSigCmt" SG_ 263 ACC_Update_Denied "ACC Updated";
BA_ "GenSigCmt" SG_ 263 ACC_QF_Denied "ACC QF";
BA_ "GenSigCmt" SG_ 262 LROSStatus_bit2 "Undefined";
BA_ "GenSigCmt" SG_ 262 LROSStatus_bit10 "Undefined";
BA_ "GenSigCmt" SG_ 262 VisionAlignmentOutOfRange "LROSStatus VisionAlignmentOutOfRange";
BA_ "GenSigCmt" SG_ 262 VisionSystemNotOperational "LROSStatus VisionSystemNotOperational";
BA_ "GenSigVtName" SG_ 262 VisionSystemNotOperational "*";
BA_ "GenSigVtIndex" SG_ 262 VisionSystemNotOperational "*";
BA_ "GenSigVtEn" SG_ 262 VisionSystemNotOperational "*";
BA_ "GenSigCmt" SG_ 262 VisionExternalConditionsNotOK "LROSStatus VisionExternalConditionsNotOK";
BA_ "GenSigVtName" SG_ 262 VisionExternalConditionsNotOK "*";
BA_ "GenSigVtIndex" SG_ 262 VisionExternalConditionsNotOK "*";
BA_ "GenSigVtEn" SG_ 262 VisionExternalConditionsNotOK "*";
BA_ "GenSigCmt" SG_ 262 VisionBlockageDetected "LROSStatus VisionBlockageDetected";
BA_ "GenSigVtName" SG_ 262 VisionBlockageDetected "*";
BA_ "GenSigVtIndex" SG_ 262 VisionBlockageDetected "*";
BA_ "GenSigVtEn" SG_ 262 VisionBlockageDetected "*";
BA_ "GenSigCmt" SG_ 262 VisionAlignmentNotStarted "LROSStatus VisionAlignmentNotStarted";
BA_ "GenSigVtName" SG_ 262 VisionAlignmentNotStarted "*";
BA_ "GenSigVtIndex" SG_ 262 VisionAlignmentNotStarted "*";
BA_ "GenSigVtEn" SG_ 262 VisionAlignmentNotStarted "*";
BA_ "GenSigCmt" SG_ 262 VisionAlignmentIncomplete "LROSStatus VisionAlignmentIncomplete";
BA_ "GenSigVtName" SG_ 262 VisionAlignmentIncomplete "*";
BA_ "GenSigVtIndex" SG_ 262 VisionAlignmentIncomplete "*";
BA_ "GenSigVtEn" SG_ 262 VisionAlignmentIncomplete "*";
BA_ "GenSigCmt" SG_ 262 SensorDataUpdating "LROSStatus SensorDataUpdating";
BA_ "GenSigVtName" SG_ 262 SensorDataUpdating "*";
BA_ "GenSigVtIndex" SG_ 262 SensorDataUpdating "*";
BA_ "GenSigVtEn" SG_ 262 SensorDataUpdating "*";
BA_ "GenSigCmt" SG_ 262 RadarExternalConditionsNotOK "LROSStatus RadarExternalConditionsNotOK";
BA_ "GenSigVtName" SG_ 262 RadarExternalConditionsNotOK "*";
BA_ "GenSigVtIndex" SG_ 262 RadarExternalConditionsNotOK "*";
BA_ "GenSigVtEn" SG_ 262 RadarExternalConditionsNotOK "*";
BA_ "GenSigCmt" SG_ 262 RadarBlockageDetected "LROSStatus RadarBlockageDetected";
BA_ "GenSigVtName" SG_ 262 RadarBlockageDetected "*";
BA_ "GenSigVtIndex" SG_ 262 RadarBlockageDetected "*";
BA_ "GenSigVtEn" SG_ 262 RadarBlockageDetected "*";
BA_ "GenSigCmt" SG_ 262 RadarAlignmentOutOfRange "LROSStatus RadarAlignmentOutOfRange";
BA_ "GenSigVtName" SG_ 262 RadarAlignmentOutOfRange "*";
BA_ "GenSigVtIndex" SG_ 262 RadarAlignmentOutOfRange "*";
BA_ "GenSigVtEn" SG_ 262 RadarAlignmentOutOfRange "*";
BA_ "GenSigCmt" SG_ 262 RadarAlignmentNotStarted "LROSStatus RadarAlignmentNotStarted";
BA_ "GenSigVtName" SG_ 262 RadarAlignmentNotStarted "*";
BA_ "GenSigVtIndex" SG_ 262 RadarAlignmentNotStarted "*";
BA_ "GenSigVtEn" SG_ 262 RadarAlignmentNotStarted "*";
BA_ "GenSigCmt" SG_ 262 RadarAlignmentIncomplete "LROSStatus RadarAlignmentIncomplete";
BA_ "GenSigVtName" SG_ 262 RadarAlignmentIncomplete "*";
BA_ "GenSigVtIndex" SG_ 262 RadarAlignmentIncomplete "*";
BA_ "GenSigVtEn" SG_ 262 RadarAlignmentIncomplete "*";
BA_ "GenSigCmt" SG_ 262 CommunicationError "LROSStatus CommunicationError";
BA_ "GenSigVtName" SG_ 262 CommunicationError "*";
BA_ "GenSigVtIndex" SG_ 262 CommunicationError "*";
BA_ "GenSigVtEn" SG_ 262 CommunicationError "*";
BA_ "GenSigCmt" SG_ 262 RadarSystemNotOperational "LROSStatus RadarSystemNotOperational";
BA_ "GenSigCmt" SG_ 262 LROS_YawRate_Est "Yaw rate estimate";
BA_ "GenSigCmt" SG_ 262 LROS_YawRate "Yaw rate";
BA_ "GenSigCmt" SG_ 262 LROS_FiltVehicleSpeedOverGround "Filtered vehicle speed";
BA_ "GenSigSendType" SG_ 261 Road_Type 1;
BA_ "GenSigCmt" SG_ 261 Unfilt_Comp_Yaw_Rate_QF "Unfiltered Compensated Yaw Rate";
BA_ "GenSigVtName" SG_ 261 Unfilt_Comp_Yaw_Rate_QF "VtSig_Unfilt_Comp_Yaw_Rate_QF";
BA_ "GenSigVtEn" SG_ 261 Unfilt_Comp_Yaw_Rate_QF "TRUE";
BA_ "GenSigSendType" SG_ 261 Unfilt_Comp_Yaw_Rate_QF 1;
BA_ "GenSigSendType" SG_ 261 Unfilt_Comp_Yaw_Rate 1;
BA_ "GenSigCmt" SG_ 261 Yaw_Rate_SA_QF "Yaw rate steering angle QF";
BA_ "GenSigVtName" SG_ 261 Yaw_Rate_SA_QF "VtSig_Yaw_Rate_SA_QF";
BA_ "GenSigVtEn" SG_ 261 Yaw_Rate_SA_QF "TRUE";
BA_ "GenSigSendType" SG_ 261 Yaw_Rate_SA_QF 1;
BA_ "GenSigCmt" SG_ 261 Yaw_Rate_Estimation "Yaw rate estimation";
BA_ "GenSigSendType" SG_ 261 Yaw_Rate_Estimation 1;
BA_ "GenSigCmt" SG_ 261 Yaw_Rate_Drifting "Yaw rate drifting";
BA_ "GenSigVtName" SG_ 261 Yaw_Rate_Drifting "VtSig_Yaw_Rate_Drifting";
BA_ "GenSigVtEn" SG_ 261 Yaw_Rate_Drifting "TRUE";
BA_ "GenSigSendType" SG_ 261 Yaw_Rate_Drifting 1;
BA_ "GenSigCmt" SG_ 261 Yaw_Rate_Bias_Dif "Yaw rate bias differences";
BA_ "GenSigSendType" SG_ 261 Yaw_Rate_Bias_Dif 1;
BA_ "GenSigCmt" SG_ 261 Yaw_Rate_Bias "Yaw rate bias";
BA_ "GenSigSendType" SG_ 261 Yaw_Rate_Bias 1;
BA_ "GenSigSendType" SG_ 1796 VfpSpiMsgRxBadSeqCtr 1;
BA_ "GenSigSendType" SG_ 1796 VfpSpiMsgRxBadHdrCtr 1;
BA_ "GenSigSendType" SG_ 1796 VfpSpiMsg11RxCtr 1;
BA_ "GenSigSendType" SG_ 1796 VfpSpiMsg10RxCtr 1;
BA_ "GenSigSendType" SG_ 526 CAN_LROS_TRIGGER_TIMESTAMP_LSB 1;
BA_ "GenSigSendType" SG_ 526 CAN_LROS_T_TRACKER_INDEX_LSB 1;
BA_ "GenSigSendType" SG_ 526 CAN_LROS_T_LOOK_INDEX_LSB 1;
BA_ "GenSigSendType" SG_ 526 CAN_LROS_T_FRAME_INDEX_LSB 1;
BA_ "GenSigSendType" SG_ 525 CAN_LROS_OUTPUT_TIMESTAMP_LSB 1;
BA_ "GenSigSendType" SG_ 525 CAN_LROS_O_TRACKER_INDEX_LSB 1;
BA_ "GenSigSendType" SG_ 525 CAN_LROS_O_LOOK_INDEX_LSB 1;
BA_ "GenSigSendType" SG_ 525 CAN_LROS_O_FRAME_INDEX_LSB 1;
BA_ "GenSigSendType" SG_ 570 CAN_IPC_TIMESTAMP_VIS_H 1;
BA_ "GenSigCmt" SG_ 570 CAN_IPC_TIMESTAMP_VIS_H "The timestamp when the VFP transmitted the IPC msg in VFP clock time";
BA_ "GenSigSendType" SG_ 570 CAN_IPC_REF_INDEX_VIS_H 1;
BA_ "GenSigCmt" SG_ 570 CAN_IPC_REF_INDEX_VIS_H "The second reference index for the data associated with the IPC msg";
BA_ "GenSigSendType" SG_ 570 CAN_IPC_REF_INDEX_2_VIS_H 1;
BA_ "GenSigCmt" SG_ 570 CAN_IPC_REF_INDEX_2_VIS_H "A reference index associated with the transmitted data";
BA_ "GenSigSendType" SG_ 568 CAN_IPC_TIMESTAMP_TSEL_H 1;
BA_ "GenSigCmt" SG_ 568 CAN_IPC_TIMESTAMP_TSEL_H "The timestamp when the VFP transmitted the IPC msg in VFP clock time";
BA_ "GenSigSendType" SG_ 568 CAN_IPC_REF_INDEX_TSEL_H 1;
BA_ "GenSigCmt" SG_ 568 CAN_IPC_REF_INDEX_TSEL_H "The second reference index for the data associated with the IPC msg";
BA_ "GenSigSendType" SG_ 568 CAN_IPC_REF_INDEX_2_TSEL_H 1;
BA_ "GenSigCmt" SG_ 568 CAN_IPC_REF_INDEX_2_TSEL_H "A reference index associated with the transmitted data";
BA_ "GenSigSendType" SG_ 567 CAN_IPC_TIMESTAMP_TRAFF_H 1;
BA_ "GenSigCmt" SG_ 567 CAN_IPC_TIMESTAMP_TRAFF_H "The timestamp when the VFP transmitted the IPC msg in VFP clock time";
BA_ "GenSigSendType" SG_ 567 CAN_IPC_REF_INDEX_TRAFF_H 1;
BA_ "GenSigCmt" SG_ 567 CAN_IPC_REF_INDEX_TRAFF_H "The second reference index for the data associated with the IPC msg";
BA_ "GenSigSendType" SG_ 567 CAN_IPC_REF_INDEX_2_TRAFF_H 1;
BA_ "GenSigCmt" SG_ 567 CAN_IPC_REF_INDEX_2_TRAFF_H "A reference index associated with the transmitted data";
BA_ "GenSigSendType" SG_ 566 CAN_IPC_TIMESTAMP_ROAD_H 1;
BA_ "GenSigCmt" SG_ 566 CAN_IPC_TIMESTAMP_ROAD_H "The timestamp when the VFP transmitted the IPC msg in VFP clock time";
BA_ "GenSigSendType" SG_ 566 CAN_IPC_REF_INDEX_ROAD_H 1;
BA_ "GenSigCmt" SG_ 566 CAN_IPC_REF_INDEX_ROAD_H "The second reference index for the data associated with the IPC msg";
BA_ "GenSigSendType" SG_ 565 CAN_IPC_TIMESTAMP_OBJ_H 1;
BA_ "GenSigCmt" SG_ 565 CAN_IPC_TIMESTAMP_OBJ_H "The timestamp when the VFP transmitted the IPC msg in VFP clock time";
BA_ "GenSigSendType" SG_ 565 CAN_IPC_REF_INDEX_OBJ_H 1;
BA_ "GenSigCmt" SG_ 565 CAN_IPC_REF_INDEX_OBJ_H "The second reference index for the data associated with the IPC msg";
BA_ "GenSigSendType" SG_ 564 CAN_IPC_TIMESTAMP_LIGHT_H 1;
BA_ "GenSigCmt" SG_ 564 CAN_IPC_TIMESTAMP_LIGHT_H "The timestamp when the VFP transmitted the IPC msg in VFP clock time";
BA_ "GenSigSendType" SG_ 564 CAN_IPC_REF_INDEX_LIGHT_H 1;
BA_ "GenSigCmt" SG_ 564 CAN_IPC_REF_INDEX_LIGHT_H "The second reference index for the data associated with the IPC msg";
BA_ "GenSigSendType" SG_ 563 CAN_IPC_TIMESTAMP_FUS_H 1;
BA_ "GenSigCmt" SG_ 563 CAN_IPC_TIMESTAMP_FUS_H "The timestamp when the VFP transmitted the IPC msg in VFP clock time";
BA_ "GenSigSendType" SG_ 563 CAN_IPC_REF_INDEX_FUS_H 1;
BA_ "GenSigCmt" SG_ 563 CAN_IPC_REF_INDEX_FUS_H "The second reference index for the data associated with the IPC msg";
BA_ "GenSigSendType" SG_ 563 CAN_IPC_REF_INDEX_2_FUS_H 1;
BA_ "GenSigCmt" SG_ 563 CAN_IPC_REF_INDEX_2_FUS_H "A reference index associated with the transmitted data";
BA_ "GenSigSendType" SG_ 755 xcp_cwmp_slave_daq_byte_7 1;
BA_ "GenSigSendType" SG_ 755 xcp_cwmp_slave_daq_byte_6 1;
BA_ "GenSigSendType" SG_ 755 xcp_cwmp_slave_daq_byte_5 1;
BA_ "GenSigSendType" SG_ 755 xcp_cwmp_slave_daq_byte_4 1;
BA_ "GenSigSendType" SG_ 755 xcp_cwmp_slave_daq_byte_3 1;
BA_ "GenSigSendType" SG_ 755 xcp_cwmp_slave_daq_byte_2 1;
BA_ "GenSigSendType" SG_ 755 xcp_cwmp_slave_daq_byte_1 1;
BA_ "GenSigSendType" SG_ 755 xcp_cwmp_slave_daq_byte_0 1;
BA_ "GenSigCmt" SG_ 256 SWP3_PART_NUMBER_SUFFIX "Part Number";
BA_ "GenSigCmt" SG_ 256 SWP3_CAL_MINOR_REVISION "Calibration Minor Revision";
BA_ "GenSigCmt" SG_ 256 SWP3_CAL_MAJOR_REVISION "Calibration Major Revision";
BA_ "GenSigCmt" SG_ 256 SWP3_CAL_FIELD_REVISION "Calibration Field Revision";
BA_ "GenSigCmt" SG_ 16 VfpIoSts "VFP IO Status";
BA_ "GenSigCmt" SG_ 16 VFP_Power_Mode_State "VFP power mode state";
BA_ "GenSigCmt" SG_ 16 VBattState_V_RANGE_DTC "V_RANGE_DTC battery state";
BA_ "GenSigCmt" SG_ 16 ResetEyeQ "Soft reset of the EyeQ3";
BA_ "GenSigCmt" SG_ 16 RawPwrA2D "Raw supply voltage A2D counts";
BA_ "GenSigCmt" SG_ 16 EyeQPOR "Power-on-reset of the EyeQ3";
BA_ "GenSigCmt" SG_ 16 EN3V3 "3.3V enable";
BA_ "GenSigCmt" SG_ 16 EN1V8 "1.8V enable";
BA_ "GenSigCmt" SG_ 16 EN1V2 "1.2V enable";
BA_ "SystemSignalLongSymbol" SG_ 264 SUBSYSTEMCOMMUNICATIONFAULT_A_b5 "SUBSYSTEMCOMMUNICATIONFAULT_A_b5_5";
BA_ "SystemSignalLongSymbol" SG_ 264 RADARVISCORRELATIONFAILSAFE_A_b3 "RADARVISCORRELATIONFAILSAFE_A_b3_5";
BA_ "GenSigSendType" SG_ 1940 EH_Slope_Linear_0 1;
BA_ "GenSigVtEn" SG_ 1940 EH_Slope_Linear_0 "TRUE";
BA_ "GenSigVtName" SG_ 1940 EH_Slope_Linear_0 "VtSig_EH_Slope_Linear_0";
BA_ "GenSigSendType" SG_ 1940 EH_Country_Code_0 1;
BA_ "GenSigVtEn" SG_ 1940 EH_Country_Code_0 "TRUE";
BA_ "GenSigVtName" SG_ 1940 EH_Country_Code_0 "VtSig_EH_Shape_Point_Distance";
BA_ "GenSigSendType" SG_ 1940 EH_No_Lanes_Drv_Dir_0 1;
BA_ "GenSigVtEn" SG_ 1940 EH_No_Lanes_Drv_Dir_0 "TRUE";
BA_ "GenSigVtName" SG_ 1940 EH_No_Lanes_Drv_Dir_0 "VtSig_EH_No_Lanes_Drv_Dir_0";
BA_ "GenSigSendType" SG_ 1940 EH_Stub_Form_Of_Way_0 1;
BA_ "GenSigVtEn" SG_ 1940 EH_Stub_Form_Of_Way_0 "TRUE";
BA_ "GenSigVtName" SG_ 1940 EH_Stub_Form_Of_Way_0 "VtSig_EH_Stub_Form_Of_Way_0";
BA_ "GenSigSendType" SG_ 1940 EH_Stub_distance_0 1;
BA_ "GenSigVtEn" SG_ 1940 EH_Stub_distance_0 "TRUE";
BA_ "GenSigVtName" SG_ 1940 EH_Stub_distance_0 "VtSig_EH_Stub_distance_0";
BA_ "GenSigSendType" SG_ 1940 EH_Eff_Sl_0 1;
BA_ "GenSigVtName" SG_ 1940 EH_Eff_Sl_0 "VtSig_EH_Eff_SI_0";
BA_ "GenSigVtEn" SG_ 1940 EH_Eff_Sl_0 "TRUE";
BA_ "GenSigSendType" SG_ 1940 EH_Posted_Sl_0 1;
BA_ "GenSigVtEn" SG_ 1940 EH_Posted_Sl_0 "TRUE";
BA_ "GenSigVtName" SG_ 1940 EH_Posted_Sl_0 "VtSig_EH_Posted_SI_0";
BA_ "GenSigSendType" SG_ 1940 EH_off_road 1;
BA_ "GenSigVtName" SG_ 1940 EH_off_road "Vt_Sig_EH_Driving_Side_0";
BA_ "GenSigVtEn" SG_ 1940 EH_off_road "TRUE";
BA_ "GenSigVtEn" SG_ 1698 VIS_TSR_SIGN_VARIABLE_10 "TRUE";
BA_ "GenSigVtName" SG_ 1698 VIS_TSR_SIGN_VARIABLE_10 "VtSig_VIS_TSR_SIGN_VARIABLE_10";
BA_ "GenSigSendType" SG_ 1698 VIS_TSR_SIGN_VARIABLE_10 1;
BA_ "GenSigSendType" SG_ 1698 VIS_TSR_SIGN_VALUE_10 1;
BA_ "GenSigVtEn" SG_ 1698 VIS_TSR_SIGN_TYPE_10 "TRUE";
BA_ "GenSigVtName" SG_ 1698 VIS_TSR_SIGN_TYPE_10 "VtSig_VIS_TSR_SIGN_TYPE_10";
BA_ "GenSigSendType" SG_ 1698 VIS_TSR_SIGN_TYPE_10 1;
BA_ "GenSigVtEn" SG_ 1698 VIS_TSR_SIGN_SUPPL_TYPE2_10 "TRUE";
BA_ "GenSigVtName" SG_ 1698 VIS_TSR_SIGN_SUPPL_TYPE2_10 "VtSig_VIS_TSR_SIGN_SUPPL_TYPE2_10";
BA_ "GenSigSendType" SG_ 1698 VIS_TSR_SIGN_SUPPL_TYPE2_10 1;
BA_ "GenSigVtEn" SG_ 1698 VIS_TSR_SIGN_SUPPL_TYPE1_10 "TRUE";
BA_ "GenSigVtName" SG_ 1698 VIS_TSR_SIGN_SUPPL_TYPE1_10 "VtSig_VIS_TSR_SIGN_SUPPL_TYPE1_10";
BA_ "GenSigSendType" SG_ 1698 VIS_TSR_SIGN_SUPPL_TYPE1_10 1;
BA_ "GenSigVtEn" SG_ 1698 VIS_TSR_SIGN_POSITION_10 "TRUE";
BA_ "GenSigVtName" SG_ 1698 VIS_TSR_SIGN_POSITION_10 "VtSig_VIS_TSR_SIGN_POSITION_10";
BA_ "GenSigSendType" SG_ 1698 VIS_TSR_SIGN_POSITION_10 1;
BA_ "GenSigVtEn" SG_ 1698 VIS_TSR_SIGN_LANE_10 "TRUE";
BA_ "GenSigVtName" SG_ 1698 VIS_TSR_SIGN_LANE_10 "VtSig_VIS_TSR_SIGN_LANE_10";
BA_ "GenSigSendType" SG_ 1698 VIS_TSR_SIGN_LANE_10 1;
BA_ "GenSigSendType" SG_ 1698 VIS_TSR_SIGN_ID_10 1;
BA_ "GenSigVtEn" SG_ 1698 VIS_TSR_SIGN_EMBEDDED_SCENE_10 "TRUE";
BA_ "GenSigVtName" SG_ 1698 VIS_TSR_SIGN_EMBEDDED_SCENE_10 "VtSig_VIS_TSR_SIGN_EMBEDDED_SCENE_10";
BA_ "GenSigSendType" SG_ 1698 VIS_TSR_SIGN_EMBEDDED_SCENE_10 1;
BA_ "GenSigVtEn" SG_ 1698 VIS_TSR_SCENE_STATUS_10 "TRUE";
BA_ "GenSigVtName" SG_ 1698 VIS_TSR_SCENE_STATUS_10 "VtSig_VIS_TSR_SCENE_STATUS_10";
BA_ "GenSigSendType" SG_ 1698 VIS_TSR_SCENE_STATUS_10 1;
BA_ "GenSigSendType" SG_ 1698 VIS_TSR_SCENE_ID_10 1;
BA_ "GenSigVtEn" SG_ 1697 VIS_TSR_SIGN_VARIABLE_9 "TRUE";
BA_ "GenSigVtName" SG_ 1697 VIS_TSR_SIGN_VARIABLE_9 "VtSig_VIS_TSR_SIGN_VARIABLE_9";
BA_ "GenSigSendType" SG_ 1697 VIS_TSR_SIGN_VARIABLE_9 1;
BA_ "GenSigSendType" SG_ 1697 VIS_TSR_SIGN_VALUE_9 1;
BA_ "GenSigVtEn" SG_ 1697 VIS_TSR_SIGN_TYPE_9 "TRUE";
BA_ "GenSigVtName" SG_ 1697 VIS_TSR_SIGN_TYPE_9 "VtSig_VIS_TSR_SIGN_TYPE_9";
BA_ "GenSigSendType" SG_ 1697 VIS_TSR_SIGN_TYPE_9 1;
BA_ "GenSigVtEn" SG_ 1697 VIS_TSR_SIGN_SUPPL_TYPE2_9 "TRUE";
BA_ "GenSigVtName" SG_ 1697 VIS_TSR_SIGN_SUPPL_TYPE2_9 "VtSig_VIS_TSR_SIGN_SUPPL_TYPE2_9";
BA_ "GenSigSendType" SG_ 1697 VIS_TSR_SIGN_SUPPL_TYPE2_9 1;
BA_ "GenSigVtEn" SG_ 1697 VIS_TSR_SIGN_SUPPL_TYPE1_9 "TRUE";
BA_ "GenSigVtName" SG_ 1697 VIS_TSR_SIGN_SUPPL_TYPE1_9 "VtSig_VIS_TSR_SIGN_SUPPL_TYPE1_9";
BA_ "GenSigSendType" SG_ 1697 VIS_TSR_SIGN_SUPPL_TYPE1_9 1;
BA_ "GenSigVtEn" SG_ 1697 VIS_TSR_SIGN_POSITION_9 "TRUE";
BA_ "GenSigVtName" SG_ 1697 VIS_TSR_SIGN_POSITION_9 "VtSig_VIS_TSR_SIGN_POSITION_9";
BA_ "GenSigSendType" SG_ 1697 VIS_TSR_SIGN_POSITION_9 1;
BA_ "GenSigVtEn" SG_ 1697 VIS_TSR_SIGN_LANE_9 "TRUE";
BA_ "GenSigVtName" SG_ 1697 VIS_TSR_SIGN_LANE_9 "VtSig_VIS_TSR_SIGN_LANE_9";
BA_ "GenSigSendType" SG_ 1697 VIS_TSR_SIGN_LANE_9 1;
BA_ "GenSigSendType" SG_ 1697 VIS_TSR_SIGN_ID_9 1;
BA_ "GenSigVtEn" SG_ 1697 VIS_TSR_SIGN_EMBEDDED_SCENE_9 "TRUE";
BA_ "GenSigVtName" SG_ 1697 VIS_TSR_SIGN_EMBEDDED_SCENE_9 "VtSig_VIS_TSR_SIGN_EMBEDDED_SCENE_9";
BA_ "GenSigSendType" SG_ 1697 VIS_TSR_SIGN_EMBEDDED_SCENE_9 1;
BA_ "GenSigVtEn" SG_ 1697 VIS_TSR_SCENE_STATUS_9 "TRUE";
BA_ "GenSigVtName" SG_ 1697 VIS_TSR_SCENE_STATUS_9 "VtSig_VIS_TSR_SCENE_STATUS_9";
BA_ "GenSigSendType" SG_ 1697 VIS_TSR_SCENE_STATUS_9 1;
BA_ "GenSigSendType" SG_ 1697 VIS_TSR_SCENE_ID_9 1;
BA_ "GenSigVtEn" SG_ 1696 VIS_TSR_SIGN_VARIABLE_8 "TRUE";
BA_ "GenSigVtName" SG_ 1696 VIS_TSR_SIGN_VARIABLE_8 "VtSig_VIS_TSR_SIGN_VARIABLE_8";
BA_ "GenSigSendType" SG_ 1696 VIS_TSR_SIGN_VARIABLE_8 1;
BA_ "GenSigSendType" SG_ 1696 VIS_TSR_SIGN_VALUE_8 1;
BA_ "GenSigVtEn" SG_ 1696 VIS_TSR_SIGN_TYPE_8 "TRUE";
BA_ "GenSigVtName" SG_ 1696 VIS_TSR_SIGN_TYPE_8 "VtSig_VIS_TSR_SIGN_TYPE_8";
BA_ "GenSigSendType" SG_ 1696 VIS_TSR_SIGN_TYPE_8 1;
BA_ "GenSigVtEn" SG_ 1696 VIS_TSR_SIGN_SUPPL_TYPE2_8 "TRUE";
BA_ "GenSigVtName" SG_ 1696 VIS_TSR_SIGN_SUPPL_TYPE2_8 "VtSig_VIS_TSR_SIGN_SUPPL_TYPE2_8";
BA_ "GenSigSendType" SG_ 1696 VIS_TSR_SIGN_SUPPL_TYPE2_8 1;
BA_ "GenSigVtEn" SG_ 1696 VIS_TSR_SIGN_SUPPL_TYPE1_8 "TRUE";
BA_ "GenSigVtName" SG_ 1696 VIS_TSR_SIGN_SUPPL_TYPE1_8 "VtSig_VIS_TSR_SIGN_SUPPL_TYPE1_8";
BA_ "GenSigSendType" SG_ 1696 VIS_TSR_SIGN_SUPPL_TYPE1_8 1;
BA_ "GenSigVtEn" SG_ 1696 VIS_TSR_SIGN_POSITION_8 "TRUE";
BA_ "GenSigVtName" SG_ 1696 VIS_TSR_SIGN_POSITION_8 "VtSig_VIS_TSR_SIGN_POSITION_8";
BA_ "GenSigSendType" SG_ 1696 VIS_TSR_SIGN_POSITION_8 1;
BA_ "GenSigVtEn" SG_ 1696 VIS_TSR_SIGN_LANE_8 "TRUE";
BA_ "GenSigVtName" SG_ 1696 VIS_TSR_SIGN_LANE_8 "VtSig_VIS_TSR_SIGN_LANE_8";
BA_ "GenSigSendType" SG_ 1696 VIS_TSR_SIGN_LANE_8 1;
BA_ "GenSigSendType" SG_ 1696 VIS_TSR_SIGN_ID_8 1;
BA_ "GenSigVtEn" SG_ 1696 VIS_TSR_SIGN_EMBEDDED_SCENE_8 "TRUE";
BA_ "GenSigVtName" SG_ 1696 VIS_TSR_SIGN_EMBEDDED_SCENE_8 "VtSig_VIS_TSR_SIGN_EMBEDDED_SCENE_8";
BA_ "GenSigSendType" SG_ 1696 VIS_TSR_SIGN_EMBEDDED_SCENE_8 1;
BA_ "GenSigVtEn" SG_ 1696 VIS_TSR_SCENE_STATUS_8 "TRUE";
BA_ "GenSigVtName" SG_ 1696 VIS_TSR_SCENE_STATUS_8 "VtSig_VIS_TSR_SCENE_STATUS_8";
BA_ "GenSigSendType" SG_ 1696 VIS_TSR_SCENE_STATUS_8 1;
BA_ "GenSigSendType" SG_ 1696 VIS_TSR_SCENE_ID_8 1;
BA_ "GenSigVtEn" SG_ 1695 VIS_TSR_SIGN_VARIABLE_7 "TRUE";
BA_ "GenSigVtName" SG_ 1695 VIS_TSR_SIGN_VARIABLE_7 "VtSig_VIS_TSR_SIGN_VARIABLE_7";
BA_ "GenSigSendType" SG_ 1695 VIS_TSR_SIGN_VARIABLE_7 1;
BA_ "GenSigSendType" SG_ 1695 VIS_TSR_SIGN_VALUE_7 1;
BA_ "GenSigVtEn" SG_ 1695 VIS_TSR_SIGN_TYPE_7 "TRUE";
BA_ "GenSigVtName" SG_ 1695 VIS_TSR_SIGN_TYPE_7 "VtSig_VIS_TSR_SIGN_TYPE_7";
BA_ "GenSigSendType" SG_ 1695 VIS_TSR_SIGN_TYPE_7 1;
BA_ "GenSigVtEn" SG_ 1695 VIS_TSR_SIGN_SUPPL_TYPE2_7 "TRUE";
BA_ "GenSigVtName" SG_ 1695 VIS_TSR_SIGN_SUPPL_TYPE2_7 "VtSig_VIS_TSR_SIGN_SUPPL_TYPE2_7";
BA_ "GenSigSendType" SG_ 1695 VIS_TSR_SIGN_SUPPL_TYPE2_7 1;
BA_ "GenSigVtEn" SG_ 1695 VIS_TSR_SIGN_SUPPL_TYPE1_7 "TRUE";
BA_ "GenSigVtName" SG_ 1695 VIS_TSR_SIGN_SUPPL_TYPE1_7 "VtSig_VIS_TSR_SIGN_SUPPL_TYPE1_7";
BA_ "GenSigSendType" SG_ 1695 VIS_TSR_SIGN_SUPPL_TYPE1_7 1;
BA_ "GenSigVtEn" SG_ 1695 VIS_TSR_SIGN_POSITION_7 "TRUE";
BA_ "GenSigVtName" SG_ 1695 VIS_TSR_SIGN_POSITION_7 "VtSig_VIS_TSR_SIGN_POSITION_7";
BA_ "GenSigSendType" SG_ 1695 VIS_TSR_SIGN_POSITION_7 1;
BA_ "GenSigVtEn" SG_ 1695 VIS_TSR_SIGN_LANE_7 "TRUE";
BA_ "GenSigVtName" SG_ 1695 VIS_TSR_SIGN_LANE_7 "VtSig_VIS_TSR_SIGN_LANE_7";
BA_ "GenSigSendType" SG_ 1695 VIS_TSR_SIGN_LANE_7 1;
BA_ "GenSigSendType" SG_ 1695 VIS_TSR_SIGN_ID_7 1;
BA_ "GenSigVtEn" SG_ 1695 VIS_TSR_SIGN_EMBEDDED_SCENE_7 "TRUE";
BA_ "GenSigVtName" SG_ 1695 VIS_TSR_SIGN_EMBEDDED_SCENE_7 "VtSig_VIS_TSR_SIGN_EMBEDDED_SCENE_7";
BA_ "GenSigSendType" SG_ 1695 VIS_TSR_SIGN_EMBEDDED_SCENE_7 1;
BA_ "GenSigVtEn" SG_ 1695 VIS_TSR_SCENE_STATUS_7 "TRUE";
BA_ "GenSigVtName" SG_ 1695 VIS_TSR_SCENE_STATUS_7 "VtSig_VIS_TSR_SCENE_STATUS_7";
BA_ "GenSigSendType" SG_ 1695 VIS_TSR_SCENE_STATUS_7 1;
BA_ "GenSigSendType" SG_ 1695 VIS_TSR_SCENE_ID_7 1;
BA_ "GenSigVtEn" SG_ 1694 VIS_TSR_SIGN_VARIABLE_6 "TRUE";
BA_ "GenSigVtName" SG_ 1694 VIS_TSR_SIGN_VARIABLE_6 "VtSig_VIS_TSR_SIGN_VARIABLE_6";
BA_ "GenSigSendType" SG_ 1694 VIS_TSR_SIGN_VARIABLE_6 1;
BA_ "GenSigSendType" SG_ 1694 VIS_TSR_SIGN_VALUE_6 1;
BA_ "GenSigVtEn" SG_ 1694 VIS_TSR_SIGN_TYPE_6 "TRUE";
BA_ "GenSigVtName" SG_ 1694 VIS_TSR_SIGN_TYPE_6 "VtSig_VIS_TSR_SIGN_TYPE_6";
BA_ "GenSigSendType" SG_ 1694 VIS_TSR_SIGN_TYPE_6 1;
BA_ "GenSigVtEn" SG_ 1694 VIS_TSR_SIGN_SUPPL_TYPE2_6 "TRUE";
BA_ "GenSigVtName" SG_ 1694 VIS_TSR_SIGN_SUPPL_TYPE2_6 "VtSig_VIS_TSR_SIGN_SUPPL_TYPE2_6";
BA_ "GenSigSendType" SG_ 1694 VIS_TSR_SIGN_SUPPL_TYPE2_6 1;
BA_ "GenSigVtEn" SG_ 1694 VIS_TSR_SIGN_SUPPL_TYPE1_6 "TRUE";
BA_ "GenSigVtName" SG_ 1694 VIS_TSR_SIGN_SUPPL_TYPE1_6 "VtSig_VIS_TSR_SIGN_SUPPL_TYPE1_6";
BA_ "GenSigSendType" SG_ 1694 VIS_TSR_SIGN_SUPPL_TYPE1_6 1;
BA_ "GenSigVtEn" SG_ 1694 VIS_TSR_SIGN_POSITION_6 "TRUE";
BA_ "GenSigVtName" SG_ 1694 VIS_TSR_SIGN_POSITION_6 "VtSig_VIS_TSR_SIGN_POSITION_6";
BA_ "GenSigSendType" SG_ 1694 VIS_TSR_SIGN_POSITION_6 1;
BA_ "GenSigVtEn" SG_ 1694 VIS_TSR_SIGN_LANE_6 "TRUE";
BA_ "GenSigVtName" SG_ 1694 VIS_TSR_SIGN_LANE_6 "VtSig_VIS_TSR_SIGN_LANE_6";
BA_ "GenSigSendType" SG_ 1694 VIS_TSR_SIGN_LANE_6 1;
BA_ "GenSigSendType" SG_ 1694 VIS_TSR_SIGN_ID_6 1;
BA_ "GenSigVtEn" SG_ 1694 VIS_TSR_SIGN_EMBEDDED_SCENE_6 "TRUE";
BA_ "GenSigVtName" SG_ 1694 VIS_TSR_SIGN_EMBEDDED_SCENE_6 "VtSig_VIS_TSR_SIGN_EMBEDDED_SCENE_6";
BA_ "GenSigSendType" SG_ 1694 VIS_TSR_SIGN_EMBEDDED_SCENE_6 1;
BA_ "GenSigVtEn" SG_ 1694 VIS_TSR_SCENE_STATUS_6 "TRUE";
BA_ "GenSigVtName" SG_ 1694 VIS_TSR_SCENE_STATUS_6 "VtSig_VIS_TSR_SCENE_STATUS_6";
BA_ "GenSigSendType" SG_ 1694 VIS_TSR_SCENE_STATUS_6 1;
BA_ "GenSigSendType" SG_ 1694 VIS_TSR_SCENE_ID_6 1;
BA_ "GenSigVtEn" SG_ 1693 VIS_TSR_SIGN_VARIABLE_5 "TRUE";
BA_ "GenSigVtName" SG_ 1693 VIS_TSR_SIGN_VARIABLE_5 "VtSig_VIS_TSR_SIGN_VARIABLE_5";
BA_ "GenSigSendType" SG_ 1693 VIS_TSR_SIGN_VARIABLE_5 1;
BA_ "GenSigSendType" SG_ 1693 VIS_TSR_SIGN_VALUE_5 1;
BA_ "GenSigVtEn" SG_ 1693 VIS_TSR_SIGN_TYPE_5 "TRUE";
BA_ "GenSigVtName" SG_ 1693 VIS_TSR_SIGN_TYPE_5 "VtSig_VIS_TSR_SIGN_TYPE_5";
BA_ "GenSigSendType" SG_ 1693 VIS_TSR_SIGN_TYPE_5 1;
BA_ "GenSigVtEn" SG_ 1693 VIS_TSR_SIGN_SUPPL_TYPE2_5 "TRUE";
BA_ "GenSigVtName" SG_ 1693 VIS_TSR_SIGN_SUPPL_TYPE2_5 "VtSig_VIS_TSR_SIGN_SUPPL_TYPE2_5";
BA_ "GenSigSendType" SG_ 1693 VIS_TSR_SIGN_SUPPL_TYPE2_5 1;
BA_ "GenSigVtEn" SG_ 1693 VIS_TSR_SIGN_SUPPL_TYPE1_5 "TRUE";
BA_ "GenSigVtName" SG_ 1693 VIS_TSR_SIGN_SUPPL_TYPE1_5 "VtSig_VIS_TSR_SIGN_SUPPL_TYPE1_5";
BA_ "GenSigSendType" SG_ 1693 VIS_TSR_SIGN_SUPPL_TYPE1_5 1;
BA_ "GenSigVtEn" SG_ 1693 VIS_TSR_SIGN_POSITION_5 "TRUE";
BA_ "GenSigVtName" SG_ 1693 VIS_TSR_SIGN_POSITION_5 "VtSig_VIS_TSR_SIGN_POSITION_5";
BA_ "GenSigSendType" SG_ 1693 VIS_TSR_SIGN_POSITION_5 1;
BA_ "GenSigVtEn" SG_ 1693 VIS_TSR_SIGN_LANE_5 "TRUE";
BA_ "GenSigVtName" SG_ 1693 VIS_TSR_SIGN_LANE_5 "VtSig_VIS_TSR_SIGN_LANE_5";
BA_ "GenSigSendType" SG_ 1693 VIS_TSR_SIGN_LANE_5 1;
BA_ "GenSigSendType" SG_ 1693 VIS_TSR_SIGN_ID_5 1;
BA_ "GenSigVtEn" SG_ 1693 VIS_TSR_SIGN_EMBEDDED_SCENE_5 "TRUE";
BA_ "GenSigVtName" SG_ 1693 VIS_TSR_SIGN_EMBEDDED_SCENE_5 "VtSig_VIS_TSR_SIGN_EMBEDDED_SCENE_5";
BA_ "GenSigSendType" SG_ 1693 VIS_TSR_SIGN_EMBEDDED_SCENE_5 1;
BA_ "GenSigVtEn" SG_ 1693 VIS_TSR_SCENE_STATUS_5 "TRUE";
BA_ "GenSigVtName" SG_ 1693 VIS_TSR_SCENE_STATUS_5 "VtSig_VIS_TSR_SCENE_STATUS_5";
BA_ "GenSigSendType" SG_ 1693 VIS_TSR_SCENE_STATUS_5 1;
BA_ "GenSigSendType" SG_ 1693 VIS_TSR_SCENE_ID_5 1;
BA_ "GenSigVtEn" SG_ 1692 VIS_TSR_SIGN_VARIABLE_4 "TRUE";
BA_ "GenSigVtName" SG_ 1692 VIS_TSR_SIGN_VARIABLE_4 "VtSig_VIS_TSR_SIGN_VARIABLE_4";
BA_ "GenSigSendType" SG_ 1692 VIS_TSR_SIGN_VARIABLE_4 1;
BA_ "GenSigSendType" SG_ 1692 VIS_TSR_SIGN_VALUE_4 1;
BA_ "GenSigVtEn" SG_ 1692 VIS_TSR_SIGN_TYPE_4 "TRUE";
BA_ "GenSigVtName" SG_ 1692 VIS_TSR_SIGN_TYPE_4 "VtSig_VIS_TSR_SIGN_TYPE_4";
BA_ "GenSigSendType" SG_ 1692 VIS_TSR_SIGN_TYPE_4 1;
BA_ "GenSigVtEn" SG_ 1692 VIS_TSR_SIGN_SUPPL_TYPE2_4 "TRUE";
BA_ "GenSigVtName" SG_ 1692 VIS_TSR_SIGN_SUPPL_TYPE2_4 "VtSig_VIS_TSR_SIGN_SUPPL_TYPE2_4";
BA_ "GenSigSendType" SG_ 1692 VIS_TSR_SIGN_SUPPL_TYPE2_4 1;
BA_ "GenSigVtEn" SG_ 1692 VIS_TSR_SIGN_SUPPL_TYPE1_4 "TRUE";
BA_ "GenSigVtName" SG_ 1692 VIS_TSR_SIGN_SUPPL_TYPE1_4 "VtSig_VIS_TSR_SIGN_SUPPL_TYPE1_4";
BA_ "GenSigSendType" SG_ 1692 VIS_TSR_SIGN_SUPPL_TYPE1_4 1;
BA_ "GenSigVtEn" SG_ 1692 VIS_TSR_SIGN_POSITION_4 "TRUE";
BA_ "GenSigVtName" SG_ 1692 VIS_TSR_SIGN_POSITION_4 "VtSig_VIS_TSR_SIGN_POSITION_4";
BA_ "GenSigSendType" SG_ 1692 VIS_TSR_SIGN_POSITION_4 1;
BA_ "GenSigVtEn" SG_ 1692 VIS_TSR_SIGN_LANE_4 "TRUE";
BA_ "GenSigVtName" SG_ 1692 VIS_TSR_SIGN_LANE_4 "VtSig_VIS_TSR_SIGN_LANE_4";
BA_ "GenSigSendType" SG_ 1692 VIS_TSR_SIGN_LANE_4 1;
BA_ "GenSigSendType" SG_ 1692 VIS_TSR_SIGN_ID_4 1;
BA_ "GenSigVtEn" SG_ 1692 VIS_TSR_SIGN_EMBEDDED_SCENE_4 "TRUE";
BA_ "GenSigVtName" SG_ 1692 VIS_TSR_SIGN_EMBEDDED_SCENE_4 "VtSig_VIS_TSR_SIGN_EMBEDDED_SCENE_4";
BA_ "GenSigSendType" SG_ 1692 VIS_TSR_SIGN_EMBEDDED_SCENE_4 1;
BA_ "GenSigVtEn" SG_ 1692 VIS_TSR_SCENE_STATUS_4 "TRUE";
BA_ "GenSigVtName" SG_ 1692 VIS_TSR_SCENE_STATUS_4 "VtSig_VIS_TSR_SCENE_STATUS_4";
BA_ "GenSigSendType" SG_ 1692 VIS_TSR_SCENE_STATUS_4 1;
BA_ "GenSigSendType" SG_ 1692 VIS_TSR_SCENE_ID_4 1;
BA_ "GenSigVtEn" SG_ 1691 VIS_TSR_SIGN_VARIABLE_3 "TRUE";
BA_ "GenSigVtName" SG_ 1691 VIS_TSR_SIGN_VARIABLE_3 "VtSig_VIS_TSR_SIGN_VARIABLE_3";
BA_ "GenSigSendType" SG_ 1691 VIS_TSR_SIGN_VARIABLE_3 1;
BA_ "GenSigSendType" SG_ 1691 VIS_TSR_SIGN_VALUE_3 1;
BA_ "GenSigVtEn" SG_ 1691 VIS_TSR_SIGN_TYPE_3 "TRUE";
BA_ "GenSigVtName" SG_ 1691 VIS_TSR_SIGN_TYPE_3 "VtSig_VIS_TSR_SIGN_TYPE_3";
BA_ "GenSigSendType" SG_ 1691 VIS_TSR_SIGN_TYPE_3 1;
BA_ "GenSigVtEn" SG_ 1691 VIS_TSR_SIGN_SUPPL_TYPE2_3 "TRUE";
BA_ "GenSigVtName" SG_ 1691 VIS_TSR_SIGN_SUPPL_TYPE2_3 "VtSig_VIS_TSR_SIGN_SUPPL_TYPE2_3";
BA_ "GenSigSendType" SG_ 1691 VIS_TSR_SIGN_SUPPL_TYPE2_3 1;
BA_ "GenSigVtEn" SG_ 1691 VIS_TSR_SIGN_SUPPL_TYPE1_3 "TRUE";
BA_ "GenSigVtName" SG_ 1691 VIS_TSR_SIGN_SUPPL_TYPE1_3 "VtSig_VIS_TSR_SIGN_SUPPL_TYPE1_3";
BA_ "GenSigSendType" SG_ 1691 VIS_TSR_SIGN_SUPPL_TYPE1_3 1;
BA_ "GenSigVtEn" SG_ 1691 VIS_TSR_SIGN_POSITION_3 "TRUE";
BA_ "GenSigVtName" SG_ 1691 VIS_TSR_SIGN_POSITION_3 "VtSig_VIS_TSR_SIGN_POSITION_3";
BA_ "GenSigSendType" SG_ 1691 VIS_TSR_SIGN_POSITION_3 1;
BA_ "GenSigVtEn" SG_ 1691 VIS_TSR_SIGN_LANE_3 "TRUE";
BA_ "GenSigVtName" SG_ 1691 VIS_TSR_SIGN_LANE_3 "VtSig_VIS_TSR_SIGN_LANE_3";
BA_ "GenSigSendType" SG_ 1691 VIS_TSR_SIGN_LANE_3 1;
BA_ "GenSigSendType" SG_ 1691 VIS_TSR_SIGN_ID_3 1;
BA_ "GenSigVtEn" SG_ 1691 VIS_TSR_SIGN_EMBEDDED_SCENE_3 "TRUE";
BA_ "GenSigVtName" SG_ 1691 VIS_TSR_SIGN_EMBEDDED_SCENE_3 "VtSig_VIS_TSR_SIGN_EMBEDDED_SCENE_3";
BA_ "GenSigSendType" SG_ 1691 VIS_TSR_SIGN_EMBEDDED_SCENE_3 1;
BA_ "GenSigVtEn" SG_ 1691 VIS_TSR_SCENE_STATUS_3 "TRUE";
BA_ "GenSigVtName" SG_ 1691 VIS_TSR_SCENE_STATUS_3 "VtSig_VIS_TSR_SCENE_STATUS_3";
BA_ "GenSigSendType" SG_ 1691 VIS_TSR_SCENE_STATUS_3 1;
BA_ "GenSigSendType" SG_ 1691 VIS_TSR_SCENE_ID_3 1;
BA_ "GenSigVtEn" SG_ 1690 VIS_TSR_SIGN_VARIABLE_2 "TRUE";
BA_ "GenSigVtName" SG_ 1690 VIS_TSR_SIGN_VARIABLE_2 "VtSig_VIS_TSR_SIGN_VARIABLE_2";
BA_ "GenSigSendType" SG_ 1690 VIS_TSR_SIGN_VARIABLE_2 1;
BA_ "GenSigSendType" SG_ 1690 VIS_TSR_SIGN_VALUE_2 1;
BA_ "GenSigVtEn" SG_ 1690 VIS_TSR_SIGN_TYPE_2 "TRUE";
BA_ "GenSigVtName" SG_ 1690 VIS_TSR_SIGN_TYPE_2 "VtSig_VIS_TSR_SIGN_TYPE_2";
BA_ "GenSigSendType" SG_ 1690 VIS_TSR_SIGN_TYPE_2 1;
BA_ "GenSigVtEn" SG_ 1690 VIS_TSR_SIGN_SUPPL_TYPE2_2 "TRUE";
BA_ "GenSigVtName" SG_ 1690 VIS_TSR_SIGN_SUPPL_TYPE2_2 "VtSig_VIS_TSR_SIGN_SUPPL_TYPE2_2";
BA_ "GenSigSendType" SG_ 1690 VIS_TSR_SIGN_SUPPL_TYPE2_2 1;
BA_ "GenSigVtEn" SG_ 1690 VIS_TSR_SIGN_SUPPL_TYPE1_2 "TRUE";
BA_ "GenSigVtName" SG_ 1690 VIS_TSR_SIGN_SUPPL_TYPE1_2 "VtSig_VIS_TSR_SIGN_SUPPL_TYPE1_2";
BA_ "GenSigSendType" SG_ 1690 VIS_TSR_SIGN_SUPPL_TYPE1_2 1;
BA_ "GenSigVtEn" SG_ 1690 VIS_TSR_SIGN_POSITION_2 "TRUE";
BA_ "GenSigVtName" SG_ 1690 VIS_TSR_SIGN_POSITION_2 "VtSig_VIS_TSR_SIGN_POSITION_2";
BA_ "GenSigSendType" SG_ 1690 VIS_TSR_SIGN_POSITION_2 1;
BA_ "GenSigVtEn" SG_ 1690 VIS_TSR_SIGN_LANE_2 "TRUE";
BA_ "GenSigVtName" SG_ 1690 VIS_TSR_SIGN_LANE_2 "VtSig_VIS_TSR_SIGN_LANE_2";
BA_ "GenSigSendType" SG_ 1690 VIS_TSR_SIGN_LANE_2 1;
BA_ "GenSigSendType" SG_ 1690 VIS_TSR_SIGN_ID_2 1;
BA_ "GenSigVtEn" SG_ 1690 VIS_TSR_SIGN_EMBEDDED_SCENE_2 "TRUE";
BA_ "GenSigVtName" SG_ 1690 VIS_TSR_SIGN_EMBEDDED_SCENE_2 "VtSig_VIS_TSR_SIGN_EMBEDDED_SCENE_2";
BA_ "GenSigSendType" SG_ 1690 VIS_TSR_SIGN_EMBEDDED_SCENE_2 1;
BA_ "GenSigVtEn" SG_ 1690 VIS_TSR_SCENE_STATUS_2 "TRUE";
BA_ "GenSigVtName" SG_ 1690 VIS_TSR_SCENE_STATUS_2 "VtSig_VIS_TSR_SCENE_STATUS_2";
BA_ "GenSigSendType" SG_ 1690 VIS_TSR_SCENE_STATUS_2 1;
BA_ "GenSigSendType" SG_ 1690 VIS_TSR_SCENE_ID_2 1;
BA_ "GenSigSendType" SG_ 1895 RT2C_Width 1;
BA_ "GenSigSendType" SG_ 1895 RT2C_visTrkID 1;
BA_ "GenSigSendType" SG_ 1895 RT2C_MessageCounter 1;
BA_ "GenSigSendType" SG_ 1895 RT2C_MC_stage_age 1;
BA_ "GenSigSendType" SG_ 1895 RT2C_MC_positionConfidence 1;
BA_ "GenSigSendType" SG_ 1895 RT2C_MC_object_class 1;
BA_ "GenSigSendType" SG_ 1895 RT2C_MC_Age 1;
BA_ "GenSigSendType" SG_ 1895 RT2C_LEFTcorner_long 1;
BA_ "GenSigSendType" SG_ 1895 RT2C_FARLeftRight 1;
BA_ "GenSigSendType" SG_ 1893 RT2A_V_long_obj 1;
BA_ "GenSigSendType" SG_ 1893 RT2A_V_lat_obj 1;
BA_ "GenSigSendType" SG_ 1893 RT2A_MessageCounter 1;
BA_ "GenSigSendType" SG_ 1893 RT2A_L_long_rel 1;
BA_ "GenSigSendType" SG_ 1893 RT2A_L_lat_rel 1;
BA_ "GenSigSendType" SG_ 1893 RT2A_DetectionSensor 1;
BA_ "GenSigSendType" SG_ 1893 RT2A_A_long_obj 1;
BA_ "GenSigSendType" SG_ 1891 RT1D_RIGHTcorner_long 1;
BA_ "GenSigSendType" SG_ 1891 RT1D_RIGHTcorner_lat 1;
BA_ "GenSigSendType" SG_ 1891 RT1D_MessageCounter 1;
BA_ "GenSigSendType" SG_ 1891 RT1D_LEFTcorner_lat 1;
BA_ "GenSigSendType" SG_ 1891 RT1D_FARcorner_long 1;
BA_ "GenSigSendType" SG_ 1891 RT1D_FARcorner_lat 1;
BA_ "GenSigSendType" SG_ 1890 RT1C_Width 1;
BA_ "GenSigSendType" SG_ 1890 RT1C_visTrkID 1;
BA_ "GenSigSendType" SG_ 1890 RT1C_MessageCounter 1;
BA_ "GenSigSendType" SG_ 1890 RT1C_MC_stage_age 1;
BA_ "GenSigSendType" SG_ 1890 RT1C_MC_positionConfidence 1;
BA_ "GenSigSendType" SG_ 1890 RT1C_MC_object_class 1;
BA_ "GenSigSendType" SG_ 1890 RT1C_MC_Age 1;
BA_ "GenSigSendType" SG_ 1890 RT1C_LEFTcorner_long 1;
BA_ "GenSigSendType" SG_ 1890 RT1C_FARLeftRight 1;
BA_ "GenSigSendType" SG_ 1027 P1C_visTrkID 1;
BA_ "GenSigSendType" SG_ 1027 P1C_Stage_age 1;
BA_ "GenSigVtEn" SG_ 1027 P1C_Object_class "TRUE";
BA_ "GenSigVtName" SG_ 1027 P1C_Object_class "VtSig_P1C_Object_class";
BA_ "GenSigSendType" SG_ 1027 P1C_Object_class 1;
BA_ "GenSigSendType" SG_ 1025 P1A_V_long_obj 1;
BA_ "GenSigSendType" SG_ 1025 P1A_TrackID 1;
BA_ "GenSigSendType" SG_ 1025 P1A_L_long_rel 1;
BA_ "GenSigSendType" SG_ 1025 P1A_L_lat_rel 1;
BA_ "GenSigSendType" SG_ 1025 P1A_A_long_obj 1;
BA_ "GenSigSendType" SG_ 258 PredictedPath_MessageCounter 1;
BA_ "GenSigSendType" SG_ 258 Predicted_Path_Coef_C0 1;
BA_ "GenSigSendType" SG_ 258 Predicted_Path_Coef_C1 1;
BA_ "GenSigSendType" SG_ 258 Predicted_Path_Coef_HeadingAngle 1;
BA_ "GenSigSendType" SG_ 258 Predicted_Path_Coef_Offset 1;
BA_ "GenSigSendType" SG_ 258 Predicted_Path_Confidence 1;
BA_ "GenSigSendType" SG_ 258 Predicted_Path_Valid_Length 1;
BA_ "GenSigSendType" SG_ 1888 RT1A_A_long_obj 1;
BA_ "GenSigVtEn" SG_ 1888 RT1A_DetectionSensor "TRUE";
BA_ "GenSigVtName" SG_ 1888 RT1A_DetectionSensor "VtSig_RT1A_DetectionSensor";
BA_ "GenSigSendType" SG_ 1888 RT1A_DetectionSensor 1;
BA_ "GenSigSendType" SG_ 1888 RT1A_L_lat_rel 1;
BA_ "GenSigSendType" SG_ 1888 RT1A_L_long_rel 1;
BA_ "GenSigSendType" SG_ 1888 RT1A_MessageCounter 1;
BA_ "GenSigSendType" SG_ 1888 RT1A_V_lat_obj 1;
BA_ "GenSigSendType" SG_ 1888 RT1A_V_long_obj 1;
BA_ "GenSigSendType" SG_ 1889 RT1B_A_lat_obj 1;
BA_ "GenSigSendType" SG_ 1889 RT1B_MessageCounter 1;
BA_ "GenSigSendType" SG_ 1889 RT1B_Movement 1;
BA_ "GenSigVtEn" SG_ 1889 RT1B_Status "TRUE";
BA_ "GenSigVtName" SG_ 1889 RT1B_Status "VtSig_RT1B_Status";
BA_ "GenSigSendType" SG_ 1889 RT1B_Status 1;
BA_ "GenSigSendType" SG_ 1889 RT1B_TrackID 1;
BA_ "GenSigSendType" SG_ 1889 RT1B_XOHP_ETSEL_CMbB_FCW 1;
BA_ "GenSigSendType" SG_ 1889 RT1B_XOLC_ETSEL_CMbB_FCW 1;
BA_ "GenSigSendType" SG_ 1894 RT2B_A_lat_obj 1;
BA_ "GenSigSendType" SG_ 1894 RT2B_MessageCounter 1;
BA_ "GenSigSendType" SG_ 1894 RT2B_Movement 1;
BA_ "GenSigVtEn" SG_ 1894 RT2B_Status "TRUE";
BA_ "GenSigVtName" SG_ 1894 RT2B_Status "VtSig_RT2B_Status";
BA_ "GenSigSendType" SG_ 1894 RT2B_Status 1;
BA_ "GenSigSendType" SG_ 1894 RT2B_TrackID 1;
BA_ "GenSigSendType" SG_ 1894 RT2B_XOHP_ETSEL_CMbB_FCW 1;
BA_ "GenSigSendType" SG_ 1894 RT2B_XOLC_ETSEL_CMbB_FCW 1;
BA_ "GenSigSendType" SG_ 1896 RT2D_FARcorner_lat 1;
BA_ "GenSigSendType" SG_ 1896 RT2D_FARcorner_long 1;
BA_ "GenSigSendType" SG_ 1896 RT2D_LEFTcorner_lat 1;
BA_ "GenSigSendType" SG_ 1896 RT2D_MessageCounter 1;
BA_ "GenSigSendType" SG_ 1896 RT2D_RIGHTcorner_lat 1;
BA_ "GenSigSendType" SG_ 1896 RT2D_RIGHTcorner_long 1;
BA_ "GenSigSendType" SG_ 1898 RT3A_A_long_obj 1;
BA_ "GenSigVtEn" SG_ 1898 RT3A_DetectionSensor "TRUE";
BA_ "GenSigVtName" SG_ 1898 RT3A_DetectionSensor "VtSig_RT3A_DetectionSensor";
BA_ "GenSigSendType" SG_ 1898 RT3A_DetectionSensor 1;
BA_ "GenSigSendType" SG_ 1898 RT3A_L_lat_rel 1;
BA_ "GenSigSendType" SG_ 1898 RT3A_L_long_rel 1;
BA_ "GenSigSendType" SG_ 1898 RT3A_MessageCounter 1;
BA_ "GenSigSendType" SG_ 1898 RT3A_V_lat_obj 1;
BA_ "GenSigSendType" SG_ 1898 RT3A_V_long_obj 1;
BA_ "GenSigSendType" SG_ 1899 RT3B_A_lat_obj 1;
BA_ "GenSigSendType" SG_ 1899 RT3B_MessageCounter 1;
BA_ "GenSigSendType" SG_ 1899 RT3B_Movement 1;
BA_ "GenSigVtEn" SG_ 1899 RT3B_Status "TRUE";
BA_ "GenSigVtName" SG_ 1899 RT3B_Status "VtSig_RT3B_Status";
BA_ "GenSigSendType" SG_ 1899 RT3B_Status 1;
BA_ "GenSigSendType" SG_ 1899 RT3B_TrackID 1;
BA_ "GenSigSendType" SG_ 1899 RT3B_XOHP_ETSEL_CMbB_FCW 1;
BA_ "GenSigSendType" SG_ 1899 RT3B_XOLC_ETSEL_CMbB_FCW 1;
BA_ "GenSigSendType" SG_ 1900 RT3C_FARLeftRight 1;
BA_ "GenSigSendType" SG_ 1900 RT3C_LEFTcorner_long 1;
BA_ "GenSigSendType" SG_ 1900 RT3C_MC_Age 1;
BA_ "GenSigVtEn" SG_ 1900 RT3C_MC_object_class "TRUE";
BA_ "GenSigVtName" SG_ 1900 RT3C_MC_object_class "VtSig_RT3C_MC_object_class";
BA_ "GenSigSendType" SG_ 1900 RT3C_MC_object_class 1;
BA_ "GenSigSendType" SG_ 1900 RT3C_MC_positionConfidence 1;
BA_ "GenSigSendType" SG_ 1900 RT3C_MC_stage_age 1;
BA_ "GenSigSendType" SG_ 1900 RT3C_MessageCounter 1;
BA_ "GenSigSendType" SG_ 1900 RT3C_visTrkID 1;
BA_ "GenSigSendType" SG_ 1900 RT3C_Width 1;
BA_ "GenSigSendType" SG_ 1901 RT3D_FARcorner_lat 1;
BA_ "GenSigSendType" SG_ 1901 RT3D_FARcorner_long 1;
BA_ "GenSigSendType" SG_ 1901 RT3D_LEFTcorner_lat 1;
BA_ "GenSigSendType" SG_ 1901 RT3D_MessageCounter 1;
BA_ "GenSigSendType" SG_ 1901 RT3D_RIGHTcorner_lat 1;
BA_ "GenSigSendType" SG_ 1901 RT3D_RIGHTcorner_long 1;
BA_ "GenSigSendType" SG_ 1903 RT4A_A_long_obj 1;
BA_ "GenSigVtEn" SG_ 1903 RT4A_DetectionSensor "TRUE";
BA_ "GenSigVtName" SG_ 1903 RT4A_DetectionSensor "VtSig_RT4A_DetectionSensor";
BA_ "GenSigSendType" SG_ 1903 RT4A_DetectionSensor 1;
BA_ "GenSigSendType" SG_ 1903 RT4A_L_lat_rel 1;
BA_ "GenSigSendType" SG_ 1903 RT4A_L_long_rel 1;
BA_ "GenSigSendType" SG_ 1903 RT4A_MessageCounter 1;
BA_ "GenSigSendType" SG_ 1903 RT4A_V_lat_obj 1;
BA_ "GenSigSendType" SG_ 1903 RT4A_V_long_obj 1;
BA_ "GenSigSendType" SG_ 1904 RT4B_A_lat_obj 1;
BA_ "GenSigSendType" SG_ 1904 RT4B_MessageCounter 1;
BA_ "GenSigSendType" SG_ 1904 RT4B_Movement 1;
BA_ "GenSigVtEn" SG_ 1904 RT4B_Status "TRUE";
BA_ "GenSigVtName" SG_ 1904 RT4B_Status "VtSig_RT4B_Status";
BA_ "GenSigSendType" SG_ 1904 RT4B_Status 1;
BA_ "GenSigSendType" SG_ 1904 RT4B_TrackID 1;
BA_ "GenSigSendType" SG_ 1904 RT4B_XOHP_ETSEL_CMbB_FCW 1;
BA_ "GenSigSendType" SG_ 1904 RT4B_XOLC_ETSEL_CMbB_FCW 1;
BA_ "GenSigSendType" SG_ 1905 RT4C_FARLeftRight 1;
BA_ "GenSigSendType" SG_ 1905 RT4C_LEFTcorner_long 1;
BA_ "GenSigSendType" SG_ 1905 RT4C_MC_Age 1;
BA_ "GenSigVtEn" SG_ 1905 RT4C_MC_object_class "TRUE";
BA_ "GenSigVtName" SG_ 1905 RT4C_MC_object_class "VtSig_RT4C_MC_object_class";
BA_ "GenSigSendType" SG_ 1905 RT4C_MC_object_class 1;
BA_ "GenSigSendType" SG_ 1905 RT4C_MC_positionConfidence 1;
BA_ "GenSigSendType" SG_ 1905 RT4C_MC_stage_age 1;
BA_ "GenSigSendType" SG_ 1905 RT4C_MessageCounter 1;
BA_ "GenSigSendType" SG_ 1905 RT4C_visTrkID 1;
BA_ "GenSigSendType" SG_ 1905 RT4C_Width 1;
BA_ "GenSigSendType" SG_ 1906 RT4D_FARcorner_lat 1;
BA_ "GenSigSendType" SG_ 1906 RT4D_FARcorner_long 1;
BA_ "GenSigSendType" SG_ 1906 RT4D_LEFTcorner_lat 1;
BA_ "GenSigSendType" SG_ 1906 RT4D_MessageCounter 1;
BA_ "GenSigSendType" SG_ 1906 RT4D_RIGHTcorner_lat 1;
BA_ "GenSigSendType" SG_ 1906 RT4D_RIGHTcorner_long 1;
BA_ "GenSigSendType" SG_ 1908 RT5A_A_long_obj 1;
BA_ "GenSigVtEn" SG_ 1908 RT5A_DetectionSensor "TRUE";
BA_ "GenSigVtName" SG_ 1908 RT5A_DetectionSensor "VtSig_RT5A_DetectionSensor";
BA_ "GenSigSendType" SG_ 1908 RT5A_DetectionSensor 1;
BA_ "GenSigSendType" SG_ 1908 RT5A_L_lat_rel 1;
BA_ "GenSigSendType" SG_ 1908 RT5A_L_long_rel 1;
BA_ "GenSigSendType" SG_ 1908 RT5A_MessageCounter 1;
BA_ "GenSigSendType" SG_ 1908 RT5A_V_lat_obj 1;
BA_ "GenSigSendType" SG_ 1908 RT5A_V_long_obj 1;
BA_ "GenSigSendType" SG_ 1909 RT5B_A_lat_obj 1;
BA_ "GenSigSendType" SG_ 1909 RT5B_MessageCounter 1;
BA_ "GenSigSendType" SG_ 1909 RT5B_Movement 1;
BA_ "GenSigVtEn" SG_ 1909 RT5B_Status "TRUE";
BA_ "GenSigVtName" SG_ 1909 RT5B_Status "VtSig_RT5B_Status";
BA_ "GenSigSendType" SG_ 1909 RT5B_Status 1;
BA_ "GenSigSendType" SG_ 1909 RT5B_TrackID 1;
BA_ "GenSigSendType" SG_ 1909 RT5B_XOHP_ETSEL_CMbB_FCW 1;
BA_ "GenSigSendType" SG_ 1909 RT5B_XOLC_ETSEL_CMbB_FCW 1;
BA_ "GenSigSendType" SG_ 1910 RT5C_FARLeftRight 1;
BA_ "GenSigSendType" SG_ 1910 RT5C_LEFTcorner_long 1;
BA_ "GenSigSendType" SG_ 1910 RT5C_MC_Age 1;
BA_ "GenSigVtEn" SG_ 1910 RT5C_MC_object_class "TRUE";
BA_ "GenSigVtName" SG_ 1910 RT5C_MC_object_class "VtSig_RT5C_MC_object_class";
BA_ "GenSigSendType" SG_ 1910 RT5C_MC_object_class 1;
BA_ "GenSigSendType" SG_ 1910 RT5C_MC_positionConfidence 1;
BA_ "GenSigSendType" SG_ 1910 RT5C_MC_stage_age 1;
BA_ "GenSigSendType" SG_ 1910 RT5C_MessageCounter 1;
BA_ "GenSigSendType" SG_ 1910 RT5C_visTrkID 1;
BA_ "GenSigSendType" SG_ 1910 RT5C_Width 1;
BA_ "GenSigSendType" SG_ 1911 RT5D_FARcorner_lat 1;
BA_ "GenSigSendType" SG_ 1911 RT5D_FARcorner_long 1;
BA_ "GenSigSendType" SG_ 1911 RT5D_LEFTcorner_lat 1;
BA_ "GenSigSendType" SG_ 1911 RT5D_MessageCounter 1;
BA_ "GenSigSendType" SG_ 1911 RT5D_RIGHTcorner_lat 1;
BA_ "GenSigSendType" SG_ 1911 RT5D_RIGHTcorner_long 1;
BA_ "GenSigSendType" SG_ 1913 RT6A_A_long_obj 1;
BA_ "GenSigVtEn" SG_ 1913 RT6A_DetectionSensor "TRUE";
BA_ "GenSigVtName" SG_ 1913 RT6A_DetectionSensor "VtSig_RT6A_DetectionSensor";
BA_ "GenSigSendType" SG_ 1913 RT6A_DetectionSensor 1;
BA_ "GenSigSendType" SG_ 1913 RT6A_L_lat_rel 1;
BA_ "GenSigSendType" SG_ 1913 RT6A_L_long_rel 1;
BA_ "GenSigSendType" SG_ 1913 RT6A_MessageCounter 1;
BA_ "GenSigSendType" SG_ 1913 RT6A_V_lat_obj 1;
BA_ "GenSigSendType" SG_ 1913 RT6A_V_long_obj 1;
BA_ "GenSigSendType" SG_ 1914 RT6B_A_lat_obj 1;
BA_ "GenSigSendType" SG_ 1914 RT6B_MessageCounter 1;
BA_ "GenSigSendType" SG_ 1914 RT6B_Movement 1;
BA_ "GenSigVtEn" SG_ 1914 RT6B_Status "TRUE";
BA_ "GenSigVtName" SG_ 1914 RT6B_Status "VtSig_RT6B_Status";
BA_ "GenSigSendType" SG_ 1914 RT6B_Status 1;
BA_ "GenSigSendType" SG_ 1914 RT6B_TrackID 1;
BA_ "GenSigSendType" SG_ 1914 RT6B_XOHP_ETSEL_CMbB_FCW 1;
BA_ "GenSigSendType" SG_ 1914 RT6B_XOLC_ETSEL_CMbB_FCW 1;
BA_ "GenSigSendType" SG_ 1915 RT6C_FARLeftRight 1;
BA_ "GenSigSendType" SG_ 1915 RT6C_LEFTcorner_long 1;
BA_ "GenSigSendType" SG_ 1915 RT6C_MC_Age 1;
BA_ "GenSigVtEn" SG_ 1915 RT6C_MC_object_class "TRUE";
BA_ "GenSigVtName" SG_ 1915 RT6C_MC_object_class "VtSig_RT6C_MC_object_class";
BA_ "GenSigSendType" SG_ 1915 RT6C_MC_object_class 1;
BA_ "GenSigSendType" SG_ 1915 RT6C_MC_positionConfidence 1;
BA_ "GenSigSendType" SG_ 1915 RT6C_MC_stage_age 1;
BA_ "GenSigSendType" SG_ 1915 RT6C_MessageCounter 1;
BA_ "GenSigSendType" SG_ 1915 RT6C_visTrkID 1;
BA_ "GenSigSendType" SG_ 1915 RT6C_Width 1;
BA_ "GenSigSendType" SG_ 1916 RT6D_FARcorner_lat 1;
BA_ "GenSigSendType" SG_ 1916 RT6D_FARcorner_long 1;
BA_ "GenSigSendType" SG_ 1916 RT6D_LEFTcorner_lat 1;
BA_ "GenSigSendType" SG_ 1916 RT6D_MessageCounter 1;
BA_ "GenSigSendType" SG_ 1916 RT6D_RIGHTcorner_lat 1;
BA_ "GenSigSendType" SG_ 1916 RT6D_RIGHTcorner_long 1;
BA_ "GenSigSendType" SG_ 1856 RTS1A_A_long_obj 1;
BA_ "GenSigVtEn" SG_ 1856 RTS1A_DetectionSensor "TRUE";
BA_ "GenSigVtName" SG_ 1856 RTS1A_DetectionSensor "VtSig_RTS1A_DetectionSensor";
BA_ "GenSigSendType" SG_ 1856 RTS1A_DetectionSensor 1;
BA_ "GenSigSendType" SG_ 1856 RTS1A_L_lat_rel 1;
BA_ "GenSigSendType" SG_ 1856 RTS1A_L_long_rel 1;
BA_ "GenSigSendType" SG_ 1856 RTS1A_MessageCounter 1;
BA_ "GenSigVtEn" SG_ 1856 RTS1A_Status "TRUE";
BA_ "GenSigVtName" SG_ 1856 RTS1A_Status "VtSig_RTS1A_Status";
BA_ "GenSigSendType" SG_ 1856 RTS1A_Status 1;
BA_ "GenSigSendType" SG_ 1856 RTS1A_TrackID 1;
BA_ "GenSigSendType" SG_ 1857 RTS1B_A_lat_obj 1;
BA_ "GenSigSendType" SG_ 1857 RTS1B_MessageCounter 1;
BA_ "GenSigSendType" SG_ 1857 RTS1B_Movement 1;
BA_ "GenSigSendType" SG_ 1857 RTS1B_V_lat_obj 1;
BA_ "GenSigSendType" SG_ 1857 RTS1B_V_long_obj 1;
BA_ "GenSigSendType" SG_ 1857 RTS1B_XOHP_ETSEL_CMbB_FCW 1;
BA_ "GenSigSendType" SG_ 1857 RTS1B_XOLC_ETSEL_CMbB_FCW 1;
BA_ "GenSigSendType" SG_ 1858 RTS1C_FARLeftRight 1;
BA_ "GenSigSendType" SG_ 1858 RTS1C_LEFTcorner_long 1;
BA_ "GenSigSendType" SG_ 1858 RTS1C_MC_Age 1;
BA_ "GenSigVtEn" SG_ 1858 RTS1C_MC_object_class "TRUE";
BA_ "GenSigVtName" SG_ 1858 RTS1C_MC_object_class "VtSig_RTS1C_MC_object_class";
BA_ "GenSigSendType" SG_ 1858 RTS1C_MC_object_class 1;
BA_ "GenSigSendType" SG_ 1858 RTS1C_MC_positionConfidence 1;
BA_ "GenSigSendType" SG_ 1858 RTS1C_MC_stage_age 1;
BA_ "GenSigSendType" SG_ 1858 RTS1C_MessageCounter 1;
BA_ "GenSigSendType" SG_ 1858 RTS1C_visTrkID 1;
BA_ "GenSigSendType" SG_ 1858 RTS1C_Width 1;
BA_ "GenSigSendType" SG_ 1859 RTS1D_FARcorner_lat 1;
BA_ "GenSigSendType" SG_ 1859 RTS1D_FARcorner_long 1;
BA_ "GenSigSendType" SG_ 1859 RTS1D_LEFTcorner_lat 1;
BA_ "GenSigSendType" SG_ 1859 RTS1D_MessageCounter 1;
BA_ "GenSigSendType" SG_ 1859 RTS1D_RIGHTcorner_lat 1;
BA_ "GenSigSendType" SG_ 1859 RTS1D_RIGHTcorner_long 1;
BA_ "GenSigSendType" SG_ 1861 RTS2A_L_long_rel 1;
BA_ "GenSigVtEn" SG_ 1861 RTS2A_DetectionSensor "TRUE";
BA_ "GenSigVtName" SG_ 1861 RTS2A_DetectionSensor "VtSig_RTS2A_DetectionSensor";
BA_ "GenSigSendType" SG_ 1861 RTS2A_DetectionSensor 1;
BA_ "GenSigSendType" SG_ 1861 RTS2A_L_lat_rel 1;
BA_ "GenSigSendType" SG_ 1861 RTS2A_MessageCounter 1;
BA_ "GenSigSendType" SG_ 1861 RTS2A_Status 1;
BA_ "GenSigSendType" SG_ 1861 RTS2A_TrackID 1;
BA_ "GenSigSendType" SG_ 1861 RTS2A_A_long_obj 1;
VAL_ 3221225472 VIS_LANE_AMBIGUOUS_LANE_RIGHT 1 "detected" 0 "not detected" ;
VAL_ 3221225472 VIS_LANE_AMBIGUOUS_LANE_LEFT 1 "detected" 0 "not detected" ;
VAL_ 3221225472 VIS_LANE_LANE_CHANGE 2 "lane change to the right" 1 "lane change to the left" 0 "no lane change" ;
VAL_ 3221225472 VIS_LANE_RIGHT_INDIVID_LKACONF 3 "best" 2 "good" 1 "middle" 0 "bad" ;
VAL_ 3221225472 VIS_LANE_RIGHT_PARALL_LKACONF 3 "best" 2 "good" 1 "middle" 0 "bad" ;
VAL_ 3221225472 VIS_LANE_LEFT_INDIVID_LKACONF 3 "best" 2 "good" 1 "middle" 0 "bad" ;
VAL_ 3221225472 VIS_LANE_LEFT_PARALL_LKACONF 3 "best" 2 "good" 1 "middle" 0 "bad" ;
VAL_ 3221225472 VIS_LANE_RIGHT_PARALL_TYPE 8 "double lane mark " 7 "undecided" 6 "invalid (no classification)" 5 "reserved" 4 "botts dots" 3 "reserved" 2 "dashed" 1 "solid" 0 "none" ;
VAL_ 3221225472 VIS_LANE_RIGHT_INDIVID_TYPE 8 "double lane mark " 7 "undecided" 6 "invalid (no classification)" 5 "reserved" 4 "botts dots" 3 "reserved" 2 "dashed" 1 "solid" 0 "none" ;
VAL_ 3221225472 VIS_LANE_LEFT_PARALL_TYPE 8 "double lane mark " 7 "undecided" 6 "invalid (no classification)" 5 "reserved" 4 "botts dots" 3 "reserved" 2 "dashed" 1 "solid" 0 "none" ;
VAL_ 3221225472 VIS_LANE_LEFT_INDIVID_TYPE 8 "double lane mark " 7 "undecided" 6 "invalid (no classification)" 5 "reserved" 4 "botts dots" 3 "reserved" 2 "dashed" 1 "solid" 0 "none" ;
VAL_ 3221225472 Latch_Fault_byte19_bit3 0 "No Fault" 1 "Fault Present" ;
VAL_ 3221225472 Latch_Fault_byte20_bit0 0 "No Fault" 1 "Fault Present" ;
VAL_ 3221225472 Latch_Fault_byte19_bit7 0 "No Fault" 1 "Fault Present" ;
VAL_ 3221225472 Latch_Fault_byte19_bit6 0 "No Fault" 1 "Fault Present" ;
VAL_ 3221225472 Latch_Fault_byte19_bit5 0 "No Fault" 1 "Fault Present" ;
VAL_ 3221225472 Latch_Fault_byte19_bit4 0 "No Fault" 1 "Fault Present" ;
VAL_ 3221225472 Latch_Fault_byte19_bit2 0 "No Fault" 1 "Fault Present" ;
VAL_ 3221225472 Latch_Fault_byte19_bit1 0 "No Fault" 1 "Fault Present" ;
VAL_ 3221225472 Latch_Fault_byte19_bit0 0 "No Fault" 1 "Fault Present" ;
VAL_ 3221225472 Latch_Fault_byte18_bit0 0 "No Fault" 1 "Fault Present" ;
VAL_ 3221225472 Latch_Fault_byte18_bit1 0 "No Fault" 1 "Fault Present" ;
VAL_ 3221225472 Latch_Fault_byte18_bit2 0 "No Fault" 1 "Fault Present" ;
VAL_ 3221225472 Latch_Fault_byte18_bit3 0 "No Fault" 1 "Fault Present" ;
VAL_ 3221225472 LaActlDeny_B_ActlQfError 0 "No Fault" 1 "Fault Present" ;
VAL_ 3221225472 Latch_Fault_byte18_bit5 0 "No Fault" 1 "Fault Present" ;
VAL_ 3221225472 Latch_Fault_byte18_bit6 0 "No Fault" 1 "Fault Present" ;
VAL_ 3221225472 Latch_Fault_byte18_bit7 0 "No Fault" 1 "Fault Present" ;
VAL_ 3221225472 Latch_Fault_byte17_bit0 0 "No Fault" 1 "Fault Present" ;
VAL_ 3221225472 Latch_Fault_byte17_bit1 0 "No Fault" 1 "Fault Present" ;
VAL_ 3221225472 Latch_Fault_byte17_bit2 0 "No Fault" 1 "Fault Present" ;
VAL_ 3221225472 Latch_Fault_byte17_bit3 0 "No Fault" 1 "Fault Present" ;
VAL_ 3221225472 Latch_Fault_byte17_bit4 0 "No Fault" 1 "Fault Present" ;
VAL_ 3221225472 Latch_Fault_byte17_bit5 0 "No Fault" 1 "Fault Present" ;
VAL_ 3221225472 Latch_Fault_byte17_bit6 0 "No Fault" 1 "Fault Present" ;
VAL_ 3221225472 Latch_Fault_byte17_bit7 0 "No Fault" 1 "Fault Present" ;
VAL_ 3221225472 Latch_Fault_byte16_bit0 0 "No Fault" 1 "Fault Present" ;
VAL_ 3221225472 Latch_Fault_byte16_bit1 0 "No Fault" 1 "Fault Present" ;
VAL_ 3221225472 Latch_Fault_byte16_bit2 0 "No Fault" 1 "Fault Present" ;
VAL_ 3221225472 Latch_Fault_byte16_bit3 0 "No Fault" 1 "Fault Present" ;
VAL_ 3221225472 Latch_Fault_byte16_bit4 0 "No Fault" 1 "Fault Present" ;
VAL_ 3221225472 Latch_Fault_byte16_bit5 0 "No Fault" 1 "Fault Present" ;
VAL_ 3221225472 Latch_Fault_byte16_bit6 0 "No Fault" 1 "Fault Present" ;
VAL_ 3221225472 Latch_Fault_byte16_bit7 0 "No Fault" 1 "Fault Present" ;
VAL_ 3221225472 Latch_Fault_byte15_bit0 0 "No Fault" 1 "Fault Present" ;
VAL_ 3221225472 Latch_Fault_byte15_bit1 0 "No Present" 1 "Fault Present" ;
VAL_ 3221225472 Latch_Fault_byte15_bit2 0 "No Fault" 1 "Fault Present" ;
VAL_ 3221225472 Latch_Fault_byte15_bit3 0 "No Fault" 1 "Fault Present" ;
VAL_ 3221225472 Latch_Fault_byte15_bit4 0 "No Fault" 1 "Fault Present" ;
VAL_ 3221225472 Latch_Fault_byte15_bit5 0 "No Fault" 1 "Fault Present" ;
VAL_ 3221225472 Latch_Fault_byte15_bit6 0 "No Fault" 1 "Fault Present" ;
VAL_ 3221225472 Latch_Fault_byte15_bit7 0 "No Fault" 1 "Fault Present" ;
VAL_ 3221225472 Latch_Fault_byte14_bit0 0 "No Fault" 1 "Fault Present" ;
VAL_ 3221225472 Latch_Fault_byte14_bit1 0 "No Fault" 1 "Fault Present" ;
VAL_ 3221225472 Latch_Fault_byte14_bit3 0 "No Fault" 1 "Fault Present" ;
VAL_ 3221225472 Latch_Fault_byte14_bit4 0 "No Fault" 1 "Fault Present" ;
VAL_ 3221225472 Latch_Fault_byte14_bit5 0 "No Fault" 1 "Fault Present" ;
VAL_ 3221225472 Latch_Fault_byte14_bit6 0 "No Fault" 1 "Fault Present" ;
VAL_ 3221225472 Latch_Fault_byte14_bit7 0 "No Fault" 1 "Fault Present" ;
VAL_ 3221225472 Active_Fault_byte20_bit0 0 "No Fault" 1 "Fault Present" ;
VAL_ 3221225472 Active_Fault_byte19_bit7 0 "No Fault" 1 "Fault Present" ;
VAL_ 3221225472 Active_Fault_byte19_bit6 0 "No Fault" 1 "Fault Present" ;
VAL_ 3221225472 Active_Fault_byte19_bit5 0 "No Fault" 1 "Fault Present" ;
VAL_ 3221225472 Active_Fault_byte19_bit4 0 "No Fault" 1 "Fault Present" ;
VAL_ 3221225472 Active_Fault_byte19_bit3 0 "No Fault" 1 "Fault Present" ;
VAL_ 3221225472 Active_Fault_byte19_bit2 0 "No Fault" 1 "Fault Present" ;
VAL_ 3221225472 Active_Fault_byte19_bit1 0 "No Fault" 1 "Fault Present" ;
VAL_ 3221225472 Active_Fault_byte19_bit0 0 "No Fault" 1 "Fault Present" ;
VAL_ 3221225472 Active_Fault_byte18_bit0 0 "No Fault" 1 "Fault Present" ;
VAL_ 3221225472 Active_Fault_byte18_bit1 0 "No Fault" 1 "Fault Present" ;
VAL_ 3221225472 Active_Fault_byte18_bit2 0 "No Fault" 1 "Fault Present" ;
VAL_ 3221225472 Active_Fault_byte18_bit3 0 "No Fault" 1 "Fault Present" ;
VAL_ 3221225472 Active_Fault_byte18_bit4 0 "No Fault" 1 "Fault Present" ;
VAL_ 3221225472 Active_Fault_byte18_bit5 0 "No Fault" 1 "Fault Present" ;
VAL_ 3221225472 Active_Fault_byte18_bit6 0 "No Fault" 1 "Fault Present" ;
VAL_ 3221225472 Active_Fault_byte18_bit7 0 "No Fault" 1 "Fault Present" ;
VAL_ 3221225472 Active_Fault_byte17_bit0 0 "No Fault" 1 "Fault Present" ;
VAL_ 3221225472 Active_Fault_byte17_bit1 0 "No Fault" 1 "Fault Present" ;
VAL_ 3221225472 Active_Fault_byte17_bit2 0 "No Fault" 1 "Fault Present" ;
VAL_ 3221225472 Active_Fault_byte17_bit3 0 "No Fault" 1 "Fault Present" ;
VAL_ 3221225472 Active_Fault_byte17_bit4 0 "No Fault" 1 "Fault Present" ;
VAL_ 3221225472 Active_Fault_byte17_bit5 0 "No Fault" 1 "Fault Present" ;
VAL_ 3221225472 Active_Fault_byte17_bit6 0 "No Fault" 1 "Fault Present" ;
VAL_ 3221225472 Active_Fault_byte17_bit7 0 "No Fault" 1 "Fault Present" ;
VAL_ 3221225472 Active_Fault_byte16_bit0 0 "No Fault" 1 "Fault Present" ;
VAL_ 3221225472 Active_Fault_byte16_bit1 0 "No Fault" 1 "Fault Present" ;
VAL_ 3221225472 Active_Fault_byte16_bit2 0 "No Fault" 1 "Fault Present" ;
VAL_ 3221225472 Active_Fault_byte16_bit3 0 "No Fault" 1 "Fault Present" ;
VAL_ 3221225472 Active_Fault_byte16_bit4 0 "No Fault" 1 "Fault Present" ;
VAL_ 3221225472 Active_Fault_byte16_bit5 0 "No Fault" 1 "Fault Present" ;
VAL_ 3221225472 Active_Fault_byte16_bit6 0 "No Fault" 1 "Fault Present" ;
VAL_ 3221225472 Active_Fault_byte16_bit7 0 "No Fault" 1 "Fault Present" ;
VAL_ 3221225472 Active_Fault_byte15_bit0 0 "No Fault" 1 "Fault Present" ;
VAL_ 3221225472 Active_Fault_byte15_bit1 0 "No Fault" 1 "Fault Present" ;
VAL_ 3221225472 Active_Fault_byte15_bit2 0 "No Fault" 1 "Fault Present" ;
VAL_ 3221225472 Active_Fault_byte15_bit3 0 "No Fault" 1 "Fault Present" ;
VAL_ 3221225472 Active_Fault_byte15_bit4 0 "No Fault" 1 "Fault Present" ;
VAL_ 3221225472 Active_Fault_byte15_bit5 0 "No Fault" 1 "Fault Present" ;
VAL_ 3221225472 Active_Fault_byte15_bit6 0 "No Fault" 1 "Fault Present" ;
VAL_ 3221225472 Active_Fault_byte15_bit7 0 "No Fault" 1 "Fault Present" ;
VAL_ 3221225472 Active_Fault_byte14_bit0 0 "No Fault" 1 "Fault Present" ;
VAL_ 3221225472 Active_Fault_byte14_bit1 0 "No Fault" 1 "Fault Present" ;
VAL_ 3221225472 Active_Fault_byte14_bit2 0 "No Fault" 1 "Fault Present" ;
VAL_ 3221225472 Active_Fault_byte14_bit3 0 "No Fault" 1 "Fault Present" ;
VAL_ 3221225472 Active_Fault_byte14_bit4 0 "No Fault" 1 "Fault Present" ;
VAL_ 3221225472 Active_Fault_byte14_bit5 0 "No Fault" 1 "Fault Present" ;
VAL_ 3221225472 Active_Fault_byte14_bit6 0 "No Fault" 1 "Fault Present" ;
VAL_ 3221225472 Active_Fault_byte14_bit7 0 "No Fault" 1 "Fault Present" ;
VAL_ 3221225472 LKA_Handcode_diag 1 "Pass" 0 "Fault" ;
VAL_ 3221225472 heavy_rain_failsafe 0 "No Fault" 1 "Fault Present" ;
VAL_ 3221225472 heavy_rain_failsafe_A 0 "No Fault" 1 "Fault Present" ;
VAL_ 3221225472 History_Fault_bD_0 0 "No Fault" 1 "Fault Present" ;
VAL_ 3221225472 Active_Fault_byteD_bit0 0 "No Fault" 1 "Fault Present" ;
VAL_ 3221225472 History_Fault_H_b10_0 0 "No Fault" 1 "Fault Present" ;
VAL_ 3221225472 History_Fault_H_b10_4 0 "No Fault" 1 "Fault Present" ;
VAL_ 3221225472 History_Fault_H_b10_6 0 "No Fault" 1 "Fault Present" ;
VAL_ 3221225472 History_Fault_H_b10_7 0 "No Fault" 1 "Fault Present" ;
VAL_ 3221225472 History_Fault_b6_2 0 "No Fault" 1 "Fault Present" ;
VAL_ 3221225472 History_Fault_b6_4 0 "No Fault" 1 "Fault Present" ;
VAL_ 3221225472 History_Fault_b1_7 0 "No Fault" 1 "Fault Present" ;
VAL_ 3221225472 History_Fault_b0_0 0 "No Fault" 1 "Fault Present" ;
VAL_ 3221225472 Active_Fault_A_b10_0 0 "No Fault" 1 "Fault Present" ;
VAL_ 3221225472 Active_Fault_A_b10_4 0 "No Fault" 1 "Fault Present" ;
VAL_ 3221225472 Active_Fault_A_b10_6 0 "No Fault" 1 "Fault Present" ;
VAL_ 3221225472 Active_Fault_A_b10_7 0 "No Fault" 1 "Fault Present" ;
VAL_ 3221225472 Active_Fault_b6_2 0 "No Fault" 1 "Fault Present" ;
VAL_ 3221225472 Active_Fault_b6_4 0 "No Fault" 1 "Fault Present" ;
VAL_ 3221225472 Active_Fault_byte1_bit7 0 "No Fault" 1 "Fault Present" ;
VAL_ 3221225472 Active_Fault_byte0_bit0 1 "Fault Present" 0 "No Fault" ;
VAL_ 3221225472 History_Fault_H_bF_4 0 "No Fault" 1 "Fault Present" ;
VAL_ 3221225472 History_Fault_H_bF_5 0 "No Fault" 1 "Fault Present" ;
VAL_ 3221225472 History_Fault_H_bF_6 0 "No Fault" 1 "Fault Present" ;
VAL_ 3221225472 History_Fault_H_bF_7 0 "No Fault" 1 "Fault Present" ;
VAL_ 3221225472 History_Fault_H_bE_7 0 "No Fault" 1 "Fault Present" ;
VAL_ 3221225472 History_Fault_bD_1 0 "No Fault" 1 "Fault Present" ;
VAL_ 3221225472 History_Fault_bD_2 0 "No Fault" 1 "Fault Present" ;
VAL_ 3221225472 History_Fault_bC_0 0 "No Fault" 1 "Fault Present" ;
VAL_ 3221225472 History_Fault_bC_4 0 "No Fault" 1 "Fault Present" ;
VAL_ 3221225472 History_Fault_bC_7 0 "No Fault" 1 "Fault Present" ;
VAL_ 3221225472 History_Fault_bB_7 0 "No Fault" 1 "Fault Present" ;
VAL_ 3221225472 History_Fault_b9_4 0 "No Fault" 1 "Fault Present" ;
VAL_ 3221225472 History_Fault_b9_6 0 "No Fault" 1 "Fault Present" ;
VAL_ 3221225472 History_Fault_b8_0 0 "No Fault" 1 "Fault Present" ;
VAL_ 3221225472 History_Fault_b8_1 0 "No Fault" 1 "Fault Present" ;
VAL_ 3221225472 History_Fault_b8_2 0 "No Fault" 1 "Fault Present" ;
VAL_ 3221225472 Active_Fault_A_bF_4 0 "No Fault" 1 "Fault Present" ;
VAL_ 3221225472 Active_Fault_A_bF_5 0 "No Fault" 1 "Fault Present" ;
VAL_ 3221225472 Active_Fault_A_bF_6 0 "No Fault" 1 "Fault Present" ;
VAL_ 3221225472 Active_Fault_A_bF_7 0 "No Fault" 1 "Fault Present" ;
VAL_ 3221225472 Active_Fault_A_bE_7 0 "No Fault" 1 "Fault Present" ;
VAL_ 3221225472 Active_Fault_byteD_bit1 0 "No Fault" 1 "Fault Present" ;
VAL_ 3221225472 Active_Fault_byteD_bit2 0 "No Fault" 1 "Fault Present" ;
VAL_ 3221225472 Active_Fault_bC_0 0 "No Fault" 1 "Fault Present" ;
VAL_ 3221225472 Active_Fault_byteC_bit4 0 "No Fault" 1 "Fault Present" ;
VAL_ 3221225472 Active_Fault_byteC_bit7 0 "No Fault" 1 "Fault Present" ;
VAL_ 3221225472 Active_Fault_bB_7 0 "No Fault" 1 "Fault Present" ;
VAL_ 3221225472 Active_Fault_b9_4 0 "No Fault" 1 "Fault Present" ;
VAL_ 3221225472 Active_Fault_b9_6 0 "No Fault" 1 "Fault Present" ;
VAL_ 3221225472 Active_Fault_byte8_bit0 1 "Fault Present" 0 "No Fault" ;
VAL_ 3221225472 Active_Fault_byte8_bit1 1 "Fault Present" 0 "No Fault" ;
VAL_ 3221225472 Active_Fault_byte8_bit2 1 "Fault Present" 0 "No Fault" ;
VAL_ 261 Road_Type 3 "Undeifned" 2 "Curve" 1 "Straight" 0 "Unknown" ;
VAL_ 261 Unfilt_Comp_Yaw_Rate_QF 3 "Accurate" 2 "Innacurate" 1 "Temporarily Undefined" 0 "Undefined (faulty)" ;
VAL_ 261 Yaw_Rate_SA_QF 3 "Accurate" 2 "Innacurate" 1 "Temporarily Undefined" 0 "Undefined (faulty)" ;
VAL_ 261 Yaw_Rate_Drifting 1 "Drifting" 0 "Not drifting" ;
VAL_ 16 Mesp_Return_Status 5 "eDES_MESP_STATUS_ILLEGAL_CALL " 4 "eDES_STATUS_SERVICE_INVALID " 3 "eDES_STATUS_INVALID_PARAMETER" 2 "eDES_MESP_BUSY " 1 "eDES_MESP_GENERAL_ERR " 0 "eDES_MESP_STATUS_OK " ;
VAL_ 16 Status_Vision_Calib_Process 8 "DES_BAD_PARAMS_TARGET_HORIZON" 7 "DES_BAD_PARAMS_TARGET_YAW" 6 "DES_TOO_MANY_TARGETS_FOUND" 5 "DES_BAD_PARAMS" 4 "DES_BAD_PARAMS_SQUARE_SIDE_SIZE" 3 "DES_BAD_PARAMS_DISTANCE" 2 "DES_NO_TARGET_FOUND" 1 "DES_SUCCESS" 0 "DES_VISION_CALIB_UNKNOWN" ;
VAL_ 16 VFP_State 134 "eMAIN_STATE_RUNNING_DIAGNOSTICS " 132 "eMAIN_STATE_PENDING_SPC " 130 "eMAIN_STATE_PENDING_TAC " 128 "eMAIN_STATE_PENDING_VISION " 34 "eRUNNING_SPC " 32 "eRUNNING_TAC " 3 "eBOOT " 2 "eRUNNING_VISON " 1 "ePENDING " 0 "eUKNOWN" ;
VAL_ 16 align_current_state 4 "eVISION_APP_MODE" 3 "eWAIT_ALIGN_MSG" 2 "eWAIT_ALIGN_STATE" 1 "eVISION_UNALIGNED" 0 "eALIGNED_IDLE" ;
VAL_ 1940 EH_Slope_Linear_0 1023 "Unknown" ;
VAL_ 1940 EH_Country_Code_0 0 "According to ISO 3166-1" ;
VAL_ 1940 EH_No_Lanes_Drv_Dir_0 7 "unkown" 6 "SixLanesOrMore" 5 "FiveLanes" 4 "FourLanes" 3 "ThreeLanes" 2 "TwoLanes" 1 "OneLane" 0 "DrivingInWrongDirection" ;
VAL_ 1940 EH_Stub_Form_Of_Way_0 15 "N/A" 14 "PedestrianZone" 13 "EntranceToOrExitToService" 12 "EntranceToOrExitOfACarPark" 11 "ServiceRoadOrFrontageRoad" 10 "SlipRoad(notOnFreeway)" 9 "SlipRoad/RampOnAFreeway" 8 "ParallelRoad" 7 "Reserved" 6 "Reserved" 5 "TrafficSquare/TrafficFigure" 4 "RoundaboutCircle" 3 "SingleCarriageway(default)" 2 "MultipleCarriageway" 1 "Freeway/Ramp" 0 "Unknown" ;
VAL_ 1940 EH_Stub_distance_0 0 "Invalid" ;
VAL_ 1940 EH_Eff_Sl_0 31 "N/A" 30 "Unlimited" 29 "160km/h[mph]" 28 "150km/h[mph]" 27 "140km/h[mph]" 26 "130km/h[mph]" 25 "120km/h[mph]" 24 "115km/h[mph]" 23 "110km/h[mph]" 22 "105km/h[mph]" 21 "100km/h[mph]" 20 "95km/h[mph]" 19 "90km/h[mph]" 18 "85km/h[mph]" 17 "80km/h[mph]" 16 "75km/h[mph]" 15 "70km/h[mph]" 14 "65km/h[mph]" 13 "60km/h[mph]" 12 "55km/h[mph]" 11 "50km/h[mph]" 10 "45km/h[mph]" 9 "40km/h[mph]" 8 "35km/h[mph]" 7 "30km/h[mph]" 6 "25km/h[mph]" 5 "20km/h[mph]" 4 "15km/h[mph]" 3 "10km/h[mph]" 2 "7km/h[mph]" 1 "<=5km/h[mph]" 0 "Unknown" ;
VAL_ 1940 EH_Posted_Sl_0 31 "N/A" 30 " Unlimited" 29 "160  km/h [mph]" 28 "150  km/h [mph]" 27 " 140  km/h [mph]" 26 "130  km/h [mph]" 25 "120  km/h [mph]" 24 "115  km/h [mph]" 23 "110  km/h [mph]" 22 "105 km/h [mph]" 21 "100 km/h [mph]" 20 " 95 km/h [mph]" 19 "90  km/h [mph]" 18 "85  km/h [mph]" 17 "80  km/h [mph]" 16 "75  km/h [mph]" 15 "70  km/h [mph]" 14 "65  km/h [mph]" 13 " 60  km/h [mph]" 12 "55  km/h [mph]" 11 " 50  km/h [mph]" 10 " 45  km/h [mph]" 9 "40  km/h [mph]" 8 " 35  km/h [mph]" 7 "30  km/h [mph]" 6 "25  km/h [mph]" 5 "20  km/h [mph]" 4 "15  km/h [mph]" 3 "10  km/h [mph]" 2 " 7  km/h [mph]" 1 "<=5km/h[mph]" 0 "Unknown" ;
VAL_ 1940 EH_off_road 1 "off road" 0 "on road" ;
VAL_ 1698 VIS_TSR_SIGN_VARIABLE_10 1 "yes" 0 "no" ;
VAL_ 1698 VIS_TSR_SIGN_TYPE_10 27 "end of all" 26 "round about" 25 "reserved" 24 "reserved" 23 "reserved" 22 "reserved" 21 "reserved" 20 "no overtaking trucks end" 19 "no overtaking trucks start" 18 "no entrance" 17 "no overtaking end" 16 "no overtaking start" 15 "stop" 14 "low speed area end" 13 "low speed area start" 12 "town end" 11 "town start" 10 "reserved" 9 "reserved" 8 "freeway end" 7 "freeway start" 6 "highway end" 5 "highway start" 4 "reserved" 3 "reserved" 2 "speed limit end" 1 "speed limit start" 0 "unknown" ;
VAL_ 1698 VIS_TSR_SIGN_SUPPL_TYPE2_10 24 "truck and trailer" 23 "distance for AND in" 22 "ice" 21 "end" 20 "bend right" 19 "bend left" 18 "arrow right" 17 "arrow left" 16 "tractor" 15 "truck" 14 "trailer" 13 "zone" 12 "night" 11 "fog" 10 "snow rain" 9 "snow" 8 "rain cloud" 7 "rain" 6 "school" 5 "weight" 4 "time" 3 "distance arrow" 2 "distance" 1 "generic" 0 "none" ;
VAL_ 1698 VIS_TSR_SIGN_SUPPL_TYPE1_10 24 "truck and trailer" 23 "distance for AND in" 22 "ice" 21 "end" 20 "bend right" 19 "bend left" 18 "arrow right" 17 "arrow left" 16 "tractor" 15 "truck" 14 "trailer" 13 "zone" 12 "night" 11 "fog" 10 "snow rain" 9 "snow" 8 "rain cloud" 7 "rain" 6 "school" 5 "weight" 4 "time" 3 "distance arrow" 2 "distance" 1 "generic" 0 "none" ;
VAL_ 1698 VIS_TSR_SIGN_POSITION_10 2 "top" 1 "left" 0 "right" ;
VAL_ 1698 VIS_TSR_SIGN_LANE_10 6 "right lane 2" 5 "right lane 1" 4 "lane host" 3 "left lane 2" 2 "left lane 1" 1 "exit" 0 "none" ;
VAL_ 1698 VIS_TSR_SIGN_EMBEDDED_SCENE_10 1 "yes" 0 "no" ;
VAL_ 1698 VIS_TSR_SCENE_STATUS_10 1 "open" 0 "closed" ;
VAL_ 1697 VIS_TSR_SIGN_VARIABLE_9 1 "yes" 0 "no" ;
VAL_ 1697 VIS_TSR_SIGN_TYPE_9 27 "end of all" 26 "round about" 25 "reserved" 24 "reserved" 23 "reserved" 22 "reserved" 21 "reserved" 20 "no overtaking trucks end" 19 "no overtaking trucks start" 18 "no entrance" 17 "no overtaking end" 16 "no overtaking start" 15 "stop" 14 "low speed area end" 13 "low speed area start" 12 "town end" 11 "town start" 10 "reserved" 9 "reserved" 8 "freeway end" 7 "freeway start" 6 "highway end" 5 "highway start" 4 "reserved" 3 "reserved" 2 "speed limit end" 1 "speed limit start" 0 "unknown" ;
VAL_ 1697 VIS_TSR_SIGN_SUPPL_TYPE2_9 24 "truck and trailer" 23 "distance for AND in" 22 "ice" 21 "end" 20 "bend right" 19 "bend left" 18 "arrow right" 17 "arrow left" 16 "tractor" 15 "truck" 14 "trailer" 13 "zone" 12 "night" 11 "fog" 10 "snow rain" 9 "snow" 8 "rain cloud" 7 "rain" 6 "school" 5 "weight" 4 "time" 3 "distance arrow" 2 "distance" 1 "generic" 0 "none" ;
VAL_ 1697 VIS_TSR_SIGN_SUPPL_TYPE1_9 24 "truck and trailer" 23 "distance for AND in" 22 "ice" 21 "end" 20 "bend right" 19 "bend left" 18 "arrow right" 17 "arrow left" 16 "tractor" 15 "truck" 14 "trailer" 13 "zone" 12 "night" 11 "fog" 10 "snow rain" 9 "snow" 8 "rain cloud" 7 "rain" 6 "school" 5 "weight" 4 "time" 3 "distance arrow" 2 "distance" 1 "generic" 0 "none" ;
VAL_ 1697 VIS_TSR_SIGN_POSITION_9 2 "top" 1 "left" 0 "right" ;
VAL_ 1697 VIS_TSR_SIGN_LANE_9 6 "right lane 2" 5 "right lane 1" 4 "lane host" 3 "left lane 2" 2 "left lane 1" 1 "exit" 0 "none" ;
VAL_ 1697 VIS_TSR_SIGN_EMBEDDED_SCENE_9 1 "yes" 0 "no" ;
VAL_ 1697 VIS_TSR_SCENE_STATUS_9 1 "open" 0 "closed" ;
VAL_ 1696 VIS_TSR_SIGN_VARIABLE_8 1 "yes" 0 "no" ;
VAL_ 1696 VIS_TSR_SIGN_TYPE_8 27 "end of all" 26 "round about" 25 "reserved" 24 "reserved" 23 "reserved" 22 "reserved" 21 "reserved" 20 "no overtaking trucks end" 19 "no overtaking trucks start" 18 "no entrance" 17 "no overtaking end" 16 "no overtaking start" 15 "stop" 14 "low speed area end" 13 "low speed area start" 12 "town end" 11 "town start" 10 "reserved" 9 "reserved" 8 "freeway end" 7 "freeway start" 6 "highway end" 5 "highway start" 4 "reserved" 3 "reserved" 2 "speed limit end" 1 "speed limit start" 0 "unknown" ;
VAL_ 1696 VIS_TSR_SIGN_SUPPL_TYPE2_8 24 "truck and trailer" 23 "distance for AND in" 22 "ice" 21 "end" 20 "bend right" 19 "bend left" 18 "arrow right" 17 "arrow left" 16 "tractor" 15 "truck" 14 "trailer" 13 "zone" 12 "night" 11 "fog" 10 "snow rain" 9 "snow" 8 "rain cloud" 7 "rain" 6 "school" 5 "weight" 4 "time" 3 "distance arrow" 2 "distance" 1 "generic" 0 "none" ;
VAL_ 1696 VIS_TSR_SIGN_SUPPL_TYPE1_8 24 "truck and trailer" 23 "distance for AND in" 22 "ice" 21 "end" 20 "bend right" 19 "bend left" 18 "arrow right" 17 "arrow left" 16 "tractor" 15 "truck" 14 "trailer" 13 "zone" 12 "night" 11 "fog" 10 "snow rain" 9 "snow" 8 "rain cloud" 7 "rain" 6 "school" 5 "weight" 4 "time" 3 "distance arrow" 2 "distance" 1 "generic" 0 "none" ;
VAL_ 1696 VIS_TSR_SIGN_POSITION_8 2 "top" 1 "left" 0 "right" ;
VAL_ 1696 VIS_TSR_SIGN_LANE_8 6 "right lane 2" 5 "right lane 1" 4 "lane host" 3 "left lane 2" 2 "left lane 1" 1 "exit" 0 "none" ;
VAL_ 1696 VIS_TSR_SIGN_EMBEDDED_SCENE_8 1 "yes" 0 "no" ;
VAL_ 1696 VIS_TSR_SCENE_STATUS_8 1 "open" 0 "closed" ;
VAL_ 1695 VIS_TSR_SIGN_VARIABLE_7 1 "yes" 0 "no" ;
VAL_ 1695 VIS_TSR_SIGN_TYPE_7 27 "end of all" 26 "round about" 25 "reserved" 24 "reserved" 23 "reserved" 22 "reserved" 21 "reserved" 20 "no overtaking trucks end" 19 "no overtaking trucks start" 18 "no entrance" 17 "no overtaking end" 16 "no overtaking start" 15 "stop" 14 "low speed area end" 13 "low speed area start" 12 "town end" 11 "town start" 10 "reserved" 9 "reserved" 8 "freeway end" 7 "freeway start" 6 "highway end" 5 "highway start" 4 "reserved" 3 "reserved" 2 "speed limit end" 1 "speed limit start" 0 "unknown" ;
VAL_ 1695 VIS_TSR_SIGN_SUPPL_TYPE2_7 24 "truck and trailer" 23 "distance for AND in" 22 "ice" 21 "end" 20 "bend right" 19 "bend left" 18 "arrow right" 17 "arrow left" 16 "tractor" 15 "truck" 14 "trailer" 13 "zone" 12 "night" 11 "fog" 10 "snow rain" 9 "snow" 8 "rain cloud" 7 "rain" 6 "school" 5 "weight" 4 "time" 3 "distance arrow" 2 "distance" 1 "generic" 0 "none" ;
VAL_ 1695 VIS_TSR_SIGN_SUPPL_TYPE1_7 24 "truck and trailer" 23 "distance for AND in" 22 "ice" 21 "end" 20 "bend right" 19 "bend left" 18 "arrow right" 17 "arrow left" 16 "tractor" 15 "truck" 14 "trailer" 13 "zone" 12 "night" 11 "fog" 10 "snow rain" 9 "snow" 8 "rain cloud" 7 "rain" 6 "school" 5 "weight" 4 "time" 3 "distance arrow" 2 "distance" 1 "generic" 0 "none" ;
VAL_ 1695 VIS_TSR_SIGN_POSITION_7 2 "top" 1 "left" 0 "right" ;
VAL_ 1695 VIS_TSR_SIGN_LANE_7 6 "right lane 2" 5 "right lane 1" 4 "lane host" 3 "left lane 2" 2 "left lane 1" 1 "exit" 0 "none" ;
VAL_ 1695 VIS_TSR_SIGN_EMBEDDED_SCENE_7 1 "yes" 0 "no" ;
VAL_ 1695 VIS_TSR_SCENE_STATUS_7 1 "open" 0 "closed" ;
VAL_ 1694 VIS_TSR_SIGN_VARIABLE_6 1 "yes" 0 "no" ;
VAL_ 1694 VIS_TSR_SIGN_TYPE_6 27 "end of all" 26 "round about" 25 "reserved" 24 "reserved" 23 "reserved" 22 "reserved" 21 "reserved" 20 "no overtaking trucks end" 19 "no overtaking trucks start" 18 "no entrance" 17 "no overtaking end" 16 "no overtaking start" 15 "stop" 14 "low speed area end" 13 "low speed area start" 12 "town end" 11 "town start" 10 "reserved" 9 "reserved" 8 "freeway end" 7 "freeway start" 6 "highway end" 5 "highway start" 4 "reserved" 3 "reserved" 2 "speed limit end" 1 "speed limit start" 0 "unknown" ;
VAL_ 1694 VIS_TSR_SIGN_SUPPL_TYPE2_6 24 "truck and trailer" 23 "distance for AND in" 22 "ice" 21 "end" 20 "bend right" 19 "bend left" 18 "arrow right" 17 "arrow left" 16 "tractor" 15 "truck" 14 "trailer" 13 "zone" 12 "night" 11 "fog" 10 "snow rain" 9 "snow" 8 "rain cloud" 7 "rain" 6 "school" 5 "weight" 4 "time" 3 "distance arrow" 2 "distance" 1 "generic" 0 "none" ;
VAL_ 1694 VIS_TSR_SIGN_SUPPL_TYPE1_6 24 "truck and trailer" 23 "distance for AND in" 22 "ice" 21 "end" 20 "bend right" 19 "bend left" 18 "arrow right" 17 "arrow left" 16 "tractor" 15 "truck" 14 "trailer" 13 "zone" 12 "night" 11 "fog" 10 "snow rain" 9 "snow" 8 "rain cloud" 7 "rain" 6 "school" 5 "weight" 4 "time" 3 "distance arrow" 2 "distance" 1 "generic" 0 "none" ;
VAL_ 1694 VIS_TSR_SIGN_POSITION_6 2 "top" 1 "left" 0 "right" ;
VAL_ 1694 VIS_TSR_SIGN_LANE_6 6 "right lane 2" 5 "right lane 1" 4 "lane host" 3 "left lane 2" 2 "left lane 1" 1 "exit" 0 "none" ;
VAL_ 1694 VIS_TSR_SIGN_EMBEDDED_SCENE_6 1 "yes" 0 "no" ;
VAL_ 1694 VIS_TSR_SCENE_STATUS_6 1 "open" 0 "closed" ;
VAL_ 1693 VIS_TSR_SIGN_VARIABLE_5 1 "yes" 0 "no" ;
VAL_ 1693 VIS_TSR_SIGN_TYPE_5 27 "end of all" 26 "round about" 25 "reserved" 24 "reserved" 23 "reserved" 22 "reserved" 21 "reserved" 20 "no overtaking trucks end" 19 "no overtaking trucks start" 18 "no entrance" 17 "no overtaking end" 16 "no overtaking start" 15 "stop" 14 "low speed area end" 13 "low speed area start" 12 "town end" 11 "town start" 10 "reserved" 9 "reserved" 8 "freeway end" 7 "freeway start" 6 "highway end" 5 "highway start" 4 "reserved" 3 "reserved" 2 "speed limit end" 1 "speed limit start" 0 "unknown" ;
VAL_ 1693 VIS_TSR_SIGN_SUPPL_TYPE2_5 24 "truck and trailer" 23 "distance for AND in" 22 "ice" 21 "end" 20 "bend right" 19 "bend left" 18 "arrow right" 17 "arrow left" 16 "tractor" 15 "truck" 14 "trailer" 13 "zone" 12 "night" 11 "fog" 10 "snow rain" 9 "snow" 8 "rain cloud" 7 "rain" 6 "school" 5 "weight" 4 "time" 3 "distance arrow" 2 "distance" 1 "generic" 0 "none" ;
VAL_ 1693 VIS_TSR_SIGN_SUPPL_TYPE1_5 24 "truck and trailer" 23 "distance for AND in" 22 "ice" 21 "end" 20 "bend right" 19 "bend left" 18 "arrow right" 17 "arrow left" 16 "tractor" 15 "truck" 14 "trailer" 13 "zone" 12 "night" 11 "fog" 10 "snow rain" 9 "snow" 8 "rain cloud" 7 "rain" 6 "school" 5 "weight" 4 "time" 3 "distance arrow" 2 "distance" 1 "generic" 0 "none" ;
VAL_ 1693 VIS_TSR_SIGN_POSITION_5 2 "top" 1 "left" 0 "right" ;
VAL_ 1693 VIS_TSR_SIGN_LANE_5 6 "right lane 2" 5 "right lane 1" 4 "lane host" 3 "left lane 2" 2 "left lane 1" 1 "exit" 0 "none" ;
VAL_ 1693 VIS_TSR_SIGN_EMBEDDED_SCENE_5 1 "yes" 0 "no" ;
VAL_ 1693 VIS_TSR_SCENE_STATUS_5 1 "open" 0 "closed" ;
VAL_ 1692 VIS_TSR_SIGN_VARIABLE_4 1 "yes" 0 "no" ;
VAL_ 1692 VIS_TSR_SIGN_TYPE_4 27 "end of all" 26 "round about" 25 "reserved" 24 "reserved" 23 "reserved" 22 "reserved" 21 "reserved" 20 "no overtaking trucks end" 19 "no overtaking trucks start" 18 "no entrance" 17 "no overtaking end" 16 "no overtaking start" 15 "stop" 14 "low speed area end" 13 "low speed area start" 12 "town end" 11 "town start" 10 "reserved" 9 "reserved" 8 "freeway end" 7 "freeway start" 6 "highway end" 5 "highway start" 4 "reserved" 3 "reserved" 2 "speed limit end" 1 "speed limit start" 0 "unknown" ;
VAL_ 1692 VIS_TSR_SIGN_SUPPL_TYPE2_4 24 "truck and trailer" 23 "distance for AND in" 22 "ice" 21 "end" 20 "bend right" 19 "bend left" 18 "arrow right" 17 "arrow left" 16 "tractor" 15 "truck" 14 "trailer" 13 "zone" 12 "night" 11 "fog" 10 "snow rain" 9 "snow" 8 "rain cloud" 7 "rain" 6 "school" 5 "weight" 4 "time" 3 "distance arrow" 2 "distance" 1 "generic" 0 "none" ;
VAL_ 1692 VIS_TSR_SIGN_SUPPL_TYPE1_4 24 "truck and trailer" 23 "distance for AND in" 22 "ice" 21 "end" 20 "bend right" 19 "bend left" 18 "arrow right" 17 "arrow left" 16 "tractor" 15 "truck" 14 "trailer" 13 "zone" 12 "night" 11 "fog" 10 "snow rain" 9 "snow" 8 "rain cloud" 7 "rain" 6 "school" 5 "weight" 4 "time" 3 "distance arrow" 2 "distance" 1 "generic" 0 "none" ;
VAL_ 1692 VIS_TSR_SIGN_POSITION_4 2 "top" 1 "left" 0 "right" ;
VAL_ 1692 VIS_TSR_SIGN_LANE_4 6 "right lane 2" 5 "right lane 1" 4 "lane host" 3 "left lane 2" 2 "left lane 1" 1 "exit" 0 "none" ;
VAL_ 1692 VIS_TSR_SIGN_EMBEDDED_SCENE_4 1 "yes" 0 "no" ;
VAL_ 1692 VIS_TSR_SCENE_STATUS_4 1 "open" 0 "closed" ;
VAL_ 1691 VIS_TSR_SIGN_VARIABLE_3 1 "yes" 0 "no" ;
VAL_ 1691 VIS_TSR_SIGN_TYPE_3 27 "end of all" 26 "round about" 25 "reserved" 24 "reserved" 23 "reserved" 22 "reserved" 21 "reserved" 20 "no overtaking trucks end" 19 "no overtaking trucks start" 18 "no entrance" 17 "no overtaking end" 16 "no overtaking start" 15 "stop" 14 "low speed area end" 13 "low speed area start" 12 "town end" 11 "town start" 10 "reserved" 9 "reserved" 8 "freeway end" 7 "freeway start" 6 "highway end" 5 "highway start" 4 "reserved" 3 "reserved" 2 "speed limit end" 1 "speed limit start" 0 "unknown" ;
VAL_ 1691 VIS_TSR_SIGN_SUPPL_TYPE2_3 24 "truck and trailer" 23 "distance for AND in" 22 "ice" 21 "end" 20 "bend right" 19 "bend left" 18 "arrow right" 17 "arrow left" 16 "tractor" 15 "truck" 14 "trailer" 13 "zone" 12 "night" 11 "fog" 10 "snow rain" 9 "snow" 8 "rain cloud" 7 "rain" 6 "school" 5 "weight" 4 "time" 3 "distance arrow" 2 "distance" 1 "generic" 0 "none" ;
VAL_ 1691 VIS_TSR_SIGN_SUPPL_TYPE1_3 24 "truck and trailer" 23 "distance for AND in" 22 "ice" 21 "end" 20 "bend right" 19 "bend left" 18 "arrow right" 17 "arrow left" 16 "tractor" 15 "truck" 14 "trailer" 13 "zone" 12 "night" 11 "fog" 10 "snow rain" 9 "snow" 8 "rain cloud" 7 "rain" 6 "school" 5 "weight" 4 "time" 3 "distance arrow" 2 "distance" 1 "generic" 0 "none" ;
VAL_ 1691 VIS_TSR_SIGN_POSITION_3 2 "top" 1 "left" 0 "right" ;
VAL_ 1691 VIS_TSR_SIGN_LANE_3 6 "right lane 2" 5 "right lane 1" 4 "lane host" 3 "left lane 2" 2 "left lane 1" 1 "exit" 0 "none" ;
VAL_ 1691 VIS_TSR_SIGN_EMBEDDED_SCENE_3 1 "yes" 0 "no" ;
VAL_ 1691 VIS_TSR_SCENE_STATUS_3 1 "open" 0 "closed" ;
VAL_ 1690 VIS_TSR_SIGN_VARIABLE_2 1 "yes" 0 "no" ;
VAL_ 1690 VIS_TSR_SIGN_TYPE_2 27 "end of all" 26 "round about" 25 "reserved" 24 "reserved" 23 "reserved" 22 "reserved" 21 "reserved" 20 "no overtaking trucks end" 19 "no overtaking trucks start" 18 "no entrance" 17 "no overtaking end" 16 "no overtaking start" 15 "stop" 14 "low speed area end" 13 "low speed area start" 12 "town end" 11 "town start" 10 "reserved" 9 "reserved" 8 "freeway end" 7 "freeway start" 6 "highway end" 5 "highway start" 4 "reserved" 3 "reserved" 2 "speed limit end" 1 "speed limit start" 0 "unknown" ;
VAL_ 1690 VIS_TSR_SIGN_SUPPL_TYPE2_2 24 "truck and trailer" 23 "distance for AND in" 22 "ice" 21 "end" 20 "bend right" 19 "bend left" 18 "arrow right" 17 "arrow left" 16 "tractor" 15 "truck" 14 "trailer" 13 "zone" 12 "night" 11 "fog" 10 "snow rain" 9 "snow" 8 "rain cloud" 7 "rain" 6 "school" 5 "weight" 4 "time" 3 "distance arrow" 2 "distance" 1 "generic" 0 "none" ;
VAL_ 1690 VIS_TSR_SIGN_SUPPL_TYPE1_2 24 "truck and trailer" 23 "distance for AND in" 22 "ice" 21 "end" 20 "bend right" 19 "bend left" 18 "arrow right" 17 "arrow left" 16 "tractor" 15 "truck" 14 "trailer" 13 "zone" 12 "night" 11 "fog" 10 "snow rain" 9 "snow" 8 "rain cloud" 7 "rain" 6 "school" 5 "weight" 4 "time" 3 "distance arrow" 2 "distance" 1 "generic" 0 "none" ;
VAL_ 1690 VIS_TSR_SIGN_POSITION_2 2 "top" 1 "left" 0 "right" ;
VAL_ 1690 VIS_TSR_SIGN_LANE_2 6 "right lane 2" 5 "right lane 1" 4 "lane host" 3 "left lane 2" 2 "left lane 1" 1 "exit" 0 "none" ;
VAL_ 1690 VIS_TSR_SIGN_EMBEDDED_SCENE_2 1 "yes" 0 "no" ;
VAL_ 1690 VIS_TSR_SCENE_STATUS_2 1 "open" 0 "closed" ;
VAL_ 1027 P1C_Object_class 10 "unidentified vehicle" 9 "bicycle" 8 "general on-road object" 7 "animal" 6 "tree" 5 "pole" 4 "pedestrian" 3 "truck" 2 "motorcycle" 1 "car" 0 "undetermined" ;
VAL_ 1888 RT1A_DetectionSensor 3 "tracklets and vision" 2 "vision only" 1 "multiple tracklets" 0 "single tracklet" ;
VAL_ 1889 RT1B_Status 6 "coasted" 5 "updated" 4 "new updated" 3 "new coasted" 2 "new" 1 "merged" 0 "invalid" ;
VAL_ 1894 RT2B_Status 6 "coasted" 5 "updated" 4 "new updated" 3 "new coasted" 2 "new" 1 "merged" 0 "invalid" ;
VAL_ 1898 RT3A_DetectionSensor 3 "tracklets and vision" 2 "vision only" 1 "multiple tracklets" 0 "single tracklet" ;
VAL_ 1899 RT3B_Status 6 "coasted" 5 "updated" 4 "new updated" 3 "new coasted" 2 "new" 1 "merged" 0 "invalid" ;
VAL_ 1900 RT3C_MC_object_class 10 "unidentified vehicle" 9 "bicycle" 8 "general on-road object" 7 "animal" 6 "tree" 5 "pole" 4 "pedestrian" 3 "truck" 2 "motorcycle" 1 "car" 0 "undetermined" ;
VAL_ 1903 RT4A_DetectionSensor 3 "tracklets and vision" 2 "vision only" 1 "multiple tracklets" 0 "single tracklet" ;
VAL_ 1904 RT4B_Status 6 "coasted" 5 "updated" 4 "new updated" 3 "new coasted" 2 "new" 1 "merged" 0 "invalid" ;
VAL_ 1905 RT4C_MC_object_class 10 "unidentified vehicle" 9 "bicycle" 8 "general on-road object" 7 "animal" 6 "tree" 5 "pole" 4 "pedestrian" 3 "truck" 2 "motorcycle" 1 "car" 0 "undetermined" ;
VAL_ 1908 RT5A_DetectionSensor 3 "tracklets and vision" 2 "vision only" 1 "multiple tracklets" 0 "single tracklet" ;
VAL_ 1909 RT5B_Status 6 "coasted" 5 "updated" 4 "new updated" 3 "new coasted" 2 "new" 1 "merged" 0 "invalid" ;
VAL_ 1910 RT5C_MC_object_class 10 "unidentified vehicle" 9 "bicycle" 8 "general on-road object" 7 "animal" 6 "tree" 5 "pole" 4 "pedestrian" 3 "truck" 2 "motorcycle" 1 "car" 0 "undetermined" ;
VAL_ 1913 RT6A_DetectionSensor 3 "tracklets and vision" 2 "vision only" 1 "multiple tracklets" 0 "single tracklet" ;
VAL_ 1914 RT6B_Status 6 "coasted" 5 "updated" 4 "new updated" 3 "new coasted" 2 "new" 1 "merged" 0 "invalid" ;
VAL_ 1915 RT6C_MC_object_class 10 "unidentified vehicle" 9 "bicycle" 8 "general on-road object" 7 "animal" 6 "tree" 5 "pole" 4 "pedestrian" 3 "truck" 2 "motorcycle" 1 "car" 0 "undetermined" ;
VAL_ 1856 RTS1A_DetectionSensor 3 "tracklets and vision" 2 "vision only" 1 "multiple tracklets" 0 "single tracklet" ;
VAL_ 1856 RTS1A_Status 6 "coasted" 5 "updated" 4 "new updated" 3 "new coasted" 2 "new" 1 "merged" 0 "invalid" ;
VAL_ 1858 RTS1C_MC_object_class 10 "unidentified vehicle" 9 "bicycle" 8 "general on-road object" 7 "animal" 6 "tree" 5 "pole" 4 "pedestrian" 3 "truck" 2 "motorcycle" 1 "car" 0 "undetermined" ;
VAL_ 1861 RTS2A_DetectionSensor 3 "tracklets and vision" 2 "vision only" 1 "multiple tracklets" 0 "single tracklet" ;
